VERSION ""

NS_ :

BS_:

BU_: EBS EMS

BO_ 2566836222 DM06: 22 Vector__XXX
 SG_ SPN_High4 : 133|3@1+ (1,0) [0|7] "" Vector__XXX
 SG_ SPN_High3 : 101|3@1+ (1,0) [0|7] "" Vector__XXX
 SG_ SPN_High5 : 165|3@1+ (1,0) [0|7] "" Vector__XXX
 SG_ SPN_High2 : 69|3@1+ (1,0) [0|7] "" Vector__XXX
 SG_ SPN_High1 : 37|3@1+ (1,0) [0|7] "" Vector__XXX
 SG_ SpnConversionMethod1 : 47|1@1+ (1,0) [0|1] "" Vector__XXX
 SG_ SpnConversionMethod5 : 175|1@1+ (1,0) [0|1] "" Vector__XXX
 SG_ SpnConversionMethod4 : 143|1@1+ (1,0) [0|1] "" Vector__XXX
 SG_ SpnConversionMethod3 : 111|1@1+ (1,0) [0|1] "" Vector__XXX
 SG_ SpnConversionMethod2 : 79|1@1+ (1,0) [0|1] "" Vector__XXX
 SG_ OccurenceCount5 : 168|7@1+ (1,0) [0|127] "" Vector__XXX
 SG_ OccurenceCount4 : 136|7@1+ (1,0) [0|127] "" Vector__XXX
 SG_ OccurenceCount3 : 104|7@1+ (1,0) [0|127] "" Vector__XXX
 SG_ OccurenceCount2 : 72|7@1+ (1,0) [0|127] "" Vector__XXX
 SG_ OccurenceCount1 : 40|7@1+ (1,0) [0|127] "" Vector__XXX
 SG_ FMI5 : 160|5@1+ (1,0) [0|31] "" Vector__XXX
 SG_ FMI4 : 128|5@1+ (1,0) [0|31] "" Vector__XXX
 SG_ FMI3 : 96|5@1+ (1,0) [0|31] "" Vector__XXX
 SG_ FMI2 : 64|5@1+ (1,0) [0|31] "" Vector__XXX
 SG_ FMI1 : 32|5@1+ (1,0) [0|31] "" Vector__XXX
 SG_ FlashRedStopLamp : 12|2@1+ (1,0) [0|3] "" Vector__XXX
 SG_ FlashProtectLamp : 8|2@1+ (1,0) [0|3] "" Vector__XXX
 SG_ FlashMalfuncIndicatorLamp : 14|2@1+ (1,0) [0|3] "" Vector__XXX
 SG_ FlashAmberWarningLamp : 10|2@1+ (1,0) [0|3] "" Vector__XXX
 SG_ MalfunctionIndLampStatus : 6|2@1+ (1,0) [0|3] "" Vector__XXX
 SG_ AmberWarningLampStatus : 2|2@1+ (1,0) [0|3] "" Vector__XXX
 SG_ RedStopLampState : 4|2@1+ (1,0) [0|3] "" Vector__XXX
 SG_ ProtectLampStatus : 0|2@1+ (1,0) [0|3] "" Vector__XXX
 SG_ SPN5 : 144|16@1+ (1,0) [0|524287] "" Vector__XXX
 SG_ SPN4 : 112|16@1+ (1,0) [0|524287] "" Vector__XXX
 SG_ SPN3 : 80|16@1+ (1,0) [0|524287] "" Vector__XXX
 SG_ SPN2 : 48|16@1+ (1,0) [0|524287] "" Vector__XXX
 SG_ SPN1 : 16|16@1+ (1,0) [0|524287] "" Vector__XXX

BO_ 2566835966 DM05: 8 Vector__XXX
 SG_ NOxConvertingCatAdsorberStatus : 59|1@1+ (1,0) [0|1] "" Vector__XXX
 SG_ NOxConvertingCatAdsorberSupport : 43|1@1+ (1,0) [0|1] "" Vector__XXX
 SG_ BoostPressureControlSystemStatus : 57|1@1+ (1,0) [0|1] "" Vector__XXX
 SG_ DieselParticulateFilterStatus : 58|1@1+ (1,0) [0|1] "" Vector__XXX
 SG_ NMHCConvertingCatalystStatus : 60|1@1+ (1,0) [0|1] "" Vector__XXX
 SG_ BoostPressureControlSystemSuppor : 41|1@1+ (1,0) [0|1] "" Vector__XXX
 SG_ DieselParticulateFilterSupport : 42|1@1+ (1,0) [0|1] "" Vector__XXX
 SG_ NMHCConvertingCatalystSupport : 44|1@1+ (1,0) [0|1] "" Vector__XXX
 SG_ MisfireMonitoringSupport : 24|1@1+ (1,0) [0|0] "" Vector__XXX
 SG_ OBDCompliance : 16|8@1+ (1,0) [0|250] "" Vector__XXX
 SG_ PreviouslyActiveTroubleCodes : 8|8@1+ (1,0) [0|250] "" Vector__XXX
 SG_ ActiveTroubleCodes : 0|8@1+ (1,0) [0|250] "" Vector__XXX
 SG_ SecondAirSystemMonStatus : 51|1@1+ (1,0) [0|1] "" Vector__XXX
 SG_ EvaporativeSystemMonStatus : 50|1@1+ (1,0) [0|1] "" Vector__XXX
 SG_ ACSystemRefrigerantMonStatus : 52|1@1+ (1,0) [0|1] "" Vector__XXX
 SG_ OxygenSensorHeaterMonStatus : 54|1@1+ (1,0) [0|1] "" Vector__XXX
 SG_ OxygenSensorMonStatus : 53|1@1+ (1,0) [0|1] "" Vector__XXX
 SG_ EGRSystemMonitoringStatus : 55|1@1+ (1,0) [0|1] "" Vector__XXX
 SG_ CatalystMonStatus : 48|1@1+ (1,0) [0|1] "" Vector__XXX
 SG_ ColdStartAidSystemMonStatus : 56|1@1+ (1,0) [0|1] "" Vector__XXX
 SG_ HeatedCatalystMonStatus : 49|1@1+ (1,0) [0|0] "" Vector__XXX
 SG_ CatalystMonSupp : 32|1@1+ (1,0) [0|1] "" Vector__XXX
 SG_ ColdStartAidSystemMonSupp : 40|1@1+ (1,0) [0|1] "" Vector__XXX
 SG_ HeatedCatalystMonSupp : 33|1@1+ (1,0) [0|0] "" Vector__XXX
 SG_ EvaporativeSystemMonSupp : 34|1@1+ (1,0) [0|1] "" Vector__XXX
 SG_ SecondAirSystemMonSupp : 35|1@1+ (1,0) [0|1] "" Vector__XXX
 SG_ ACSystemRefrigerantMonSupp : 36|1@1+ (1,0) [0|1] "" Vector__XXX
 SG_ OxygenSensorMonSupp : 37|1@1+ (1,0) [0|1] "" Vector__XXX
 SG_ OxygenSensorHeaterMonSupp : 38|1@1+ (1,0) [0|1] "" Vector__XXX
 SG_ EGRSystemMonitoringSupp : 39|1@1+ (1,0) [0|1] "" Vector__XXX
 SG_ MisfireMonitoringStatus : 28|1@1+ (1,0) [0|0] "" Vector__XXX
 SG_ ComprehensiveCompMonStatus : 30|1@1+ (1,0) [0|1] "" Vector__XXX
 SG_ FuelSystemMonitoringStatus : 29|1@1+ (1,0) [0|1] "" Vector__XXX
 SG_ ComprehensiveComponentMonSupp : 26|1@1+ (1,0) [0|0] "" Vector__XXX
 SG_ FuelSystemMonitoringSupport : 25|1@1+ (1,0) [0|1] "" Vector__XXX

BO_ 2566835710 DM04: 13 Vector__XXX
 SG_ SpnConversionMethod : 39|1@1+ (1,0) [0|1] "" Vector__XXX
 SG_ OccurenceCount : 32|7@1+ (1,0) [0|127] "" Vector__XXX
 SG_ SPN_High : 29|3@1+ (1,0) [0|7] "" Vector__XXX
 SG_ FMI : 24|5@1+ (1,0) [0|31] "" Vector__XXX
 SG_ EngineIntakeManifold1Pressure : 48|8@1+ (2,0) [0|500] "kPa" Vector__XXX
 SG_ FreezeFrameLength : 0|8@1+ (1,0) [0|255] "" Vector__XXX
 SG_ Speed : 56|16@1+ (0.125,0) [0|8031.875] "rpm" Vector__XXX
 SG_ TorqueMode : 40|4@1+ (1,0) [0|15] "" Vector__XXX
 SG_ WheelBasedVS : 88|16@1+ (0.00390625,0) [0|250.99609375] "km/h" Vector__XXX
 SG_ PercentLoadAtCurrentSpeed : 72|8@1+ (1,0) [0|125] "%" Vector__XXX
 SG_ CoolantTemperature : 80|8@1+ (1,-40) [-40|210] "°C" Vector__XXX
 SG_ SPN : 8|16@1+ (1,0) [0|524287] "" Vector__XXX

BO_ 2566835454 DM03: 0 Vector__XXX

BO_ 2566835198 DM02: 22 Vector__XXX
 SG_ SPN_High4 : 133|3@1+ (1,0) [0|7] "" Vector__XXX
 SG_ SPN_High3 : 101|3@1+ (1,0) [0|7] "" Vector__XXX
 SG_ SPN_High5 : 165|3@1+ (1,0) [0|7] "" Vector__XXX
 SG_ SPN_High2 : 69|3@1+ (1,0) [0|7] "" Vector__XXX
 SG_ SPN_High1 : 37|3@1+ (1,0) [0|7] "" Vector__XXX
 SG_ SpnConversionMethod1 : 47|1@1+ (1,0) [0|1] "" Vector__XXX
 SG_ SpnConversionMethod5 : 175|1@1+ (1,0) [0|1] "" Vector__XXX
 SG_ SpnConversionMethod4 : 143|1@1+ (1,0) [0|1] "" Vector__XXX
 SG_ SpnConversionMethod3 : 111|1@1+ (1,0) [0|1] "" Vector__XXX
 SG_ SpnConversionMethod2 : 79|1@1+ (1,0) [0|1] "" Vector__XXX
 SG_ OccurenceCount5 : 168|7@1+ (1,0) [0|127] "" Vector__XXX
 SG_ OccurenceCount4 : 136|7@1+ (1,0) [0|127] "" Vector__XXX
 SG_ OccurenceCount3 : 104|7@1+ (1,0) [0|127] "" Vector__XXX
 SG_ OccurenceCount2 : 72|7@1+ (1,0) [0|127] "" Vector__XXX
 SG_ OccurenceCount1 : 40|7@1+ (1,0) [0|127] "" Vector__XXX
 SG_ FMI5 : 160|5@1+ (1,0) [0|31] "" Vector__XXX
 SG_ FMI4 : 128|5@1+ (1,0) [0|31] "" Vector__XXX
 SG_ FMI3 : 96|5@1+ (1,0) [0|31] "" Vector__XXX
 SG_ FMI2 : 64|5@1+ (1,0) [0|31] "" Vector__XXX
 SG_ FMI1 : 32|5@1+ (1,0) [0|31] "" Vector__XXX
 SG_ FlashRedStopLamp : 12|2@1+ (1,0) [0|3] "" Vector__XXX
 SG_ FlashProtectLamp : 8|2@1+ (1,0) [0|3] "" Vector__XXX
 SG_ FlashMalfuncIndicatorLamp : 14|2@1+ (1,0) [0|3] "" Vector__XXX
 SG_ FlashAmberWarningLamp : 10|2@1+ (1,0) [0|3] "" Vector__XXX
 SG_ MalfunctionIndLampStatus : 6|2@1+ (1,0) [0|3] "" Vector__XXX
 SG_ AmberWarningLampStatus : 2|2@1+ (1,0) [0|3] "" Vector__XXX
 SG_ RedStopLampState : 4|2@1+ (1,0) [0|3] "" Vector__XXX
 SG_ ProtectLampStatus : 0|2@1+ (1,0) [0|3] "" Vector__XXX
 SG_ SPN5 : 144|16@1+ (1,0) [0|524287] "" Vector__XXX
 SG_ SPN4 : 112|16@1+ (1,0) [0|524287] "" Vector__XXX
 SG_ SPN3 : 80|16@1+ (1,0) [0|524287] "" Vector__XXX
 SG_ SPN2 : 48|16@1+ (1,0) [0|524287] "" Vector__XXX
 SG_ SPN1 : 16|16@1+ (1,0) [0|524287] "" Vector__XXX

BO_ 2566834942 DM01: 22 Vector__XXX
 SG_ SPN_High4 : 133|3@1+ (1,0) [0|7] "" Vector__XXX
 SG_ SPN_High3 : 101|3@1+ (1,0) [0|7] "" Vector__XXX
 SG_ SPN_High5 : 165|3@1+ (1,0) [0|7] "" Vector__XXX
 SG_ SPN_High2 : 69|3@1+ (1,0) [0|7] "" Vector__XXX
 SG_ SPN_High1 : 37|3@1+ (1,0) [0|7] "" Vector__XXX
 SG_ SpnConversionMethod1 : 47|1@1+ (1,0) [0|1] "" Vector__XXX
 SG_ SpnConversionMethod5 : 175|1@1+ (1,0) [0|1] "" Vector__XXX
 SG_ SpnConversionMethod4 : 143|1@1+ (1,0) [0|1] "" Vector__XXX
 SG_ SpnConversionMethod3 : 111|1@1+ (1,0) [0|1] "" Vector__XXX
 SG_ SpnConversionMethod2 : 79|1@1+ (1,0) [0|1] "" Vector__XXX
 SG_ OccurenceCount5 : 168|7@1+ (1,0) [0|127] "" Vector__XXX
 SG_ OccurenceCount4 : 136|7@1+ (1,0) [0|127] "" Vector__XXX
 SG_ OccurenceCount3 : 104|7@1+ (1,0) [0|127] "" Vector__XXX
 SG_ OccurenceCount2 : 72|7@1+ (1,0) [0|127] "" Vector__XXX
 SG_ OccurenceCount1 : 40|7@1+ (1,0) [0|127] "" Vector__XXX
 SG_ FMI5 : 160|5@1+ (1,0) [0|31] "" Vector__XXX
 SG_ FMI4 : 128|5@1+ (1,0) [0|31] "" Vector__XXX
 SG_ FMI3 : 96|5@1+ (1,0) [0|31] "" Vector__XXX
 SG_ FMI2 : 64|5@1+ (1,0) [0|31] "" Vector__XXX
 SG_ FMI1 : 32|5@1+ (1,0) [0|31] "" Vector__XXX
 SG_ FlashRedStopLamp : 12|2@1+ (1,0) [0|3] "" Vector__XXX
 SG_ FlashProtectLamp : 8|2@1+ (1,0) [0|3] "" Vector__XXX
 SG_ FlashMalfuncIndicatorLamp : 14|2@1+ (1,0) [0|3] "" Vector__XXX
 SG_ FlashAmberWarningLamp : 10|2@1+ (1,0) [0|3] "" Vector__XXX
 SG_ MalfunctionIndLampStatus : 6|2@1+ (1,0) [0|3] "" Vector__XXX
 SG_ AmberWarningLampStatus : 2|2@1+ (1,0) [0|3] "" Vector__XXX
 SG_ RedStopLampState : 4|2@1+ (1,0) [0|3] "" Vector__XXX
 SG_ ProtectLampStatus : 0|2@1+ (1,0) [0|3] "" Vector__XXX
 SG_ SPN5 : 144|16@1+ (1,0) [0|524287] "" Vector__XXX
 SG_ SPN4 : 112|16@1+ (1,0) [0|524287] "" Vector__XXX
 SG_ SPN3 : 80|16@1+ (1,0) [0|524287] "" Vector__XXX
 SG_ SPN2 : 48|16@1+ (1,0) [0|524287] "" Vector__XXX
 SG_ SPN1 : 16|16@1+ (1,0) [0|524287] "" Vector__XXX

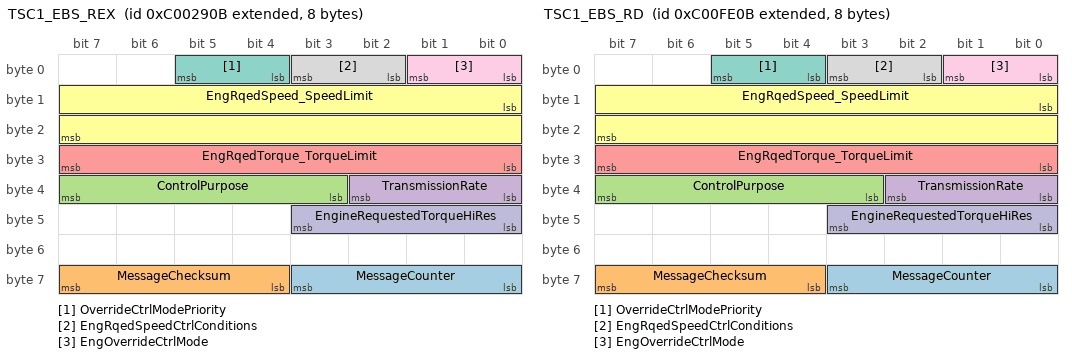
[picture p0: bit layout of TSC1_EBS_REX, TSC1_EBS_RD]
BO_ 2348820747 TSC1_EBS_REX: 8 EBS
 SG_ MessageCounter : 56|4@1+ (1,0) [0|15] "" Vector__XXX
 SG_ MessageChecksum : 60|4@1+ (1,0) [0|15] "" Vector__XXX
 SG_ ControlPurpose : 35|5@1+ (1,0) [0|31] "" Vector__XXX
 SG_ TransmissionRate : 32|3@1+ (1,0) [0|7] "" Vector__XXX
 SG_ EngRqedTorque_TorqueLimit : 24|8@1+ (1,-125) [-125|125] "%" Vector__XXX
 SG_ EngRqedSpeed_SpeedLimit : 8|16@1+ (0.125,0) [0|8031.875] "RPM" Vector__XXX
 SG_ OverrideCtrlModePriority : 4|2@1+ (1,0) [0|3] "" Vector__XXX
 SG_ EngRqedSpeedCtrlConditions : 2|2@1+ (1,0) [0|3] "" Vector__XXX
 SG_ EngOverrideCtrlMode : 0|2@1+ (1,0) [0|3] "" Vector__XXX
 SG_ EngineRequestedTorqueHiRes : 40|4@1+ (0.125,0) [0|0.875] "%" Vector__XXX

BO_ 2348875275 TSC1_EBS_RD: 8 EBS
 SG_ MessageCounter : 56|4@1+ (1,0) [0|15] "" Vector__XXX
 SG_ MessageChecksum : 60|4@1+ (1,0) [0|15] "" Vector__XXX
 SG_ ControlPurpose : 35|5@1+ (1,0) [0|31] "" Vector__XXX
 SG_ TransmissionRate : 32|3@1+ (1,0) [0|7] "" Vector__XXX
 SG_ EngRqedTorque_TorqueLimit : 24|8@1+ (1,-125) [-125|125] "%" Vector__XXX
 SG_ EngRqedSpeed_SpeedLimit : 8|16@1+ (0.125,0) [0|8031.875] "RPM" Vector__XXX
 SG_ OverrideCtrlModePriority : 4|2@1+ (1,0) [0|3] "" Vector__XXX
 SG_ EngRqedSpeedCtrlConditions : 2|2@1+ (1,0) [0|3] "" Vector__XXX
 SG_ EngOverrideCtrlMode : 0|2@1+ (1,0) [0|3] "" Vector__XXX
 SG_ EngineRequestedTorqueHiRes : 40|4@1+ (0.125,0) [0|0.875] "%" Vector__XXX

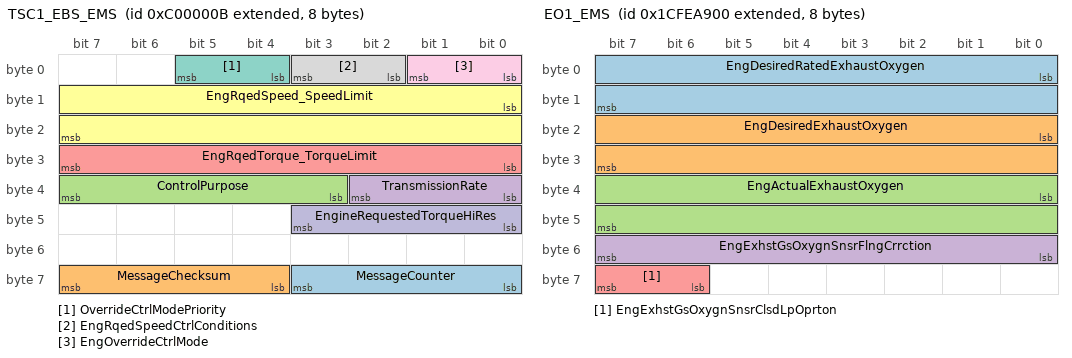
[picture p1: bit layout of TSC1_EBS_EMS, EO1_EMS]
BO_ 2348810251 TSC1_EBS_EMS: 8 EBS
 SG_ MessageCounter : 56|4@1+ (1,0) [0|15] "" Vector__XXX
 SG_ MessageChecksum : 60|4@1+ (1,0) [0|15] "" Vector__XXX
 SG_ ControlPurpose : 35|5@1+ (1,0) [0|31] ""  EMS
 SG_ TransmissionRate : 32|3@1+ (1,0) [0|7] "" Vector__XXX
 SG_ EngRqedTorque_TorqueLimit : 24|8@1+ (1,-125) [-125|125] "%"  EMS
 SG_ EngRqedSpeed_SpeedLimit : 8|16@1+ (0.125,0) [0|8031.875] "RPM"  EMS
 SG_ OverrideCtrlModePriority : 4|2@1+ (1,0) [0|3] ""  EMS
 SG_ EngRqedSpeedCtrlConditions : 2|2@1+ (1,0) [0|3] "" Vector__XXX
 SG_ EngOverrideCtrlMode : 0|2@1+ (1,0) [0|3] ""  EMS
 SG_ EngineRequestedTorqueHiRes : 40|4@1+ (0.125,0) [0|0.875] "%" Vector__XXX

BO_ 2632943012 CAPL_MSG: 1785 Vector__XXX

BO_ 2633935104 EO1_EMS: 8 EMS
 SG_ EngDesiredRatedExhaustOxygen : 0|16@1+ (0.0025,0) [0|160.6375] "%" Vector__XXX
 SG_ EngDesiredExhaustOxygen : 16|16@1+ (0.0025,0) [0|160.6375] "%" Vector__XXX
 SG_ EngActualExhaustOxygen : 32|16@1+ (0.0025,0) [0|160.6375] "%" Vector__XXX
 SG_ EngExhstGsOxygnSnsrFlngCrrction : 48|8@1+ (1,-125) [-125|125] "%" Vector__XXX
 SG_ EngExhstGsOxygnSnsrClsdLpOprton : 62|2@1+ (1,0) [0|3] "" Vector__XXX

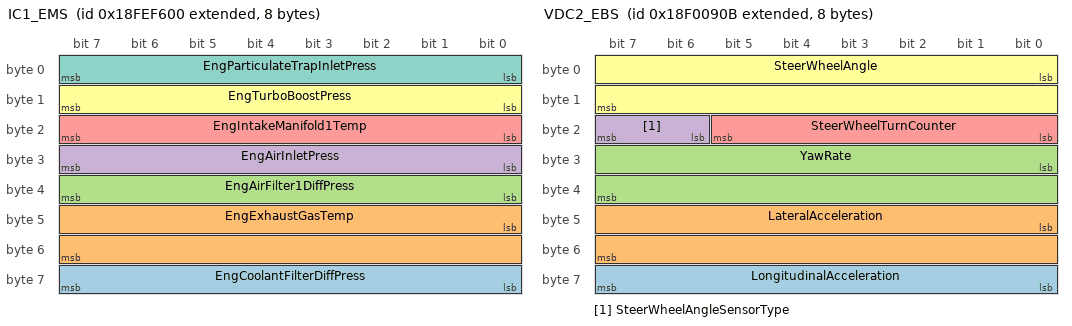
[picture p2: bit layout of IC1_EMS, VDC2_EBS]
BO_ 2566845952 IC1_EMS: 8 EMS
 SG_ EngCoolantFilterDiffPress : 56|8@1+ (0.5,0) [0|125] "kPa" Vector__XXX
 SG_ EngExhaustGasTemp : 40|16@1+ (0.03125,-273) [-273|1735] "°C" Vector__XXX
 SG_ EngAirFilter1DiffPress : 32|8@1+ (0.05,0) [0|12.5] "kPa" Vector__XXX
 SG_ EngAirInletPress : 24|8@1+ (2,0) [0|500] "kPa" Vector__XXX
 SG_ EngIntakeManifold1Temp : 16|8@1+ (1,-40) [-40|210] "°C" Vector__XXX
 SG_ EngTurboBoostPress : 8|8@1+ (2,0) [0|500] "kPa" Vector__XXX
 SG_ EngParticulateTrapInletPress : 0|8@1+ (0.5,0) [0|125] "kPa" Vector__XXX

BO_ 2566841600 HOURS_EMS: 8 EMS
 SG_ EngTotalRevolutions : 32|32@1+ (1000,0) [0|4211081215000] "rev" Vector__XXX
 SG_ EngTotalHoursOfOperation : 0|32@1+ (0.05,0) [0|210554060.75] "hr" Vector__XXX

BO_ 2566843392 VI_EMS: 8 EMS
 SG_ VehicleIdentificationNumber : 0|8@1+ (1,0) [0|255] "" Vector__XXX

BO_ 2566832384 VDHR_EMS: 8 EMS
 SG_ HighResolutionTripDistance : 32|32@1+ (0.005,0) [0|21055406] "km" Vector__XXX
 SG_ HghRslutionTotalVehicleDistance : 0|32@1+ (0.005,0) [0|21055406] "km" Vector__XXX

BO_ 2565867787 VDC2_EBS: 8 EBS
 SG_ LongitudinalAcceleration : 56|8@1+ (0.1,-12.5) [-12.5|12.5] "m/s²" Vector__XXX
 SG_ LateralAcceleration : 40|16@1+ (0.000488281,-15.687) [-15.687|15.687] "m/s²" Vector__XXX
 SG_ YawRate : 24|16@1+ (0.00012207,-3.92) [-3.92|3.92] "rad/s" Vector__XXX
 SG_ SteerWheelAngleSensorType : 22|2@1+ (1,0) [0|3] "" Vector__XXX
 SG_ SteerWheelTurnCounter : 16|6@1+ (1,-32) [-32|29] "turns" Vector__XXX
 SG_ SteerWheelAngle : 0|16@1+ (0.000976563,-31.374) [-31.374|31.374] "rad" Vector__XXX

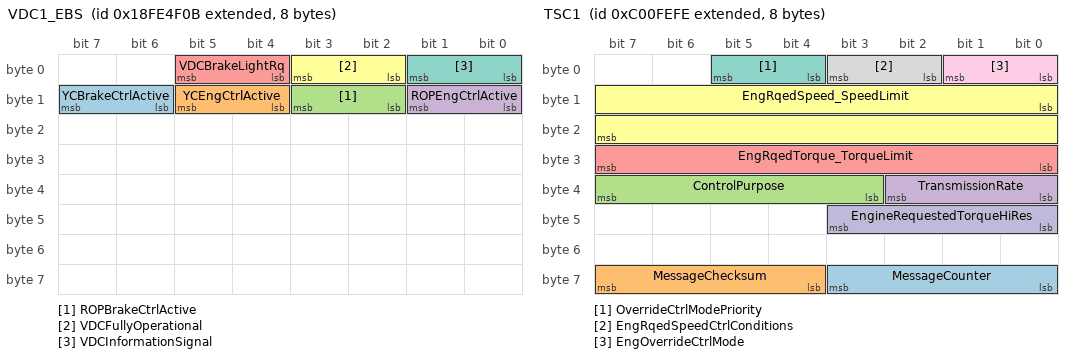
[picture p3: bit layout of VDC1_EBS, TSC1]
BO_ 2566803211 VDC1_EBS: 8 EBS
 SG_ YCBrakeCtrlActive : 14|2@1+ (1,0) [0|3] "" Vector__XXX
 SG_ YCEngCtrlActive : 12|2@1+ (1,0) [0|3] "" Vector__XXX
 SG_ ROPBrakeCtrlActive : 10|2@1+ (1,0) [0|3] "" Vector__XXX
 SG_ ROPEngCtrlActive : 8|2@1+ (1,0) [0|3] "" Vector__XXX
 SG_ VDCBrakeLightRq : 4|2@1+ (1,0) [0|3] "" Vector__XXX
 SG_ VDCFullyOperational : 2|2@1+ (1,0) [0|3] "" Vector__XXX
 SG_ VDCInformationSignal : 0|2@1+ (1,0) [0|3] "" Vector__XXX

BO_ 2566840320 VD_EMS: 8 EMS
 SG_ TotalVehicleDistance : 32|32@1+ (0.125,0) [0|526385151.9] "km" Vector__XXX
 SG_ TripDistance : 0|32@1+ (0.125,0) [0|526385151.9] "km" Vector__XXX

BO_ 2348875518 TSC1: 8 Vector__XXX
 SG_ MessageCounter : 56|4@1+ (1,0) [0|15] "" Vector__XXX
 SG_ MessageChecksum : 60|4@1+ (1,0) [0|15] "" Vector__XXX
 SG_ ControlPurpose : 35|5@1+ (1,0) [0|31] "" Vector__XXX
 SG_ TransmissionRate : 32|3@1+ (1,0) [0|7] "" Vector__XXX
 SG_ EngRqedTorque_TorqueLimit : 24|8@1+ (1,-125) [-125|125] "%" Vector__XXX
 SG_ EngRqedSpeed_SpeedLimit : 8|16@1+ (0.125,0) [0|8031.875] "RPM" Vector__XXX
 SG_ OverrideCtrlModePriority : 4|2@1+ (1,0) [0|3] "" Vector__XXX
 SG_ EngRqedSpeedCtrlConditions : 2|2@1+ (1,0) [0|3] "" Vector__XXX
 SG_ EngOverrideCtrlMode : 0|2@1+ (1,0) [0|3] "" Vector__XXX
 SG_ EngineRequestedTorqueHiRes : 40|4@1+ (0.125,0) [0|0.875] "%" Vector__XXX

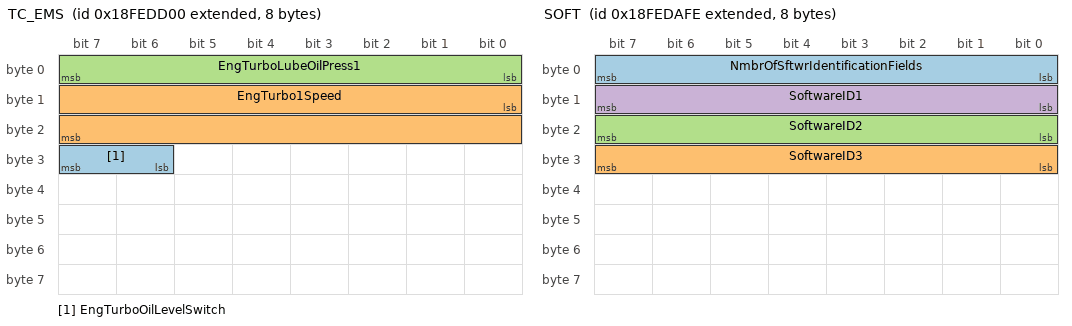
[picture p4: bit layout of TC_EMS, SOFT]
BO_ 2566839552 TC_EMS: 8 EMS
 SG_ EngTurboOilLevelSwitch : 30|2@1+ (1,0) [0|3] "" Vector__XXX
 SG_ EngTurbo1Speed : 8|16@1+ (4,0) [0|257020] "RPM" Vector__XXX
 SG_ EngTurboLubeOilPress1 : 0|8@1+ (4,0) [0|1000] "kPa" Vector__XXX

BO_ 2566839038 SOFT: 8 EBS
 SG_ NmbrOfSftwrIdentificationFields : 0|8@1+ (1,0) [0|250] "steps" Vector__XXX
 SG_ SoftwareID3 : 24|8@1+ (1,0) [0|255] "" Vector__XXX
 SG_ SoftwareID2 : 16|8@1+ (1,0) [0|255] "" Vector__XXX
 SG_ SoftwareID1 : 8|8@1+ (1,0) [0|255] "" Vector__XXX

BO_ 2566841344 SHUTDN_EMS: 8 EMS
 SG_ EngOverspeedTest : 54|2@1+ (1,0) [0|3] "" Vector__XXX
 SG_ EngAirShutoffCmdStatus : 52|2@1+ (1,0) [0|3] "" Vector__XXX
 SG_ EngAlarmOutputCmdStatus : 50|2@1+ (1,0) [0|3] "" Vector__XXX
 SG_ EngAlarmAcknowledge : 48|2@1+ (1,0) [0|3] "" Vector__XXX
 SG_ EngProtectionSystemConfig : 46|2@1+ (1,0) [0|3] "" Vector__XXX
 SG_ EngProtectionSystemTimerState : 38|2@1+ (1,0) [0|3] "" Vector__XXX
 SG_ EngPrtectionSystemTimerOverride : 36|2@1+ (1,0) [0|3] "" Vector__XXX
 SG_ EngPrtctnSystmApprchingShutdown : 34|2@1+ (1,0) [0|3] "" Vector__XXX
 SG_ EngPrtctionSystemHasShutdownEng : 32|2@1+ (1,0) [0|3] "" Vector__XXX
 SG_ EngWaitToStartLamp : 24|2@1+ (1,0) [0|3] "" Vector__XXX
 SG_ RefrigerantHighPressSwitch : 20|2@1+ (1,0) [0|3] "" Vector__XXX
 SG_ RefrigerantLowPressSwitch : 18|2@1+ (1,0) [0|3] "" Vector__XXX
 SG_ A_CHighPressFanSwitch : 16|2@1+ (1,0) [0|3] "" Vector__XXX
 SG_ EngIdleShutdownTimerFunction : 14|2@1+ (1,0) [0|3] "" Vector__XXX
 SG_ EngIdleShutdownTimerState : 6|2@1+ (1,0) [0|3] "" Vector__XXX
 SG_ EngIdleShutdownTimerOverride : 4|2@1+ (1,0) [0|3] "" Vector__XXX
 SG_ EngIdleShutdownDriverAlertMode : 2|2@1+ (1,0) [0|3] "" Vector__XXX
 SG_ EngIdleShutdownHasShutdownEng : 0|2@1+ (1,0) [0|3] "" Vector__XXX

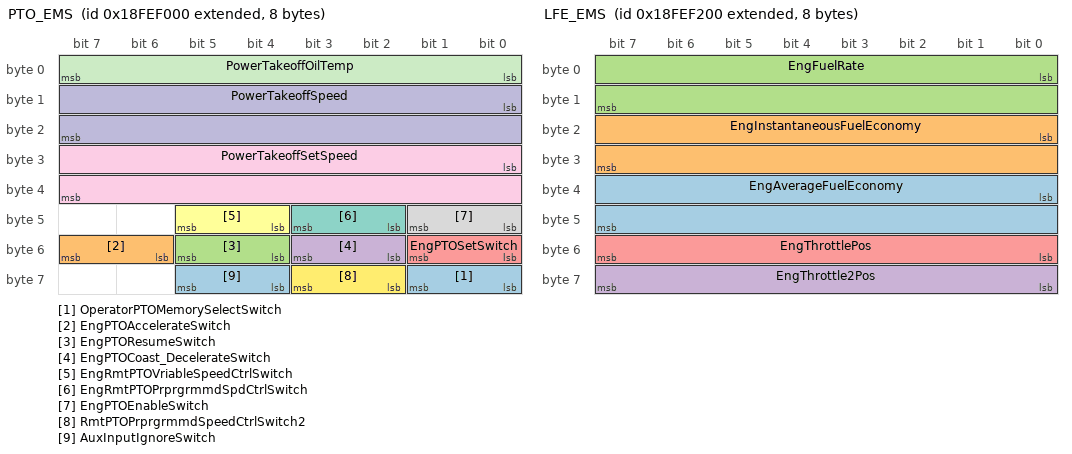
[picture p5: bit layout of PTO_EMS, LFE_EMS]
BO_ 2566844416 PTO_EMS: 8 EMS
 SG_ OperatorPTOMemorySelectSwitch : 56|2@1+ (1,0) [0|3] "" Vector__XXX
 SG_ EngPTOAccelerateSwitch : 54|2@1+ (1,0) [0|3] "" Vector__XXX
 SG_ EngPTOResumeSwitch : 52|2@1+ (1,0) [0|3] "" Vector__XXX
 SG_ EngPTOCoast_DecelerateSwitch : 50|2@1+ (1,0) [0|3] "" Vector__XXX
 SG_ EngPTOSetSwitch : 48|2@1+ (1,0) [0|3] "" Vector__XXX
 SG_ EngRmtPTOVriableSpeedCtrlSwitch : 44|2@1+ (1,0) [0|3] "" Vector__XXX
 SG_ EngRmtPTOPrprgrmmdSpdCtrlSwitch : 42|2@1+ (1,0) [0|3] "" Vector__XXX
 SG_ EngPTOEnableSwitch : 40|2@1+ (1,0) [0|3] "" Vector__XXX
 SG_ PowerTakeoffSetSpeed : 24|16@1+ (0.125,0) [0|8031.875] "RPM" Vector__XXX
 SG_ PowerTakeoffSpeed : 8|16@1+ (0.125,0) [0|8031.875] "RPM" Vector__XXX
 SG_ PowerTakeoffOilTemp : 0|8@1+ (1,-40) [-40|210] "°C" Vector__XXX
 SG_ RmtPTOPrprgrmmdSpeedCtrlSwitch2 : 58|2@1+ (1,0) [0|3] "" Vector__XXX
 SG_ AuxInputIgnoreSwitch : 60|2@1+ (1,0) [0|3] "" Vector__XXX

BO_ 2566844928 LFE_EMS: 8 EMS
 SG_ EngAverageFuelEconomy : 32|16@1+ (0.001953125,0) [0|125.5] "km/L" Vector__XXX
 SG_ EngInstantaneousFuelEconomy : 16|16@1+ (0.001953125,0) [0|125.5] "km/L" Vector__XXX
 SG_ EngFuelRate : 0|16@1+ (0.05,0) [0|3212.75] "L/hr" Vector__XXX
 SG_ EngThrottle2Pos : 56|8@1+ (0.4,0) [0|100] "%" Vector__XXX
 SG_ EngThrottlePos : 48|8@1+ (0.4,0) [0|100] "%" Vector__XXX

BO_ 2566842624 LFC_EMS: 8 EMS
 SG_ EngTotalFuelUsed : 32|32@1+ (0.5,0) [0|2105540607.5] "L" Vector__XXX
 SG_ EngTripFuel : 0|32@1+ (0.5,0) [0|2105540607.5] "L" Vector__XXX

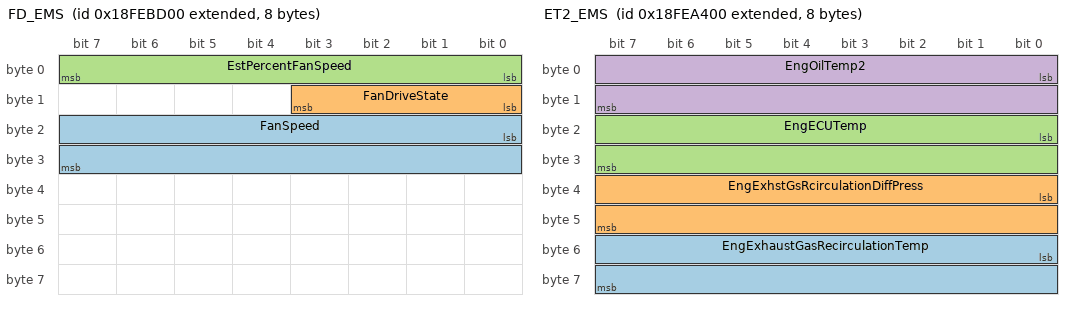
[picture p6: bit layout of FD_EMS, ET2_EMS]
BO_ 2566831360 FD_EMS: 8 EMS
 SG_ FanSpeed : 16|16@1+ (0.125,0) [0|8031.875] "RPM" Vector__XXX
 SG_ FanDriveState : 8|4@1+ (1,0) [0|15] "" Vector__XXX
 SG_ EstPercentFanSpeed : 0|8@1+ (0.4,0) [0|100] "%" Vector__XXX

BO_ 2566824960 ET2_EMS: 8 EMS
 SG_ EngExhaustGasRecirculationTemp : 48|16@1+ (0.03125,-273) [-273|1735] "°C" Vector__XXX
 SG_ EngExhstGsRcirculationDiffPress : 32|16@1+ (0.0078125,-250) [-250|251.99] "kPa" Vector__XXX
 SG_ EngECUTemp : 16|16@1+ (0.03125,-273) [-273|1735] "°C" Vector__XXX
 SG_ EngOilTemp2 : 0|16@1+ (0.03125,-273) [-273|1735] "°C" Vector__XXX

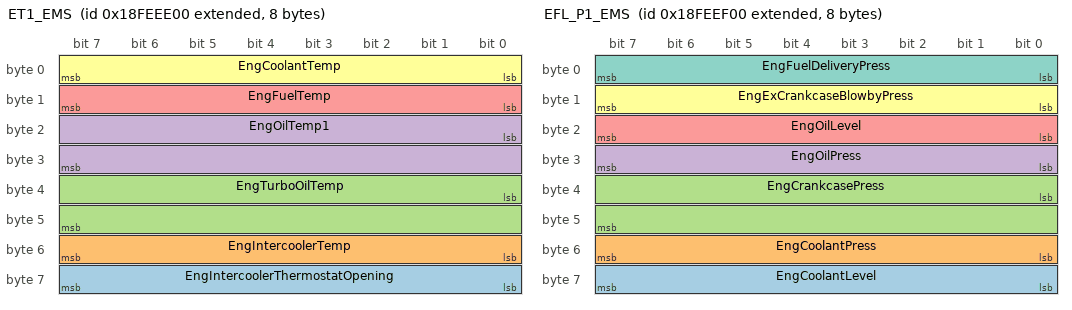
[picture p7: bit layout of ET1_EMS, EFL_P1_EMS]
BO_ 2566843904 ET1_EMS: 8 EMS
 SG_ EngIntercoolerThermostatOpening : 56|8@1+ (0.4,0) [0|100] "%" Vector__XXX
 SG_ EngIntercoolerTemp : 48|8@1+ (1,-40) [-40|210] "°C" Vector__XXX
 SG_ EngTurboOilTemp : 32|16@1+ (0.03125,-273) [-273|1735] "°C" Vector__XXX
 SG_ EngOilTemp1 : 16|16@1+ (0.03125,-273) [-273|1735] "°C" Vector__XXX
 SG_ EngFuelTemp : 8|8@1+ (1,-40) [-40|210] "°C" Vector__XXX
 SG_ EngCoolantTemp : 0|8@1+ (1,-40) [-40|210] "°C" Vector__XXX

BO_ 2566844160 EFL_P1_EMS: 8 EMS
 SG_ EngCoolantLevel : 56|8@1+ (0.4,0) [0|100] "%" Vector__XXX
 SG_ EngCoolantPress : 48|8@1+ (2,0) [0|500] "kPa" Vector__XXX
 SG_ EngCrankcasePress : 32|16@1+ (0.0078125,-250) [-250|251.99] "kPa" Vector__XXX
 SG_ EngOilPress : 24|8@1+ (4,0) [0|1000] "kPa" Vector__XXX
 SG_ EngOilLevel : 16|8@1+ (0.4,0) [0|100] "%" Vector__XXX
 SG_ EngExCrankcaseBlowbyPress : 8|8@1+ (0.05,0) [0|12.5] "kPa" Vector__XXX
 SG_ EngFuelDeliveryPress : 0|8@1+ (4,0) [0|1000] "kPa" Vector__XXX

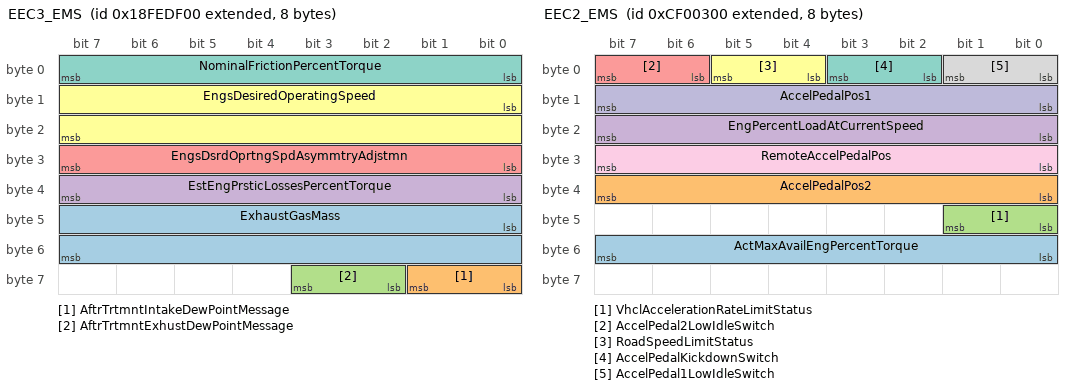
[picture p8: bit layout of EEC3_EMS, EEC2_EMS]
BO_ 2566840064 EEC3_EMS: 8 EMS
 SG_ ExhaustGasMass : 40|16@1+ (2,0) [0|128510] "kg" Vector__XXX
 SG_ AftrTrtmntIntakeDewPointMessage : 56|2@1+ (1,0) [0|3] "" Vector__XXX
 SG_ AftrTrtmntExhustDewPointMessage : 58|2@1+ (1,0) [0|3] "" Vector__XXX
 SG_ EstEngPrsticLossesPercentTorque : 32|8@1+ (1,-125) [-125|125] "%" Vector__XXX
 SG_ EngsDsrdOprtngSpdAsymmtryAdjstmn : 24|8@1+ (1,0) [0|250] "" Vector__XXX
 SG_ EngsDesiredOperatingSpeed : 8|16@1+ (0.125,0) [0|8031.875] "RPM" Vector__XXX
 SG_ NominalFrictionPercentTorque : 0|8@1+ (1,-125) [-125|125] "%"  EBS

BO_ 2364539648 EEC2_EMS: 8 EMS
 SG_ ActMaxAvailEngPercentTorque : 48|8@1+ (0.4,0) [0|100] "%" Vector__XXX
 SG_ AccelPedalPos2 : 32|8@1+ (0.4,0) [0|100] "%" Vector__XXX
 SG_ VhclAccelerationRateLimitStatus : 40|2@1+ (1,0) [0|3] "" Vector__XXX
 SG_ EngPercentLoadAtCurrentSpeed : 16|8@1+ (1,0) [0|250] "%" Vector__XXX
 SG_ AccelPedal2LowIdleSwitch : 6|2@1+ (1,0) [0|3] "" Vector__XXX
 SG_ RoadSpeedLimitStatus : 4|2@1+ (1,0) [0|3] "" Vector__XXX
 SG_ AccelPedalKickdownSwitch : 2|2@1+ (1,0) [0|3] "" Vector__XXX
 SG_ AccelPedal1LowIdleSwitch : 0|2@1+ (1,0) [0|3] "" Vector__XXX
 SG_ RemoteAccelPedalPos : 24|8@1+ (0.4,0) [0|100] "%" Vector__XXX
 SG_ AccelPedalPos1 : 8|8@1+ (0.4,0) [0|100] "%"  EBS

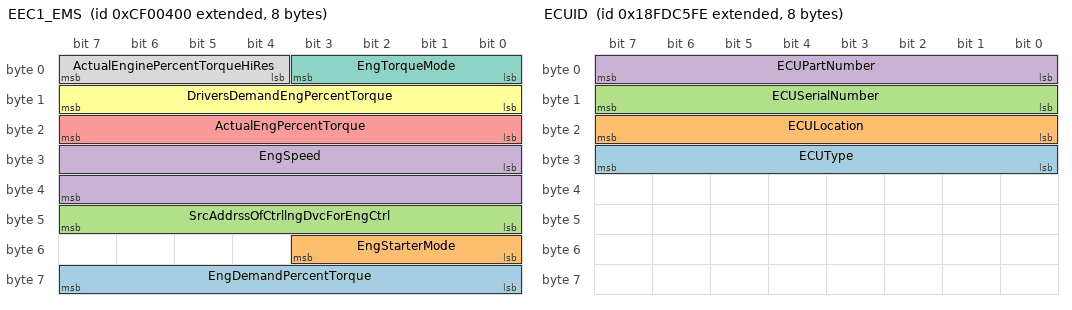
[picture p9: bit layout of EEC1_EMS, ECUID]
BO_ 2364539904 EEC1_EMS: 8 EMS
 SG_ EngDemandPercentTorque : 56|8@1+ (1,-125) [-125|125] "%" Vector__XXX
 SG_ EngStarterMode : 48|4@1+ (1,0) [0|15] "" Vector__XXX
 SG_ SrcAddrssOfCtrllngDvcForEngCtrl : 40|8@1+ (1,0) [0|255] "" Vector__XXX
 SG_ EngSpeed : 24|16@1+ (0.125,0) [0|8031.875] "RPM"  EBS
 SG_ ActualEngPercentTorque : 16|8@1+ (1,-125) [-125|125] "%"  EBS
 SG_ DriversDemandEngPercentTorque : 8|8@1+ (1,-125) [-125|125] "%"  EBS
 SG_ EngTorqueMode : 0|4@1+ (1,0) [0|15] ""  EBS
 SG_ ActualEnginePercentTorqueHiRes : 4|4@1+ (0.125,0) [0|0.875] "%" Vector__XXX

BO_ 2566768126 ECUID: 8 EBS
 SG_ ECUType : 24|8@1+ (1,0) [0|255] "" Vector__XXX
 SG_ ECULocation : 16|8@1+ (1,0) [0|255] "" Vector__XXX
 SG_ ECUSerialNumber : 8|8@1+ (1,0) [0|255] "" Vector__XXX
 SG_ ECUPartNumber : 0|8@1+ (1,0) [0|255] "" Vector__XXX

BO_ 2566841088 EC_EMS: 39 EMS
 SG_ SupportTSC1CtrlPurposeGroup4Of4 : 304|8@1+ (1,0) [0|255] "" Vector__XXX
 SG_ SupportVariableRateTSC1Message : 272|8@1+ (1,0) [0|255] "" Vector__XXX
 SG_ SupportTSC1CtrlPurposeGroup3Of4 : 296|8@1+ (1,0) [0|255] "" Vector__XXX
 SG_ SupportTSC1CtrlPurposeGroup2Of4 : 288|8@1+ (1,0) [0|255] "" Vector__XXX
 SG_ SupportTSC1CtrlPurposeGroup1Of4 : 280|8@1+ (1,0) [0|255] "" Vector__XXX
 SG_ EngDefaultTorqueLimit : 256|16@1+ (1,0) [0|64255] "Nm" Vector__XXX
 SG_ EngMomentOfInertia : 240|16@1+ (0.004,0) [0|257.02] "kg-m²" Vector__XXX
 SG_ EngExRngRqdSpdCtrlRngUpperLimit : 224|16@1+ (0.125,0) [0|8031.875] "RPM" Vector__XXX
 SG_ EngRqdTorqueCtrlRangeUpperLimit : 216|8@1+ (1,-125) [-125|125] "%" Vector__XXX
 SG_ EngRqdTorqueCtrlRangeLowerLimit : 208|8@1+ (1,-125) [-125|125] "%" Vector__XXX
 SG_ EngRqedSpeedCtrlRangeUpperLimit : 200|8@1+ (10,0) [0|2500] "RPM" Vector__XXX
 SG_ EngRqedSpeedCtrlRangeLowerLimit : 192|8@1+ (10,0) [0|2500] "RPM" Vector__XXX
 SG_ EngMxMomentaryOverrideTimeLimit : 184|8@1+ (0.1,0) [0|25] "sec" Vector__XXX
 SG_ EngMxMmntaryOverrideSpeedPoint7 : 168|16@1+ (0.125,0) [0|8031.875] "RPM" Vector__XXX
 SG_ EngReferenceTorque : 152|16@1+ (1,0) [0|64255] "Nm"  EBS
 SG_ EngSpeedAtHighIdlePoint6 : 120|16@1+ (0.125,0) [0|8031.875] "RPM" Vector__XXX
 SG_ EngGainOfEndspeedGovernor : 136|16@1+ (0.00078125,0) [0|50.2] "%/rpm" Vector__XXX
 SG_ EngPercentTorqueAtPoint5 : 112|8@1+ (1,-125) [-125|125] "%" Vector__XXX
 SG_ EngSpeedAtPoint5 : 96|16@1+ (0.125,0) [0|8031.875] "RPM" Vector__XXX
 SG_ EngPercentTorqueAtPoint4 : 88|8@1+ (1,-125) [-125|125] "%" Vector__XXX
 SG_ EngSpeedAtPoint4 : 72|16@1+ (0.125,0) [0|8031.875] "RPM" Vector__XXX
 SG_ EngPercentTorqueAtPoint3 : 64|8@1+ (1,-125) [-125|125] "%" Vector__XXX
 SG_ EngSpeedAtPoint3 : 48|16@1+ (0.125,0) [0|8031.875] "RPM" Vector__XXX
 SG_ EngPercentTorqueAtPoint2 : 40|8@1+ (1,-125) [-125|125] "%" Vector__XXX
 SG_ EngSpeedAtPoint2 : 24|16@1+ (0.125,0) [0|8031.875] "RPM" Vector__XXX
 SG_ EngPercentTorqueAtIdlePoint1 : 16|8@1+ (1,-125) [-125|125] "%" Vector__XXX
 SG_ EngSpeedAtIdlePoint1 : 0|16@1+ (0.125,0) [0|8031.875] "RPM" Vector__XXX

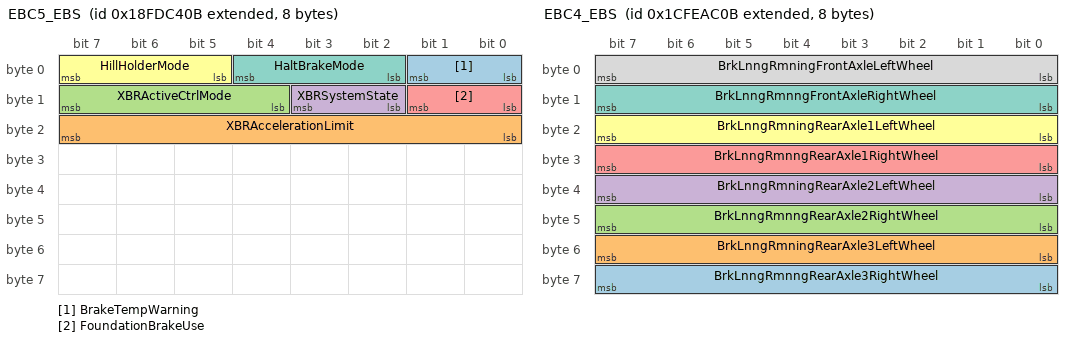
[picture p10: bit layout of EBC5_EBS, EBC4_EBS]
BO_ 2566767627 EBC5_EBS: 8 EBS
 SG_ BrakeTempWarning : 0|2@1+ (1,0) [0|3] "" Vector__XXX
 SG_ XBRAccelerationLimit : 16|8@1+ (0.1,-12.5) [-12.5|12.5] "m/s²" Vector__XXX
 SG_ XBRActiveCtrlMode : 12|4@1+ (1,0) [0|15] "" Vector__XXX
 SG_ XBRSystemState : 10|2@1+ (1,0) [0|3] "" Vector__XXX
 SG_ FoundationBrakeUse : 8|2@1+ (1,0) [0|3] "" Vector__XXX
 SG_ HillHolderMode : 5|3@1+ (1,0) [0|7] "" Vector__XXX
 SG_ HaltBrakeMode : 2|3@1+ (1,0) [0|7] "" Vector__XXX

BO_ 2633935883 EBC4_EBS: 8 EBS
 SG_ BrkLnngRmnngRearAxle3RightWheel : 56|8@1+ (0.4,0) [0|100] "%" Vector__XXX
 SG_ BrkLnngRmningRearAxle3LeftWheel : 48|8@1+ (0.4,0) [0|100] "%" Vector__XXX
 SG_ BrkLnngRmnngRearAxle2RightWheel : 40|8@1+ (0.4,0) [0|100] "%" Vector__XXX
 SG_ BrkLnngRmningRearAxle2LeftWheel : 32|8@1+ (0.4,0) [0|100] "%" Vector__XXX
 SG_ BrkLnngRmnngRearAxle1RightWheel : 24|8@1+ (0.4,0) [0|100] "%" Vector__XXX
 SG_ BrkLnngRmningRearAxle1LeftWheel : 16|8@1+ (0.4,0) [0|100] "%" Vector__XXX
 SG_ BrkLnngRmnngFrontAxleRightWheel : 8|8@1+ (0.4,0) [0|100] "%" Vector__XXX
 SG_ BrkLnngRmningFrontAxleLeftWheel : 0|8@1+ (0.4,0) [0|100] "%" Vector__XXX

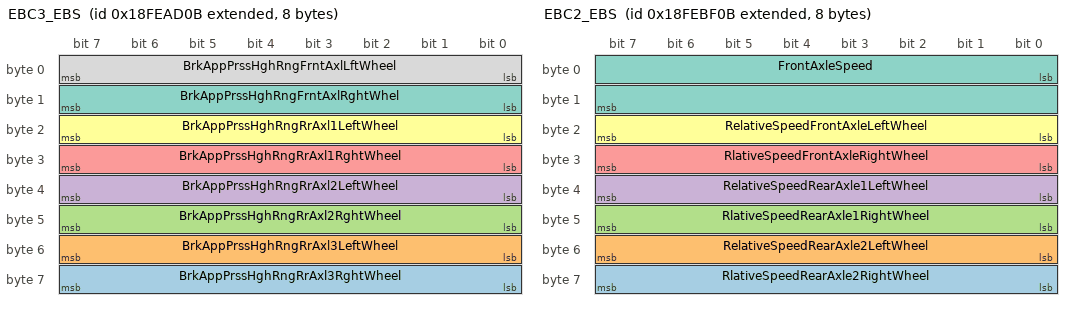
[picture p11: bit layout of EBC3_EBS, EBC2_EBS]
BO_ 2566827275 EBC3_EBS: 8 EBS
 SG_ BrkAppPrssHghRngRrAxl3RghtWheel : 56|8@1+ (5,0) [0|1250] "kPa" Vector__XXX
 SG_ BrkAppPrssHghRngRrAxl3LeftWheel : 48|8@1+ (5,0) [0|1250] "kPa" Vector__XXX
 SG_ BrkAppPrssHghRngRrAxl2RghtWheel : 40|8@1+ (5,0) [0|1250] "kPa" Vector__XXX
 SG_ BrkAppPrssHghRngRrAxl2LeftWheel : 32|8@1+ (5,0) [0|1250] "kPa" Vector__XXX
 SG_ BrkAppPrssHghRngRrAxl1RghtWheel : 24|8@1+ (5,0) [0|1250] "kPa" Vector__XXX
 SG_ BrkAppPrssHghRngRrAxl1LeftWheel : 16|8@1+ (5,0) [0|1250] "kPa" Vector__XXX
 SG_ BrkAppPrssHghRngFrntAxlRghtWhel : 8|8@1+ (5,0) [0|1250] "kPa" Vector__XXX
 SG_ BrkAppPrssHghRngFrntAxlLftWheel : 0|8@1+ (5,0) [0|1250] "kPa" Vector__XXX

BO_ 2566831883 EBC2_EBS: 8 EBS
 SG_ RlativeSpeedRearAxle2RightWheel : 56|8@1+ (0.0625,-7.8125) [-7.8125|7.8125] "km/h" Vector__XXX
 SG_ RelativeSpeedRearAxle2LeftWheel : 48|8@1+ (0.0625,-7.8125) [-7.8125|7.8125] "km/h" Vector__XXX
 SG_ RlativeSpeedRearAxle1RightWheel : 40|8@1+ (0.0625,-7.8125) [-7.8125|7.8125] "km/h" Vector__XXX
 SG_ RelativeSpeedRearAxle1LeftWheel : 32|8@1+ (0.0625,-7.8125) [-7.8125|7.8125] "km/h" Vector__XXX
 SG_ RlativeSpeedFrontAxleRightWheel : 24|8@1+ (0.0625,-7.8125) [-7.8125|7.8125] "km/h" Vector__XXX
 SG_ RelativeSpeedFrontAxleLeftWheel : 16|8@1+ (0.0625,-7.8125) [-7.8125|7.8125] "km/h" Vector__XXX
 SG_ FrontAxleSpeed : 0|16@1+ (0.00390625,0) [0|250.996] "km/h"  EMS

BO_ 2565865739 EBC1_EBS: 8 EBS
 SG_ SrcAddrssOfCtrllngDvcFrBrkCntrl : 48|8@1+ (1,0) [0|255] "" Vector__XXX
 SG_ BrakePedalPos : 8|8@1+ (0.4,0) [0|100] "%" Vector__XXX
 SG_ TrctrMntdTrilerABSWarningSignal : 62|2@1+ (1,0) [0|3] "" Vector__XXX
 SG_ TrailerABSStatus : 60|2@1+ (1,0) [0|3] "" Vector__XXX
 SG_ HaltBrakeSwitch : 58|2@1+ (1,0) [0|3] "" Vector__XXX
 SG_ ATC_ASRInformationSignal : 46|2@1+ (1,0) [0|3] "" Vector__XXX
 SG_ ABS_EBSAmberWarningSignal : 44|2@1+ (1,0) [0|3] "" Vector__XXX
 SG_ EBSRedWarningSignal : 42|2@1+ (1,0) [0|3] "" Vector__XXX
 SG_ ABSFullyOperational : 40|2@1+ (1,0) [0|3] "" Vector__XXX
 SG_ EngRetarderSelection : 32|8@1+ (0.4,0) [0|100] "%" Vector__XXX
 SG_ RemoteAccelEnableSwitch : 30|2@1+ (1,0) [0|3] "" Vector__XXX
 SG_ EngAuxEngShutdownSwitch : 28|2@1+ (1,0) [0|3] "" Vector__XXX
 SG_ EngDerateSwitch : 26|2@1+ (1,0) [0|3] "" Vector__XXX
 SG_ AccelInterlockSwitch : 24|2@1+ (1,0) [0|3] "" Vector__XXX
 SG_ TractionCtrlOverrideSwitch : 22|2@1+ (1,0) [0|3] "" Vector__XXX
 SG_ ASRHillHolderSwitch : 20|2@1+ (1,0) [0|3] "" Vector__XXX
 SG_ ASROffroadSwitch : 18|2@1+ (1,0) [0|3] "" Vector__XXX
 SG_ ABSOffroadSwitch : 16|2@1+ (1,0) [0|3] "" Vector__XXX
 SG_ EBSBrakeSwitch : 6|2@1+ (1,0) [0|3] "" Vector__XXX
 SG_ AntiLockBrakingActive : 4|2@1+ (1,0) [0|3] "" Vector__XXX
 SG_ ASRBrakeCtrlActive : 2|2@1+ (1,0) [0|3] "" Vector__XXX
 SG_ ASREngCtrlActive : 0|2@1+ (1,0) [0|3] "" Vector__XXX

BO_ 2566844672 CCVS_EMS: 8 EMS
 SG_ ParkBrakeReleaseInhibitRq : 6|2@1+ (1,0) [0|3] "" Vector__XXX
 SG_ EngShutdownOverrideSwitch : 62|2@1+ (1,0) [0|3] "" Vector__XXX
 SG_ EngTestModeSwitch : 60|2@1+ (1,0) [0|3] "" Vector__XXX
 SG_ EngIdleDecrementSwitch : 58|2@1+ (1,0) [0|3] "" Vector__XXX
 SG_ EngIdleIncrementSwitch : 56|2@1+ (1,0) [0|3] "" Vector__XXX
 SG_ CruiseCtrlStates : 53|3@1+ (1,0) [0|7] "" Vector__XXX
 SG_ PTOState : 48|5@1+ (1,0) [0|31] "" Vector__XXX
 SG_ CruiseCtrlSetSpeed : 40|8@1+ (1,0) [0|250] "km/h" Vector__XXX
 SG_ CruiseCtrlAccelerateSwitch : 38|2@1+ (1,0) [0|3] "" Vector__XXX
 SG_ CruiseCtrlResumeSwitch : 36|2@1+ (1,0) [0|3] "" Vector__XXX
 SG_ CruiseCtrlCoastSwitch : 34|2@1+ (1,0) [0|3] "" Vector__XXX
 SG_ CruiseCtrlSetSwitch : 32|2@1+ (1,0) [0|3] "" Vector__XXX
 SG_ ClutchSwitch : 30|2@1+ (1,0) [0|3] "" Vector__XXX
 SG_ BrakeSwitch : 28|2@1+ (1,0) [0|3] ""  EBS
 SG_ CruiseCtrlEnableSwitch : 26|2@1+ (1,0) [0|3] "" Vector__XXX
 SG_ CruiseCtrlActive : 24|2@1+ (1,0) [0|3] "" Vector__XXX
 SG_ WheelBasedVehicleSpeed : 8|16@1+ (0.00390625,0) [0|250.996] "km/h" Vector__XXX
 SG_ CruiseCtrlPauseSwitch : 4|2@1+ (1,0) [0|3] "" Vector__XXX
 SG_ ParkingBrakeSwitch : 2|2@1+ (1,0) [0|3] ""  EBS
 SG_ TwoSpeedAxleSwitch : 0|2@1+ (1,0) [0|3] "" Vector__XXX

BO_ 2565799678 ACL: 8 EBS
 SG_ ArbitraryAddressCapable : 63|1@1+ (1,0) [0|1] "" Vector__XXX
 SG_ IndustryGroup M : 60|3@1+ (1,0) [0|7] "" Vector__XXX
 SG_ VehicleSystemInstance : 56|4@1+ (1,0) [0|15] "" Vector__XXX
 SG_ Function : 40|8@1+ (1,0) [0|255] "" Vector__XXX
 SG_ FunctionInstance : 35|5@1+ (1,0) [0|31] "" Vector__XXX
 SG_ ECUInstance : 32|3@1+ (1,0) [0|7] "" Vector__XXX
 SG_ ManufacturerCode : 21|11@1+ (1,0) [0|2047] "" Vector__XXX
 SG_ IdentityNumber : 0|21@1+ (1,0) [0|2097152] "" Vector__XXX
 SG_ VehicleSystem m0 : 49|7@1+ (1,0) [0|127] "" Vector__XXX
 SG_ VehicleSystem5 m5 : 49|7@1+ (1,0) [0|127] "" Vector__XXX
 SG_ VehicleSystem4 m4 : 49|7@1+ (1,0) [0|127] "" Vector__XXX
 SG_ VehicleSystem3 m3 : 49|7@1+ (1,0) [0|127] "" Vector__XXX
 SG_ VehicleSystem2 m2 : 49|7@1+ (1,0) [0|127] "" Vector__XXX
 SG_ VehicleSystem1 m1 : 49|7@1+ (1,0) [0|127] "" Vector__XXX

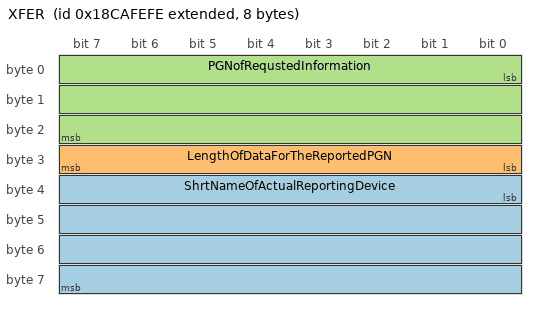
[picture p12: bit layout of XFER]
BO_ 2563440382 XFER: 8 EMS
 SG_ ShrtNameOfActualReportingDevice : 32|32@1+ (1,0) [0|0] "(2^32 - 1)" Vector__XXX
 SG_ LengthOfDataForTheReportedPGN : 24|8@1+ (1,0) [0|255] "" Vector__XXX
 SG_ PGNofRequstedInformation : 0|24@1+ (1,0) [0|16777215] "" Vector__XXX

BO_ 2565603070 TPDT: 8 Vector__XXX
 SG_ SequenceNumber : 0|8@1+ (1,0) [0|252] "" Vector__XXX

BO_ 2565668606 TPCM: 8 Vector__XXX
 SG_ TotalNumberOfPacketsEoMA m19 : 24|8@1+ (1,0) [0|255] "" Vector__XXX
 SG_ TotalMessageSizeEoMA m19 : 8|16@1+ (1,0) [0|64255] "counts" Vector__XXX
 SG_ TotalMessageSizeBAM m32 : 8|16@1+ (1,0) [0|64255] "counts" Vector__XXX
 SG_ TotalNumberOfPacketsBAM m32 : 24|8@1+ (1,0) [0|255] "" Vector__XXX
 SG_ ConnectionAbortReason m255 : 8|8@1+ (1,0) [0|255] "" Vector__XXX
 SG_ NextPacketNumberToBeSent m17 : 16|8@1+ (1,0) [0|255] "" Vector__XXX
 SG_ NumberOfPacketsThatCanBeSent m17 : 8|8@1+ (1,0) [0|255] "" Vector__XXX
 SG_ PGNumber : 40|24@1+ (1,0) [0|16777200] "" Vector__XXX
 SG_ MaximumNumberOfPackets m16 : 32|8@1+ (1,0) [0|255] "" Vector__XXX
 SG_ TotalNumberOfPackets m16 : 24|8@1+ (1,0) [0|255] "" Vector__XXX
 SG_ TotalMessageSize m16 : 8|16@1+ (1,0) [0|64255] "counts" Vector__XXX
 SG_ ControlByte M : 0|8@1+ (1,0) [0|255] "" Vector__XXX

BO_ 2563374846 RQST2: 8 Vector__XXX
 SG_ UseTransferMode : 24|2@1+ (1,0) [0|3] "" Vector__XXX
 SG_ ParameterGroupNumber : 0|24@1+ (1,0) [0|16777215] "" Vector__XXX

BO_ 2565537534 RQST: 3 Vector__XXX
 SG_ ParameterGroupNumber : 0|24@1+ (1,0) [0|16777215] ""  EMS,EBS

BO_ 2565406462 ACKM: 8 EBS
 SG_ AddressBusy m3 : 32|8@1+ (1,0) [0|255] "" Vector__XXX
 SG_ ControlByte M : 0|8@1+ (1,0) [0|255] "" Vector__XXX
 SG_ ParameterGroupNumber : 40|24@1+ (1,0) [0|16777215] "" Vector__XXX
 SG_ GroupFunctionValue : 8|8@1+ (1,0) [0|255] "" Vector__XXX
 SG_ AddressAccessDenied m2 : 32|8@1+ (1,0) [0|255] "" Vector__XXX
 SG_ AddressNegativeAcknowledgement m1 : 32|8@1+ (1,0) [0|255] "" Vector__XXX
 SG_ AddressAcknowledged m0 : 32|8@1+ (1,0) [0|255] "" Vector__XXX

BO_TX_BU_ 2566839038 : EMS,EBS;
BO_TX_BU_ 2566768126 : EMS,EBS;
BO_TX_BU_ 2565799678 : EMS,EBS;
BO_TX_BU_ 2565406462 : EMS,EBS;
CM_ BO_ 2566836222 "Pending DTCs
The purpose of this DM is to enable the external test equipment to obtain “pending” diagnostic trouble codes 
detected during current or last completed driving cycle for emission-related components/systems.";
CM_ SG_ 2566836222 SPN_High4 "3 most significant bits of SPN (most significant at bit 8) ";
CM_ SG_ 2566836222 SPN_High3 "3 most significant bits of SPN (most significant at bit 8) ";
CM_ SG_ 2566836222 SPN_High5 "3 most significant bits of SPN (most significant at bit 8) ";
CM_ SG_ 2566836222 SPN_High2 "3 most significant bits of SPN (most significant at bit 8) ";
CM_ SG_ 2566836222 SPN_High1 "3 most significant bits of SPN (most significant at bit 8) ";
CM_ SG_ 2566836222 SpnConversionMethod1 "If set to '0', the document is converted according to version 4 of the J1939-73 document (February 1996); otherwise, it is converted according to one of the three earlier versions.";
CM_ SG_ 2566836222 SpnConversionMethod5 "If set to '0', the document is converted according to version 4 of the J1939-73 document (February 1996); otherwise, it is converted according to one of the three earlier versions.";
CM_ SG_ 2566836222 SpnConversionMethod4 "If set to '0', the document is converted according to version 4 of the J1939-73 document (February 1996); otherwise, it is converted according to one of the three earlier versions.";
CM_ SG_ 2566836222 SpnConversionMethod3 "If set to '0', the document is converted according to version 4 of the J1939-73 document (February 1996); otherwise, it is converted according to one of the three earlier versions.";
CM_ SG_ 2566836222 SpnConversionMethod2 "If set to '0', the document is converted according to version 4 of the J1939-73 document (February 1996); otherwise, it is converted according to one of the three earlier versions.";
CM_ SG_ 2566836222 OccurenceCount5 "Contains the number of times a fault has been independently detected.";
CM_ SG_ 2566836222 OccurenceCount4 "Contains the number of times a fault has been independently detected.";
CM_ SG_ 2566836222 OccurenceCount3 "Contains the number of times a fault has been independently detected.";
CM_ SG_ 2566836222 OccurenceCount2 "Contains the number of times a fault has been independently detected.";
CM_ SG_ 2566836222 OccurenceCount1 "Contains the number of times a fault has been independently detected.";
CM_ SG_ 2566836222 FMI5 "The FMI defines the type of failure detected in the subsystem identified by an SPN.";
CM_ SG_ 2566836222 FMI4 "The FMI defines the type of failure detected in the subsystem identified by an SPN.";
CM_ SG_ 2566836222 FMI3 "The FMI defines the type of failure detected in the subsystem identified by an SPN.";
CM_ SG_ 2566836222 FMI2 "The FMI defines the type of failure detected in the subsystem identified by an SPN.";
CM_ SG_ 2566836222 FMI1 "The FMI defines the type of failure detected in the subsystem identified by an SPN.";
CM_ SG_ 2566836222 FlashRedStopLamp "This parameter provides the capability to flash the RSL


00 - Slow Flash (1 Hz, 50 % duty cycle)
01 - Fast Flash (2 Hz or faster, 50% duty cycle)
10 - Reserved
11 - Unavailable / Do Not Flash";
CM_ SG_ 2566836222 FlashProtectLamp "This parameter provides the capability to flash the engine protect lamp


00 - Slow Flash (1 Hz, 50 % duty cycle)
01 - Fast Flash (2 Hz or faster, 50% duty cycle)
10 - Reserved
11 - Unavailable / Do Not Flash";
CM_ SG_ 2566836222 FlashMalfuncIndicatorLamp "This parameter provides the capability to flash the MIL
00 - Slow Flash (1 Hz, 50 % duty cycle)
01 - Fast Flash (2 Hz or faster, 50% duty cycle)
10 - Class C DTC
11 - Unavailable / Do Not Flash
Note:  State 10 is for WWH OBD discriminatory ...";
CM_ SG_ 2566836222 FlashAmberWarningLamp "This parameter provides the capability to flash the AWL

00 - Slow Flash (1 Hz, 50 % duty cycle)
01 - Fast Flash (2 Hz or faster, 50% duty cycle)
10 - Reserved
11 - Unavailable / Do Not Flash";
CM_ SG_ 2566836222 MalfunctionIndLampStatus "A lamp used to relay only emissions-related trouble code information. This lamp is only illuminated when there is an emission-related trouble code active.
00     Lamp Off
01     Lamp On
10     Short MIL for WWH OBD
11     Not available
Note ...";
CM_ SG_ 2566836222 AmberWarningLampStatus "This lamp is used to relay trouble code information that is reporting a problem with the vehicle system but the vehicle need not be immediately stopped. 

00     Lamp Off
01     Lamp On
10     Reserved
11     Not available";
CM_ SG_ 2566836222 RedStopLampState "This lamp is used to relay trouble code information that is of a severe enough condition that it warrants stopping the vehicle.

00     Lamp Off
01     Lamp On
10     Reserved
11     Not available";
CM_ SG_ 2566836222 ProtectLampStatus "This lamp is used to relay trouble code information that is reporting a problem with a vehicle system that is most probably not electronic subsystem related. For instance, engine coolant temperature is exceeding its prescribed temperature range.
00 ...";
CM_ SG_ 2566836222 SPN5 "16 least significant bits of SPN";
CM_ SG_ 2566836222 SPN4 "16 least significant bits of SPN";
CM_ SG_ 2566836222 SPN3 "16 least significant bits of SPN";
CM_ SG_ 2566836222 SPN2 "16 least significant bits of SPN";
CM_ SG_ 2566836222 SPN1 "16 least significant bits of SPN";
CM_ BO_ 2566835966 "Diagnostic Readiness 1
Reports the diagnostics information that relates to diagnostic readiness.";
CM_ SG_ 2566835966 OBDCompliance "Identifies the OBD compliance capability of the responding controller. Identifies the requirements level to which the controller was built.";
CM_ SG_ 2566835966 PreviouslyActiveTroubleCodes "Identifies the number of previously active trouble codes that are present in a specific controller. If no DTCs have been previously active, this field should be set to zero.";
CM_ SG_ 2566835966 ActiveTroubleCodes "Identifies the number of active trouble codes that are present in a specific controller. If no DTCs are active, this field should be set to zero.";
CM_ BO_ 2566835710 "Freeze Frame Parameters
A freeze frame is defined as the list of recorded parameters at the time a diagnostic trouble code was captured";
CM_ SG_ 2566835710 SpnConversionMethod "If set to '0', the document is converted according to version 4 of the J1939-73 document (February 1996); otherwise, it is converted according to one of the three earlier versions.";
CM_ SG_ 2566835710 OccurenceCount "Contains the number of times a fault has been independently detected.";
CM_ SG_ 2566835710 SPN_High "3 most significant bits of SPN (most significant at bit 8) ";
CM_ SG_ 2566835710 FMI "Failure Mode Identifier (FMI) 
The FMI defines the type of failure detected in the sub-system identified by an SPN.";
CM_ SG_ 2566835710 EngineIntakeManifold1Pressure "Engine Intake Manifold #1 Pressure.
The gage pressure measurement of the air intake manifold. If there are multiple air pressure sensors in the intake stream, this is the last one in flow direction before entering the combustion chamber.  This ...";
CM_ SG_ 2566835710 FreezeFrameLength "The Freeze Frame Length shall be equal to the number of bytes in the required parameters plus the number of bytes in the manufacturer specific parameters.";
CM_ SG_ 2566835710 Speed "Engine Speed.
Actual engine speed which is calculated over a minimum crankshaft angle of 720 degrees divided by the number of cylinders.";
CM_ SG_ 2566835710 TorqueMode "Engine Torque Mode.
State signal which indicates which engine torque mode is currently generating, limiting, or controlling the torque.  Note that the modes are not in prioritized order. Not all modes may be relevant for a given device.  Some ...";
CM_ SG_ 2566835710 WheelBasedVS "Wheel-Based Vehicle Speed.
Speed of the vehicle as calculated from wheel or tailshaft speed.";
CM_ SG_ 2566835710 PercentLoadAtCurrentSpeed "Engine Percent Load At Current Speed.
The ratio of actual engine percent torque (indicated) to maximum indicated torque available at the current engine speed, clipped to zero torque during engine braking.";
CM_ SG_ 2566835710 CoolantTemperature "Engine Coolant Temperature.
Temperature of liquid found in engine cooling system.";
CM_ SG_ 2566835710 SPN "16 least significant bits of SPN";
CM_ BO_ 2566835454 "Diagnostics Data Clear/Reset for Previously Active DTCs";
CM_ BO_ 2566835198 "Previously Active Diagnostic Trouble Codes
The information communicated is DM service to communicate the previously active trouble codes.";
CM_ SG_ 2566835198 SPN_High4 "3 most significant bits of SPN (most significant at bit 8) ";
CM_ SG_ 2566835198 SPN_High3 "3 most significant bits of SPN (most significant at bit 8) ";
CM_ SG_ 2566835198 SPN_High5 "3 most significant bits of SPN (most significant at bit 8) ";
CM_ SG_ 2566835198 SPN_High2 "3 most significant bits of SPN (most significant at bit 8) ";
CM_ SG_ 2566835198 SPN_High1 "3 most significant bits of SPN (most significant at bit 8) ";
CM_ SG_ 2566835198 SpnConversionMethod1 "If set to '0', the document is converted according to version 4 of the J1939-73 document (February 1996); otherwise, it is converted according to one of the three earlier versions.";
CM_ SG_ 2566835198 SpnConversionMethod5 "If set to '0', the document is converted according to version 4 of the J1939-73 document (February 1996); otherwise, it is converted according to one of the three earlier versions.";
CM_ SG_ 2566835198 SpnConversionMethod4 "If set to '0', the document is converted according to version 4 of the J1939-73 document (February 1996); otherwise, it is converted according to one of the three earlier versions.";
CM_ SG_ 2566835198 SpnConversionMethod3 "If set to '0', the document is converted according to version 4 of the J1939-73 document (February 1996); otherwise, it is converted according to one of the three earlier versions.";
CM_ SG_ 2566835198 SpnConversionMethod2 "If set to '0', the document is converted according to version 4 of the J1939-73 document (February 1996); otherwise, it is converted according to one of the three earlier versions.";
CM_ SG_ 2566835198 OccurenceCount5 "Contains the number of times a fault has been independently detected.";
CM_ SG_ 2566835198 OccurenceCount4 "Contains the number of times a fault has been independently detected.";
CM_ SG_ 2566835198 OccurenceCount3 "Contains the number of times a fault has been independently detected.";
CM_ SG_ 2566835198 OccurenceCount2 "Contains the number of times a fault has been independently detected.";
CM_ SG_ 2566835198 OccurenceCount1 "Contains the number of times a fault has been independently detected.";
CM_ SG_ 2566835198 FMI5 "The FMI defines the type of failure detected in the subsystem identified by an SPN.";
CM_ SG_ 2566835198 FMI4 "The FMI defines the type of failure detected in the subsystem identified by an SPN.";
CM_ SG_ 2566835198 FMI3 "The FMI defines the type of failure detected in the subsystem identified by an SPN.";
CM_ SG_ 2566835198 FMI2 "The FMI defines the type of failure detected in the subsystem identified by an SPN.";
CM_ SG_ 2566835198 FMI1 "The FMI defines the type of failure detected in the subsystem identified by an SPN.";
CM_ SG_ 2566835198 FlashRedStopLamp "This parameter provides the capability to flash the RSL


00 - Slow Flash (1 Hz, 50 % duty cycle)
01 - Fast Flash (2 Hz or faster, 50% duty cycle)
10 - Reserved
11 - Unavailable / Do Not Flash";
CM_ SG_ 2566835198 FlashProtectLamp "This parameter provides the capability to flash the engine protect lamp


00 - Slow Flash (1 Hz, 50 % duty cycle)
01 - Fast Flash (2 Hz or faster, 50% duty cycle)
10 - Reserved
11 - Unavailable / Do Not Flash";
CM_ SG_ 2566835198 FlashMalfuncIndicatorLamp "This parameter provides the capability to flash the MIL
00 - Slow Flash (1 Hz, 50 % duty cycle)
01 - Fast Flash (2 Hz or faster, 50% duty cycle)
10 - Class C DTC
11 - Unavailable / Do Not Flash
Note:  State 10 is for WWH OBD discriminatory ...";
CM_ SG_ 2566835198 FlashAmberWarningLamp "This parameter provides the capability to flash the AWL

00 - Slow Flash (1 Hz, 50 % duty cycle)
01 - Fast Flash (2 Hz or faster, 50% duty cycle)
10 - Reserved
11 - Unavailable / Do Not Flash";
CM_ SG_ 2566835198 MalfunctionIndLampStatus "A lamp used to relay only emissions-related trouble code information. This lamp is only illuminated when there is an emission-related trouble code active.
00     Lamp Off
01     Lamp On
10     Short MIL for WWH OBD
11     Not available
Note ...";
CM_ SG_ 2566835198 AmberWarningLampStatus "This lamp is used to relay trouble code information that is reporting a problem with the vehicle system but the vehicle need not be immediately stopped. 

00     Lamp Off
01     Lamp On
10     Reserved
11     Not available";
CM_ SG_ 2566835198 RedStopLampState "This lamp is used to relay trouble code information that is of a severe enough condition that it warrants stopping the vehicle.

00     Lamp Off
01     Lamp On
10     Reserved
11     Not available";
CM_ SG_ 2566835198 ProtectLampStatus "This lamp is used to relay trouble code information that is reporting a problem with a vehicle system that is most probably not electronic subsystem related. For instance, engine coolant temperature is exceeding its prescribed temperature range.
00 ...";
CM_ SG_ 2566835198 SPN5 "16 least significant bits of SPN";
CM_ SG_ 2566835198 SPN4 "16 least significant bits of SPN";
CM_ SG_ 2566835198 SPN3 "16 least significant bits of SPN";
CM_ SG_ 2566835198 SPN2 "16 least significant bits of SPN";
CM_ SG_ 2566835198 SPN1 "16 least significant bits of SPN";
CM_ BO_ 2566834942 "Active Diagnostic Trouble Codes
";
CM_ SG_ 2566834942 SPN_High4 "3 most significant bits of SPN (most significant at bit 8) ";
CM_ SG_ 2566834942 SPN_High3 "3 most significant bits of SPN (most significant at bit 8) ";
CM_ SG_ 2566834942 SPN_High5 "3 most significant bits of SPN (most significant at bit 8) ";
CM_ SG_ 2566834942 SPN_High2 "3 most significant bits of SPN (most significant at bit 8) ";
CM_ SG_ 2566834942 SPN_High1 "3 most significant bits of SPN (most significant at bit 8) ";
CM_ SG_ 2566834942 SpnConversionMethod1 "If set to '0', the document is converted according to version 4 of the J1939-73 document (February 1996); otherwise, it is converted according to one of the three earlier versions.";
CM_ SG_ 2566834942 SpnConversionMethod5 "If set to '0', the document is converted according to version 4 of the J1939-73 document (February 1996); otherwise, it is converted according to one of the three earlier versions.";
CM_ SG_ 2566834942 SpnConversionMethod4 "If set to '0', the document is converted according to version 4 of the J1939-73 document (February 1996); otherwise, it is converted according to one of the three earlier versions.";
CM_ SG_ 2566834942 SpnConversionMethod3 "If set to '0', the document is converted according to version 4 of the J1939-73 document (February 1996); otherwise, it is converted according to one of the three earlier versions.";
CM_ SG_ 2566834942 SpnConversionMethod2 "If set to '0', the document is converted according to version 4 of the J1939-73 document (February 1996); otherwise, it is converted according to one of the three earlier versions.";
CM_ SG_ 2566834942 OccurenceCount5 "Contains the number of times a fault has been independently detected.";
CM_ SG_ 2566834942 OccurenceCount4 "Contains the number of times a fault has been independently detected.";
CM_ SG_ 2566834942 OccurenceCount3 "Contains the number of times a fault has been independently detected.";
CM_ SG_ 2566834942 OccurenceCount2 "Contains the number of times a fault has been independently detected.";
CM_ SG_ 2566834942 OccurenceCount1 "Contains the number of times a fault has been independently detected.";
CM_ SG_ 2566834942 FMI5 "The FMI defines the type of failure detected in the subsystem identified by an SPN.";
CM_ SG_ 2566834942 FMI4 "The FMI defines the type of failure detected in the subsystem identified by an SPN.";
CM_ SG_ 2566834942 FMI3 "The FMI defines the type of failure detected in the subsystem identified by an SPN.";
CM_ SG_ 2566834942 FMI2 "The FMI defines the type of failure detected in the subsystem identified by an SPN.";
CM_ SG_ 2566834942 FMI1 "The FMI defines the type of failure detected in the subsystem identified by an SPN.";
CM_ SG_ 2566834942 FlashRedStopLamp "This parameter provides the capability to flash the RSL


00 - Slow Flash (1 Hz, 50 % duty cycle)
01 - Fast Flash (2 Hz or faster, 50% duty cycle)
10 - Reserved
11 - Unavailable / Do Not Flash";
CM_ SG_ 2566834942 FlashProtectLamp "This parameter provides the capability to flash the engine protect lamp


00 - Slow Flash (1 Hz, 50 % duty cycle)
01 - Fast Flash (2 Hz or faster, 50% duty cycle)
10 - Reserved
11 - Unavailable / Do Not Flash";
CM_ SG_ 2566834942 FlashMalfuncIndicatorLamp "This parameter provides the capability to flash the MIL
00 - Slow Flash (1 Hz, 50 % duty cycle)
01 - Fast Flash (2 Hz or faster, 50% duty cycle)
10 - Class C DTC
11 - Unavailable / Do Not Flash
Note:  State 10 is for WWH OBD discriminatory ...";
CM_ SG_ 2566834942 FlashAmberWarningLamp "This parameter provides the capability to flash the AWL

00 - Slow Flash (1 Hz, 50 % duty cycle)
01 - Fast Flash (2 Hz or faster, 50% duty cycle)
10 - Reserved
11 - Unavailable / Do Not Flash";
CM_ SG_ 2566834942 MalfunctionIndLampStatus "A lamp used to relay only emissions-related trouble code information. This lamp is only illuminated when there is an emission-related trouble code active.
00     Lamp Off
01     Lamp On
10     Short MIL for WWH OBD
11     Not available
Note ...";
CM_ SG_ 2566834942 AmberWarningLampStatus "This lamp is used to relay trouble code information that is reporting a problem with the vehicle system but the vehicle need not be immediately stopped. 

00     Lamp Off
01     Lamp On
10     Reserved
11     Not available";
CM_ SG_ 2566834942 RedStopLampState "This lamp is used to relay trouble code information that is of a severe enough condition that it warrants stopping the vehicle.

00     Lamp Off
01     Lamp On
10     Reserved
11     Not available";
CM_ SG_ 2566834942 ProtectLampStatus "This lamp is used to relay trouble code information that is reporting a problem with a vehicle system that is most probably not electronic subsystem related. For instance, engine coolant temperature is exceeding its prescribed temperature range.
00 ...";
CM_ SG_ 2566834942 SPN5 "16 least significant bits of SPN";
CM_ SG_ 2566834942 SPN4 "16 least significant bits of SPN";
CM_ SG_ 2566834942 SPN3 "16 least significant bits of SPN";
CM_ SG_ 2566834942 SPN2 "16 least significant bits of SPN";
CM_ SG_ 2566834942 SPN1 "16 least significant bits of SPN";
CM_ BO_ 2348820747 "Torque/Speed Control 1";
CM_ SG_ 2348820747 MessageCounter "The message counter is used to detect situations where the transmitting ECU malfunction repeats the same frame all the time.";
CM_ SG_ 2348820747 MessageChecksum "The checksum is used to verify the signal path from the transmitting device to the receiving device.";
CM_ SG_ 2348820747 ControlPurpose "State signal which indicates which control mode the sending device is using to generate the TSC1 command.";
CM_ SG_ 2348820747 TransmissionRate "This parameter indicates the transmission rate at which the sending device will transmit the TSC1 message.";
CM_ SG_ 2348820747 EngRqedTorque_TorqueLimit "Parameter provided to the engine or retarder in the torque/speed control message for controlling or limiting the output torque.";
CM_ SG_ 2348820747 EngRqedSpeed_SpeedLimit "Parameter provided to the engine from external sources in the torque/speed control message.";
CM_ SG_ 2348820747 EngRqedSpeedCtrlConditions "This mode tells the engine control system the governor characteristics that are desired during speed control.";
CM_ SG_ 2348820747 EngineRequestedTorqueHiRes "This parameter displays an additional torque in percent of the reference engine torque.";
CM_ BO_ 2348875275 "Torque/Speed Control 1";
CM_ SG_ 2348875275 MessageCounter "The message counter is used to detect situations where the transmitting ECU malfunction repeats the same frame all the time.";
CM_ SG_ 2348875275 MessageChecksum "The checksum is used to verify the signal path from the transmitting device to the receiving device.";
CM_ SG_ 2348875275 ControlPurpose "State signal which indicates which control mode the sending device is using to generate the TSC1 command.";
CM_ SG_ 2348875275 TransmissionRate "This parameter indicates the transmission rate at which the sending device will transmit the TSC1 message.";
CM_ SG_ 2348875275 EngRqedTorque_TorqueLimit "Parameter provided to the engine or retarder in the torque/speed control message for controlling or limiting the output torque.";
CM_ SG_ 2348875275 EngRqedSpeed_SpeedLimit "Parameter provided to the engine from external sources in the torque/speed control message.";
CM_ SG_ 2348875275 EngRqedSpeedCtrlConditions "This mode tells the engine control system the governor characteristics that are desired during speed control.";
CM_ SG_ 2348875275 EngineRequestedTorqueHiRes "This parameter displays an additional torque in percent of the reference engine torque.";
CM_ BO_ 2348810251 "Torque/Speed Control 1";
CM_ SG_ 2348810251 MessageCounter "The message counter is used to detect situations where the transmitting ECU malfunction repeats the same frame all the time.";
CM_ SG_ 2348810251 MessageChecksum "The checksum is used to verify the signal path from the transmitting device to the receiving device.";
CM_ SG_ 2348810251 ControlPurpose "State signal which indicates which control mode the sending device is using to generate the TSC1 command.";
CM_ SG_ 2348810251 TransmissionRate "This parameter indicates the transmission rate at which the sending device will transmit the TSC1 message.";
CM_ SG_ 2348810251 EngRqedTorque_TorqueLimit "Parameter provided to the engine or retarder in the torque/speed control message for controlling or limiting the output torque.";
CM_ SG_ 2348810251 EngRqedSpeed_SpeedLimit "Parameter provided to the engine from external sources in the torque/speed control message.";
CM_ SG_ 2348810251 EngRqedSpeedCtrlConditions "This mode tells the engine control system the governor characteristics that are desired during speed control.";
CM_ SG_ 2348810251 EngineRequestedTorqueHiRes "This parameter displays an additional torque in percent of the reference engine torque.";
CM_ BO_ 2633935104 "Exhaust Oxygen 1";
CM_ SG_ 2633935104 EngExhstGsOxygnSnsrClsdLpOprton "Indicates whether the engine is using the Exhaust Gas Oxygen sensor to control the air/fuel ratio.";
CM_ BO_ 2566845952 "Inlet/Exhaust Conditions 1";
CM_ SG_ 2566845952 EngExhaustGasTemp "Temperature of combustion byproducts leaving the engine.";
CM_ SG_ 2566845952 EngAirInletPress "Absolute air pressure at inlet to intake manifold or air box.";
CM_ SG_ 2566845952 EngIntakeManifold1Temp "Temperature of pre-combustion air found in intake manifold of engine air supply system.";
CM_ SG_ 2566845952 EngTurboBoostPress "Gage pressure of air measured downstream on the compressor discharge side of the turbocharger.";
CM_ SG_ 2566845952 EngParticulateTrapInletPress "Exhaust back pressure as a result of particle accumulation on filter media placed in the exhaust stream.";
CM_ BO_ 2566841600 "Engine Hours, Revolutions";
CM_ SG_ 2566841600 EngTotalRevolutions "Accumulated number of revolutions of engine crankshaft during its operation.";
CM_ SG_ 2566841600 EngTotalHoursOfOperation "Accumulated time of operation of engine.";
CM_ BO_ 2566843392 "Vehicle Identification";
CM_ SG_ 2566843392 VehicleIdentificationNumber "Vehicle Identification Number";
CM_ BO_ 2566832384 "High Resolution Vehicle Distance";
CM_ SG_ 2566832384 HighResolutionTripDistance "Distance traveled during all or part of a journey.";
CM_ SG_ 2566832384 HghRslutionTotalVehicleDistance "Accumulated distance traveled by the vehicle during its operation.";
CM_ BO_ 2565867787 "Vehicle Dynamic Stability Control 2";
CM_ SG_ 2565867787 LongitudinalAcceleration "Indicates the longitudinal acceleration of the vehicle.";
CM_ SG_ 2565867787 LateralAcceleration "Indicates a lateral acceleration of the vehicle.";
CM_ SG_ 2565867787 YawRate "Indicates the rotation about the vertical axis.";
CM_ SG_ 2565867787 SteerWheelTurnCounter "Indicates number of steering wheel turns, absolute position or relative position at ignition on.";
CM_ SG_ 2565867787 SteerWheelAngle "The main operator`s steering wheel angle (on the steering column, not the actual wheel angle).";
CM_ BO_ 2566803211 "Vehicle Dynamic Stability Control 1";
CM_ SG_ 2566803211 YCBrakeCtrlActive "State signal which indicates that Yaw Control (YC) has activated brake control.";
CM_ SG_ 2566803211 YCEngCtrlActive "State Signal which indicates that the Yaw Control (YC) has commanded engine control to be active.";
CM_ SG_ 2566803211 ROPBrakeCtrlActive "State signal which indicates that Roll over Prevention (ROP) has activated brake control.";
CM_ SG_ 2566803211 ROPEngCtrlActive "State Signal which indicates that the Roll Over Prevention (ROP) has commanded engine control to be active.";
CM_ SG_ 2566803211 VDCFullyOperational "Signal that indicates whether VDC is fully operational or whether its functionality is reduced by a permanent or temporary (e.";
CM_ SG_ 2566803211 VDCInformationSignal "This parameter commands the VDC information signal, for example a dash lamp.";
CM_ BO_ 2566840320 "Vehicle Distance";
CM_ SG_ 2566840320 TotalVehicleDistance "Accumulated distance traveled by vehicle during its operation.";
CM_ SG_ 2566840320 TripDistance "Distance traveled during all or part of a journey.";
CM_ BO_ 2348875518 "Torque/Speed Control 1";
CM_ SG_ 2348875518 MessageCounter "The message counter is used to detect situations where the transmitting ECU malfunction repeats the same frame all the time.";
CM_ SG_ 2348875518 MessageChecksum "The checksum is used to verify the signal path from the transmitting device to the receiving device.";
CM_ SG_ 2348875518 ControlPurpose "State signal which indicates which control mode the sending device is using to generate the TSC1 command.";
CM_ SG_ 2348875518 TransmissionRate "This parameter indicates the transmission rate at which the sending device will transmit the TSC1 message.";
CM_ SG_ 2348875518 EngRqedTorque_TorqueLimit "Parameter provided to the engine or retarder in the torque/speed control message for controlling or limiting the output torque.";
CM_ SG_ 2348875518 EngRqedSpeed_SpeedLimit "Parameter provided to the engine from external sources in the torque/speed control message.";
CM_ SG_ 2348875518 EngRqedSpeedCtrlConditions "This mode tells the engine control system the governor characteristics that are desired during speed control.";
CM_ SG_ 2348875518 EngineRequestedTorqueHiRes "This parameter displays an additional torque in percent of the reference engine torque.";
CM_ BO_ 2566839552 "Turbocharger";
CM_ SG_ 2566839552 EngTurbo1Speed "Rotational velocity of rotor in the turbocharger.";
CM_ SG_ 2566839552 EngTurboLubeOilPress1 "Gage pressure of oil in turbocharger lubrication system.";
CM_ BO_ 2566839038 "Software Identification";
CM_ SG_ 2566839038 NmbrOfSftwrIdentificationFields "Number of software identification designators represented in the software identification parameter group.";
CM_ SG_ 2566839038 SoftwareID3 "Software ID";
CM_ SG_ 2566839038 SoftwareID2 "Software ID";
CM_ SG_ 2566839038 SoftwareID1 "Software ID";
CM_ BO_ 2566841344 "Shutdown";
CM_ SG_ 2566841344 EngOverspeedTest "The engine overspeed test signal as measured by the reporting ECM.";
CM_ SG_ 2566841344 EngAirShutoffCmdStatus "State signal which indicates when the Air Shutoff driver output is being driven.";
CM_ SG_ 2566841344 EngAlarmOutputCmdStatus "State signal which indicates when the Alarm driver output is being driven.";
CM_ SG_ 2566841344 EngAlarmAcknowledge "The Engine Alarm Acknowledge Input signal as measured by the reporting ECM.";
CM_ SG_ 2566841344 EngProtectionSystemConfig "Parameter which indicates the configuration of the engine shutdown system.";
CM_ SG_ 2566841344 EngProtectionSystemTimerState "Status signal which indicates the current mode of the engine protection system timer system.";
CM_ SG_ 2566841344 EngPrtectionSystemTimerOverride "Status signal which indicates the status of the override feature of the engine protection system timer.";
CM_ SG_ 2566841344 EngPrtctnSystmApprchingShutdown "Status signal which indicates that engine shutdown is imminent.";
CM_ SG_ 2566841344 EngPrtctionSystemHasShutdownEng "Status signal which indicates whether or not the engine protection system has shutdown the engine.";
CM_ SG_ 2566841344 RefrigerantHighPressSwitch "Switch signal which indicates the position of the high pressure switch in the coolant circuit of an air conditioning system.";
CM_ SG_ 2566841344 RefrigerantLowPressSwitch "Switch signal which indicates the position of the low pressure switch in the coolant circuit of an air conditioning system.";
CM_ SG_ 2566841344 EngIdleShutdownTimerFunction "Parameter which indicates the configuration of the idle shutdown timer system.";
CM_ SG_ 2566841344 EngIdleShutdownTimerState "Status signal which indicates the current mode of operation of the idle shutdown timer system.";
CM_ SG_ 2566841344 EngIdleShutdownTimerOverride "Status signal which indicates the status of the override feature of the idle shutdown timer system.";
CM_ SG_ 2566841344 EngIdleShutdownDriverAlertMode "Status signal which indicates the status of the driver alert mode of the idle shutdown timer system.";
CM_ SG_ 2566841344 EngIdleShutdownHasShutdownEng "Status signal which identifies whether or not the engine has been shutdown by the idle shutdown timer system.";
CM_ BO_ 2566844416 "Power Takeoff Information";
CM_ SG_ 2566844416 OperatorPTOMemorySelectSwitch "Measured state of the operator PTO memory select switch.";
CM_ SG_ 2566844416 EngPTOAccelerateSwitch "Switch signal of the PTO control activator which indicates that the activator is in the position accelerate.";
CM_ SG_ 2566844416 EngPTOResumeSwitch "Switch signal of the PTO control activator which indicates that the activator is in the position \"resume\".";
CM_ SG_ 2566844416 EngPTOCoast_DecelerateSwitch "Switch signal of the PTO control activator which indicates that the activator is in the position coast/decelerate.";
CM_ SG_ 2566844416 EngPTOSetSwitch "Switch signal of the PTO control activator which indicates that the activator is in the position set.";
CM_ SG_ 2566844416 EngRmtPTOVriableSpeedCtrlSwitch "Switch signal which indicates that the remote PTO toggle switch is in the enabled (ON) position.";
CM_ SG_ 2566844416 EngRmtPTOPrprgrmmdSpdCtrlSwitch "Switch signal which indicates that the remote PTO toggle switch is in the enabled (ON) position.";
CM_ SG_ 2566844416 EngPTOEnableSwitch "Switch signal which indicates that the PTO governor toggle switch is in the enabled position.";
CM_ SG_ 2566844416 PowerTakeoffSetSpeed "Rotational velocity selected by operator for device used to transmit engine power to auxiliary equipment.";
CM_ SG_ 2566844416 PowerTakeoffSpeed "Rotational velocity of device used to transmit engine power to auxiliary equipment.";
CM_ SG_ 2566844416 PowerTakeoffOilTemp "Temperature of lubricant in device used to transmit engine power to auxiliary equipment.";
CM_ SG_ 2566844416 RmtPTOPrprgrmmdSpeedCtrlSwitch2 "Switch signal which indicates that the remote PTO toggle switch #2 is in the enabled (ON) position.";
CM_ SG_ 2566844416 AuxInputIgnoreSwitch "Switch signal which overrides other switch input's ability to kick out of an engine's operating condition.";
CM_ BO_ 2566844928 "Fuel Economy (Liquid)";
CM_ SG_ 2566844928 EngAverageFuelEconomy "Average of instantaneous fuel economy for that segment of vehicle operation of interest.";
CM_ SG_ 2566844928 EngInstantaneousFuelEconomy "Current fuel economy at current vehicle velocity.";
CM_ SG_ 2566844928 EngFuelRate "Amount of fuel consumed by engine per unit of time.";
CM_ SG_ 2566844928 EngThrottlePos "The position of the valve used to regulate the supply of a fluid, usually air or fuel/air mixture, to an engine.";
CM_ BO_ 2566842624 "Fuel Consumption (Liquid)";
CM_ SG_ 2566842624 EngTotalFuelUsed "Accumulated amount of fuel used during vehicle operation.";
CM_ SG_ 2566842624 EngTripFuel "Fuel consumed during all or part of a journey.";
CM_ BO_ 2566831360 "Fan Drive";
CM_ SG_ 2566831360 FanSpeed "The speed of the fan associated with engine coolant system.";
CM_ SG_ 2566831360 FanDriveState "This parameter is used to indicate the current state or mode of operation by the fan drive.";
CM_ SG_ 2566831360 EstPercentFanSpeed "Estimated fan speed as a ratio of the fan drive (current speed) to the fully engaged fan drive (maximum fan speed).";
CM_ BO_ 2566824960 "Engine Temperature 2";
CM_ SG_ 2566824960 EngECUTemp "Temperature of the engine electronic control unit.";
CM_ SG_ 2566824960 EngOilTemp2 "Temperature of the engine lubricant.";
CM_ BO_ 2566843904 "Engine Temperature 1";
CM_ SG_ 2566843904 EngIntercoolerThermostatOpening "The current position of the thermostat used to regulate the temperature of the engine intercooler.";
CM_ SG_ 2566843904 EngIntercoolerTemp "Temperature of liquid found in the intercooler located after the turbocharger.";
CM_ SG_ 2566843904 EngTurboOilTemp "Temperature of the turbocharger lubricant.";
CM_ SG_ 2566843904 EngOilTemp1 "Temperature of the engine lubricant.";
CM_ SG_ 2566843904 EngFuelTemp "Temperature of fuel entering injectors.";
CM_ SG_ 2566843904 EngCoolantTemp "Temperature of liquid found in engine cooling system.";
CM_ BO_ 2566844160 "Engine Fluid Level/Pressure 1";
CM_ SG_ 2566844160 EngCoolantLevel "Ratio of volume of liquid found in engine cooling system to total cooling system volume.";
CM_ SG_ 2566844160 EngCoolantPress "Gage pressure of liquid found in engine cooling system.";
CM_ SG_ 2566844160 EngCrankcasePress "Gage pressure inside engine crankcase.";
CM_ SG_ 2566844160 EngOilPress "Gage pressure of oil in engine lubrication system as provided by oil pump.";
CM_ SG_ 2566844160 EngOilLevel "Ratio of current volume of engine sump oil to maximum required volume.";
CM_ SG_ 2566844160 EngExCrankcaseBlowbyPress "Differential crankcase blow-by pressure as measured through a tube with a venturi.";
CM_ SG_ 2566844160 EngFuelDeliveryPress "Gage pressure of fuel in system as delivered from supply pump to the injection pump.";
CM_ BO_ 2566840064 "Electronic Engine Controller 3";
CM_ SG_ 2566840064 ExhaustGasMass "Measured/calculated exhaust gas mass upstream of the after-treatment system.";
CM_ SG_ 2566840064 EngsDesiredOperatingSpeed "An indication by the engine of the optimal operating speed of the engine for the current existing conditions.";
CM_ BO_ 2364539648 "Electronic Engine Controller 2";
CM_ SG_ 2364539648 ActMaxAvailEngPercentTorque "This is the maximum amount of torque that the engine can immediately deliver as a percentage of the reference engine torque.";
CM_ SG_ 2364539648 VhclAccelerationRateLimitStatus "Status (active or not active) of the system used to limit maximum forward vehicle acceleration.";
CM_ SG_ 2364539648 AccelPedal2LowIdleSwitch "Switch signal which indicates the state of the accelerator pedal 2 low idle switch.";
CM_ SG_ 2364539648 RoadSpeedLimitStatus "Status (active or not active) of the system used to limit maximum vehicle velocity.";
CM_ SG_ 2364539648 AccelPedalKickdownSwitch "Switch signal which indicates whether the accelerator pedal kickdown switch is opened or closed.";
CM_ SG_ 2364539648 AccelPedal1LowIdleSwitch "Switch signal which indicates the state of the accelerator pedal 1 low idle switch.";
CM_ BO_ 2364539904 "Electronic Engine Controller 1";
CM_ SG_ 2364539904 EngStarterMode "There are several phases in a starting action and different reasons why a start cannot take place.";
CM_ SG_ 2364539904 SrcAddrssOfCtrllngDvcForEngCtrl "The source address of the SAE J1939 device currently controlling the engine.";
CM_ SG_ 2364539904 EngSpeed "Actual engine speed which is calculated over a minimum crankshaft angle of 720 degrees divided by the number of cylinders.";
CM_ SG_ 2364539904 ActualEngPercentTorque "The calculated output torque of the engine.";
CM_ SG_ 2364539904 DriversDemandEngPercentTorque "The requested torque output of the engine by the driver.";
CM_ SG_ 2364539904 EngTorqueMode "State signal which indicates which engine torque mode is currently generating, limiting, or controlling the torque.";
CM_ SG_ 2364539904 ActualEnginePercentTorqueHiRes "This parameter displays an additional torque in percent of the reference engine torque.";
CM_ BO_ 2566768126 "ECU Identification Information";
CM_ BO_ 2566841088 "Engine Configuration";
CM_ SG_ 2566841088 SupportTSC1CtrlPurposeGroup4Of4 "This parameter indicates which TSC1 control purposes are supported in group 4 of 4.";
CM_ SG_ 2566841088 SupportTSC1CtrlPurposeGroup3Of4 "This parameter indicates which TSC1 control purposes are supported in group 3 of 4.";
CM_ SG_ 2566841088 SupportTSC1CtrlPurposeGroup2Of4 "This parameter indicates which TSC1 control purposes are supported in group 2 of 4.";
CM_ SG_ 2566841088 SupportTSC1CtrlPurposeGroup1Of4 "This parameter indicates which TSC1 control purposes are supported in group 1 of 4.";
CM_ SG_ 2566841088 EngDefaultTorqueLimit "Companion parameter to Transmission Torque Limit (SPN 1845).";
CM_ SG_ 2566841088 EngMomentOfInertia "Moment of inertia for the engine, including items driven full-time by the engine such as fuel, oil and cooling pumps.";
CM_ SG_ 2566841088 EngRqdTorqueCtrlRangeUpperLimit "The maximum engine torque that the engine will allow when operating in a torque control/limit mode.";
CM_ SG_ 2566841088 EngRqdTorqueCtrlRangeLowerLimit "The minimum engine torque that the engine will allow when operating in a torque control/limit mode.";
CM_ SG_ 2566841088 EngRqedSpeedCtrlRangeLowerLimit "The minimum engine speed that the engine will allow when operating in a speed control/limit mode.";
CM_ SG_ 2566841088 EngMxMomentaryOverrideTimeLimit "The maximum time limit allowed to override the engine's high idle speed.";
CM_ SG_ 2566841088 EngMxMmntaryOverrideSpeedPoint7 "The maximum engine speed above high idle allowed by the engine control during a momentary high idle override.";
CM_ SG_ 2566841088 EngReferenceTorque "This parameter is the 100% reference value for all defined indicated engine torque parameters.";
CM_ SG_ 2566841088 EngSpeedAtHighIdlePoint6 "Engine speed of high idle (point 6) of the engine torque map (see PGN 65251 and supporting document).";
CM_ SG_ 2566841088 EngSpeedAtPoint5 "Engine speed of point 3, 4, and 5 of the engine torque map (see PGN 65251 and supporting document).";
CM_ SG_ 2566841088 EngSpeedAtPoint4 "Engine speed of point 3, 4, and 5 of the engine torque map (see PGN 65251 and supporting document).";
CM_ SG_ 2566841088 EngSpeedAtPoint3 "Engine speed of point 3, 4, and 5 of the engine torque map (see PGN 65251 and supporting document).";
CM_ SG_ 2566841088 EngSpeedAtPoint2 "Engine speed of point 2 of the engine torque map (see PGN 65251 and supporting document).";
CM_ SG_ 2566841088 EngPercentTorqueAtIdlePoint1 "The torque limit that indicates the available engine torque which can be provided by the engine at idle speed.";
CM_ BO_ 2566767627 "Electronic Brake Controller 5";
CM_ SG_ 2566767627 BrakeTempWarning "This parameter indicates if the temperature in the service brakes exceeds a certain value.";
CM_ SG_ 2566767627 XBRAccelerationLimit "The brake system may temporarily or generally limit the maximum brake performance available for external systems.";
CM_ SG_ 2566767627 XBRActiveCtrlMode "This parameter indicates which XBR Control Mode is executed by the brake system.";
CM_ SG_ 2566767627 XBRSystemState "This parameter indicates which external brake control is allowed.";
CM_ SG_ 2566767627 FoundationBrakeUse "This parameter indicates if the brake system presently uses the foundation brakes.";
CM_ SG_ 2566767627 HillHolderMode "Signal which indicates the current mode of the hill holder function.";
CM_ SG_ 2566767627 HaltBrakeMode "Signal which indicates the current mode of the halt brake function.";
CM_ BO_ 2633935883 "Wheel Brake Lining Remaining Information";
CM_ SG_ 2633935883 BrkLnngRmnngRearAxle3RightWheel "The percentage of brake lining which can still be measured for the right wheel on the rear axle #3.";
CM_ SG_ 2633935883 BrkLnngRmningRearAxle3LeftWheel "The percentage of brake lining which can still be measured for the left wheel on the rear axle #3.";
CM_ SG_ 2633935883 BrkLnngRmnngRearAxle2RightWheel "The percentage of brake lining which can still be measured for the right wheel on the rear axle #2.";
CM_ SG_ 2633935883 BrkLnngRmningRearAxle2LeftWheel "The percentage of brake lining which can still be measured for the left wheel on the rear axle #2.";
CM_ SG_ 2633935883 BrkLnngRmnngRearAxle1RightWheel "The percentage of brake lining which can still be measured for the right wheel on the rear axle #1.";
CM_ SG_ 2633935883 BrkLnngRmningRearAxle1LeftWheel "The percentage of brake lining which can still be measured for the left wheel on the rear axle #1.";
CM_ SG_ 2633935883 BrkLnngRmnngFrontAxleRightWheel "The percentage of brake lining which can still be measured for the right wheel on the front axle.";
CM_ SG_ 2633935883 BrkLnngRmningFrontAxleLeftWheel "The percentage of brake lining which can still be measured for the left wheel on the front axle.";
CM_ BO_ 2566827275 "Wheel Application Pressure High Range Information";
CM_ SG_ 2566827275 BrkAppPrssHghRngRrAxl3RghtWheel "The brake application pressure for the right wheel on the rear axle #3.";
CM_ SG_ 2566827275 BrkAppPrssHghRngRrAxl3LeftWheel "The brake application pressure for the left wheel on the rear axle #3.";
CM_ SG_ 2566827275 BrkAppPrssHghRngRrAxl2RghtWheel "The brake application pressure for the right wheel on the rear axle #2.";
CM_ SG_ 2566827275 BrkAppPrssHghRngRrAxl2LeftWheel "The brake application pressure for the left wheel on the rear axle #2.";
CM_ SG_ 2566827275 BrkAppPrssHghRngRrAxl1RghtWheel "The brake application pressure for the right wheel on the rear axle #1.";
CM_ SG_ 2566827275 BrkAppPrssHghRngRrAxl1LeftWheel "The brake application pressure for the left wheel on the rear axle #1.";
CM_ SG_ 2566827275 BrkAppPrssHghRngFrntAxlRghtWhel "The brake application pressure for the right wheel on the front axle.";
CM_ SG_ 2566827275 BrkAppPrssHghRngFrntAxlLftWheel "The brake application pressure for the left wheel on the front axle.";
CM_ BO_ 2566831883 "Wheel Speed Information";
CM_ SG_ 2566831883 RlativeSpeedRearAxle2RightWheel "The speed of the rear axle #2, right wheel relative to the front axle speed, SPN 904.";
CM_ SG_ 2566831883 RelativeSpeedRearAxle2LeftWheel "The speed of the rear axle #2, left wheel relative to the front axle speed, SPN 904.";
CM_ SG_ 2566831883 RlativeSpeedRearAxle1RightWheel "The speed of the rear axle #1, right wheel relative to the front axle speed, SPN 904.";
CM_ SG_ 2566831883 RelativeSpeedRearAxle1LeftWheel "The speed of the rear axle #1, left wheel relative to the front axle speed, SPN 904.";
CM_ SG_ 2566831883 RlativeSpeedFrontAxleRightWheel "The speed of the front axle, right wheel relative to the front axle speed, SPN 904.";
CM_ SG_ 2566831883 RelativeSpeedFrontAxleLeftWheel "The speed of the front axle, left wheel relative to the front axle speed, SPN 904.";
CM_ SG_ 2566831883 FrontAxleSpeed "The average speed of the two front wheels.";
CM_ BO_ 2565865739 "Electronic Brake Controller 1";
CM_ SG_ 2565865739 SrcAddrssOfCtrllngDvcFrBrkCntrl "The source address of the SAE J1939 device currently controlling the brake system.";
CM_ SG_ 2565865739 BrakePedalPos "Ratio of brake pedal position to maximum pedal position.";
CM_ SG_ 2565865739 TrctrMntdTrilerABSWarningSignal "This parameter commands the tractor-mounted trailer ABS optical warning signal.";
CM_ SG_ 2565865739 TrailerABSStatus "State signal which indicates that ABS in the trailer is actively controlling the brakes.";
CM_ SG_ 2565865739 HaltBrakeSwitch "Switch signal which indicates the position of the halt brake switch.";
CM_ SG_ 2565865739 ATC_ASRInformationSignal "This parameter commands the ATC/ASR driver information signal, for example a dash lamp.";
CM_ SG_ 2565865739 RemoteAccelEnableSwitch "Switch signal which indicates that the remote accelerator has been enabled and controls the engine.";
CM_ SG_ 2565865739 EngAuxEngShutdownSwitch "Switch signal which requests that all engine fueling stop.";
CM_ SG_ 2565865739 EngDerateSwitch "Switch signal used to activate the torque limiting feature of the engine.";
CM_ SG_ 2565865739 AccelInterlockSwitch "Switch signal used to disable the accelerator and remote accelerator inputs, causing the engine to return to idle.";
CM_ SG_ 2565865739 TractionCtrlOverrideSwitch "Switch signal which indicates the position of the traction control override switch.";
CM_ SG_ 2565865739 ASRHillHolderSwitch "Switch signal which indicates the position of the ASR “hill holder” switch.";
CM_ SG_ 2565865739 ASROffroadSwitch "Switch signal which indicates the position of the ASR off-road switch.";
CM_ SG_ 2565865739 ABSOffroadSwitch "Switch signal which indicates the position of the ABS off-road switch.";
CM_ SG_ 2565865739 EBSBrakeSwitch "Switch signal which indicates that the brake pedal is being pressed.";
CM_ SG_ 2565865739 AntiLockBrakingActive "State signal which indicates that the ABS is active.";
CM_ SG_ 2565865739 ASRBrakeCtrlActive "State signal which indicates that ASR brake control is active.";
CM_ SG_ 2565865739 ASREngCtrlActive "State signal which indicates that ASR engine control has been commanded to be active.";
CM_ BO_ 2566844672 "Cruise Control/Vehicle Speed";
CM_ SG_ 2566844672 EngShutdownOverrideSwitch "Switch signal which indicates the position of the engine shutdown override switch.";
CM_ SG_ 2566844672 EngTestModeSwitch "Switch signal which indicates the position of the engine test mode switch.";
CM_ SG_ 2566844672 EngIdleDecrementSwitch "Switch signal which indicates the position of the idle decrement switch.";
CM_ SG_ 2566844672 EngIdleIncrementSwitch "Switch signal which indicates the position of the idle increment switch.";
CM_ SG_ 2566844672 CruiseCtrlStates "This parameter is used to indicate the current state, or mode, of operation by the cruise control device.";
CM_ SG_ 2566844672 PTOState "This parameter is used to indicate the current state or mode of operation by the power takeoff (PTO) device.";
CM_ SG_ 2566844672 CruiseCtrlSetSpeed "Value of set (chosen) velocity of velocity control system.";
CM_ SG_ 2566844672 CruiseCtrlAccelerateSwitch "Switch signal of the cruise control activator which indicates that the activator is in the position “accelerate.";
CM_ SG_ 2566844672 CruiseCtrlResumeSwitch "Switch signal of the cruise control activator which indicates that the activator is in the position “resume.";
CM_ SG_ 2566844672 CruiseCtrlCoastSwitch "Switch signal of the cruise control activator which indicates that the activator is in the position “coast (decelerate).";
CM_ SG_ 2566844672 CruiseCtrlSetSwitch "Switch signal of the cruise control activator which indicates that the activator is in the position “set.";
CM_ SG_ 2566844672 ClutchSwitch "Switch signal which indicates that the clutch pedal is being pressed.";
CM_ SG_ 2566844672 BrakeSwitch "Switch signal which indicates that the driver operated brake foot pedal is being pressed.";
CM_ SG_ 2566844672 CruiseCtrlEnableSwitch "Switch signal which indicates that it is possible to manage the cruise control function.";
CM_ SG_ 2566844672 CruiseCtrlActive "Cruise control is switched on.";
CM_ SG_ 2566844672 WheelBasedVehicleSpeed "Speed of the vehicle as calculated from wheel or tailshaft speed.";
CM_ SG_ 2566844672 CruiseCtrlPauseSwitch "Switch signal which indicates the position of the Cruise Control Pause Switch used on Remote Cruise Control applications.";
CM_ SG_ 2566844672 ParkingBrakeSwitch "Switch signal which indicates when the parking brake is set.";
CM_ SG_ 2566844672 TwoSpeedAxleSwitch "Switch signal which indicates the current axle range.";
CM_ BO_ 2565799678 "Address Claimed";
CM_ SG_ 2565799678 IndustryGroup "0 = Global; 
   1  = On-Highway; 
   2  = Agricultural and Forestry; 
   3  = Construction; 
   4  = Marine;
   5  = Industrial - Process
          Control - Stationary (Gen-Sets)
   6  = Reserve for SAE
   7  = Reserve for SAE";
CM_ SG_ 2565799678 ManufacturerCode "Assigned by NMEA 2000 Committee";
CM_ BO_ 2563440382 "Transfer";
CM_ SG_ 2563440382 ShrtNameOfActualReportingDevice "Short name of reporting device of the requested PGN via the Transfer PGN.";
CM_ SG_ 2563440382 LengthOfDataForTheReportedPGN "Length of data reported with the associated PGN via the Transfer PGN.";
CM_ SG_ 2563440382 PGNofRequstedInformation "PGN associated with this transfer message";
CM_ BO_ 2565603070 "Transport Protocol - Data Transfer";
CM_ BO_ 2565668606 "Transport Protocol - Connection Management";
CM_ SG_ 2565668606 TotalNumberOfPacketsEoMA "Total number of packets for BAM message.Total number of packets received for RTS/CTS message.Total number of packets for RTS/CTS message.";
CM_ SG_ 2565668606 TotalMessageSizeEoMA "Total message size (in bytes) for BAM message.Total message size (in bytes) for RTS/CTS message.Total message size (in bytes) for RTS/CTS message.";
CM_ SG_ 2565668606 TotalMessageSizeBAM "Total message size (in bytes) for BAM message.Total message size (in bytes) for RTS/CTS message.Total message size (in bytes) for RTS/CTS message.";
CM_ SG_ 2565668606 TotalNumberOfPacketsBAM "Total number of packets for BAM message.Total number of packets received for RTS/CTS message.Total number of packets for RTS/CTS message.";
CM_ SG_ 2565668606 ConnectionAbortReason "Reason for connection abort message.";
CM_ SG_ 2565668606 NextPacketNumberToBeSent "Next Packet Number to be sent (TP.CM_CTS)";
CM_ SG_ 2565668606 NumberOfPacketsThatCanBeSent "Number of Packets that can be sent (TP.CM_CTS)";
CM_ SG_ 2565668606 MaximumNumberOfPackets "Maximum number of packets for RTS/CTS message.";
CM_ SG_ 2565668606 TotalNumberOfPackets "Total number of packets for BAM message.Total number of packets received for RTS/CTS message.Total number of packets for RTS/CTS message.";
CM_ SG_ 2565668606 TotalMessageSize "Total message size (in bytes) for BAM message.Total message size (in bytes) for RTS/CTS message.Total message size (in bytes) for RTS/CTS message.";
CM_ BO_ 2563374846 "Request 2";
CM_ SG_ 2563374846 UseTransferMode "Requester is to respond via the Transfer PGN";
CM_ SG_ 2563374846 ParameterGroupNumber "PGN which is requested by Request2 message";
CM_ BO_ 2565537534 "Request";
CM_ SG_ 2565537534 ParameterGroupNumber "PGN which is requested by Request2 message";
CM_ BO_ 2565406462 "Acknowledgment Message";
CM_ SG_ 2565406462 ParameterGroupNumber "PGN which is requested by Request2 message";
CM_ SG_ 2565406462 GroupFunctionValue "Group Function of PGN being acknowledged. This field identifies for a device the specific group function of a PGN being acknowledged or declined.  This field is not used if the PGN being acknowledged or declined is not a group function PGN.";
BA_DEF_ SG_  "SigType" ENUM  "Default","Range","RangeSigned","ASCII","Discrete","Control","ReferencePGN","DTC","StringDelimiter","StringLength","StringLengthControl","MessageCounter","MessageChecksum","LowerPartOfSPN";
BA_DEF_ SG_  "GenSigStartValue" INT 0 10000;
BA_DEF_ SG_  "GenSigSendType" ENUM  "Cyclic","OnWrite","OnWriteWithRepetition","OnChange","OnChangeWithRepetition","IfActive","IfActiveWithRepetition","NoSigSendType";
BA_DEF_ SG_  "GenSigILSupport" ENUM  "No","Yes";
BA_DEF_ SG_  "GenSigEVName" STRING ;
BA_DEF_ SG_  "SPN" INT 0 524287;
BA_DEF_ BO_  "GenMsgStartDelayTime" INT 0 100000;
BA_DEF_ BO_  "GenMsgILSupport" ENUM  "No","Yes";
BA_DEF_ BO_  "GenMsgDelayTime" INT 0 1000;
BA_DEF_ BO_  "GenMsgRequestable" INT 0 1;
BA_DEF_ BO_  "GenMsgSendType" ENUM  "cyclic","NotUsed","NotUsed","NotUsed","NotUsed","NotUsed","NotUsed","IfActive","noMsgSendType";
BA_DEF_ BO_  "VFrameFormat" ENUM  "StandardCAN","ExtendedCAN","reserved","J1939PG";
BA_DEF_ BO_  "GenMsgCycleTime" INT 0 3600000;
BA_DEF_ SG_  "SystemSignalLongSymbol" STRING ;
BA_DEF_DEF_  "SigType" "Default";
BA_DEF_DEF_  "GenSigStartValue" 0;
BA_DEF_DEF_  "GenSigSendType" "NoSigSendType";
BA_DEF_DEF_  "GenSigILSupport" "Yes";
BA_DEF_DEF_  "GenSigEVName" "Env@Nodename_@Signame";
BA_DEF_DEF_  "SPN" 0;
BA_DEF_DEF_  "GenMsgStartDelayTime" 0;
BA_DEF_DEF_  "GenMsgILSupport" "Yes";
BA_DEF_DEF_  "GenMsgDelayTime" 0;
BA_DEF_DEF_  "GenMsgRequestable" 1;
BA_DEF_DEF_  "GenMsgSendType" "noMsgSendType";
BA_DEF_DEF_  "VFrameFormat" "J1939PG";
BA_DEF_DEF_  "GenMsgCycleTime" 0;
BA_DEF_DEF_  "SystemSignalLongSymbol" "";
BA_ "GenMsgSendType" BO_ 2566845952 0;
BA_ "GenMsgCycleTime" BO_ 2566845952 500;
BA_ "GenMsgSendType" BO_ 2566832384 0;
BA_ "GenMsgCycleTime" BO_ 2566832384 1000;
BA_ "GenMsgSendType" BO_ 2565867787 0;
BA_ "GenMsgCycleTime" BO_ 2565867787 10;
BA_ "GenMsgSendType" BO_ 2566803211 0;
BA_ "GenMsgCycleTime" BO_ 2566803211 100;
BA_ "GenMsgSendType" BO_ 2566840320 0;
BA_ "GenMsgCycleTime" BO_ 2566840320 100;
BA_ "GenMsgSendType" BO_ 2566839552 0;
BA_ "GenMsgCycleTime" BO_ 2566839552 1000;
BA_ "GenMsgSendType" BO_ 2566841344 0;
BA_ "GenMsgCycleTime" BO_ 2566841344 1000;
BA_ "GenMsgSendType" BO_ 2566844416 0;
BA_ "GenMsgCycleTime" BO_ 2566844416 100;
BA_ "GenMsgSendType" BO_ 2566844928 0;
BA_ "GenMsgCycleTime" BO_ 2566844928 100;
BA_ "GenMsgSendType" BO_ 2566831360 0;
BA_ "GenMsgCycleTime" BO_ 2566831360 1000;
BA_ "GenMsgSendType" BO_ 2566824960 0;
BA_ "GenMsgCycleTime" BO_ 2566824960 1000;
BA_ "GenMsgSendType" BO_ 2566843904 0;
BA_ "GenMsgCycleTime" BO_ 2566843904 1000;
BA_ "GenMsgSendType" BO_ 2566844160 0;
BA_ "GenMsgCycleTime" BO_ 2566844160 500;
BA_ "GenMsgSendType" BO_ 2566840064 0;
BA_ "GenMsgCycleTime" BO_ 2566840064 250;
BA_ "GenMsgSendType" BO_ 2364539648 0;
BA_ "GenMsgCycleTime" BO_ 2364539648 50;
BA_ "GenMsgSendType" BO_ 2364539904 0;
BA_ "GenMsgCycleTime" BO_ 2364539904 100;
BA_ "GenMsgSendType" BO_ 2566767627 0;
BA_ "GenMsgCycleTime" BO_ 2566767627 100;
BA_ "GenMsgSendType" BO_ 2566827275 0;
BA_ "GenMsgCycleTime" BO_ 2566827275 100;
BA_ "GenMsgSendType" BO_ 2566831883 0;
BA_ "GenMsgCycleTime" BO_ 2566831883 100;
BA_ "GenMsgSendType" BO_ 2565865739 0;
BA_ "GenMsgCycleTime" BO_ 2565865739 100;
BA_ "GenMsgSendType" BO_ 2566844672 0;
BA_ "GenMsgCycleTime" BO_ 2566844672 100;
BA_ "SPN" SG_ 2566836222 SpnConversionMethod1 1706;
BA_ "SPN" SG_ 2566836222 SpnConversionMethod5 1706;
BA_ "SPN" SG_ 2566836222 SpnConversionMethod4 1706;
BA_ "SPN" SG_ 2566836222 SpnConversionMethod3 1706;
BA_ "SPN" SG_ 2566836222 SpnConversionMethod2 1706;
BA_ "SPN" SG_ 2566836222 OccurenceCount5 1216;
BA_ "SPN" SG_ 2566836222 OccurenceCount4 1216;
BA_ "SPN" SG_ 2566836222 OccurenceCount3 1216;
BA_ "SPN" SG_ 2566836222 OccurenceCount2 1216;
BA_ "SPN" SG_ 2566836222 OccurenceCount1 1216;
BA_ "SPN" SG_ 2566836222 FMI5 4149;
BA_ "SPN" SG_ 2566836222 FMI4 4149;
BA_ "SPN" SG_ 2566836222 FMI3 4149;
BA_ "SPN" SG_ 2566836222 FMI2 4149;
BA_ "SPN" SG_ 2566836222 FMI1 4149;
BA_ "SigType" SG_ 2566836222 FlashRedStopLamp 5;
BA_ "SPN" SG_ 2566836222 FlashRedStopLamp 3039;
BA_ "SigType" SG_ 2566836222 FlashProtectLamp 5;
BA_ "SPN" SG_ 2566836222 FlashProtectLamp 3041;
BA_ "SigType" SG_ 2566836222 FlashMalfuncIndicatorLamp 5;
BA_ "SPN" SG_ 2566836222 FlashMalfuncIndicatorLamp 3038;
BA_ "SigType" SG_ 2566836222 FlashAmberWarningLamp 5;
BA_ "SPN" SG_ 2566836222 FlashAmberWarningLamp 3040;
BA_ "SigType" SG_ 2566836222 MalfunctionIndLampStatus 5;
BA_ "SPN" SG_ 2566836222 MalfunctionIndLampStatus 1213;
BA_ "SigType" SG_ 2566836222 AmberWarningLampStatus 5;
BA_ "SPN" SG_ 2566836222 AmberWarningLampStatus 624;
BA_ "SigType" SG_ 2566836222 RedStopLampState 4;
BA_ "SPN" SG_ 2566836222 RedStopLampState 623;
BA_ "SigType" SG_ 2566836222 ProtectLampStatus 5;
BA_ "SPN" SG_ 2566836222 ProtectLampStatus 987;
BA_ "SigType" SG_ 2566836222 SPN5 13;
BA_ "SigType" SG_ 2566836222 SPN4 13;
BA_ "SigType" SG_ 2566836222 SPN3 13;
BA_ "SigType" SG_ 2566836222 SPN2 13;
BA_ "SigType" SG_ 2566836222 SPN1 13;
BA_ "SystemSignalLongSymbol" SG_ 2566835966 BoostPressureControlSystemSuppor "BoostPressureControlSystemSupport";
BA_ "SigType" SG_ 2566835966 OBDCompliance 1;
BA_ "SPN" SG_ 2566835966 OBDCompliance 1220;
BA_ "SigType" SG_ 2566835966 PreviouslyActiveTroubleCodes 1;
BA_ "SPN" SG_ 2566835966 PreviouslyActiveTroubleCodes 1219;
BA_ "SigType" SG_ 2566835966 ActiveTroubleCodes 1;
BA_ "SPN" SG_ 2566835966 ActiveTroubleCodes 1218;
BA_ "SPN" SG_ 2566835710 SpnConversionMethod 1706;
BA_ "SPN" SG_ 2566835710 OccurenceCount 1216;
BA_ "SPN" SG_ 2566835710 FMI 1215;
BA_ "SigType" SG_ 2566835710 EngineIntakeManifold1Pressure 1;
BA_ "SPN" SG_ 2566835710 EngineIntakeManifold1Pressure 102;
BA_ "SPN" SG_ 2566835710 FreezeFrameLength 1217;
BA_ "SigType" SG_ 2566835710 Speed 1;
BA_ "SPN" SG_ 2566835710 Speed 190;
BA_ "SPN" SG_ 2566835710 TorqueMode 899;
BA_ "SigType" SG_ 2566835710 WheelBasedVS 1;
BA_ "SPN" SG_ 2566835710 WheelBasedVS 84;
BA_ "SigType" SG_ 2566835710 PercentLoadAtCurrentSpeed 1;
BA_ "SPN" SG_ 2566835710 PercentLoadAtCurrentSpeed 92;
BA_ "SigType" SG_ 2566835710 CoolantTemperature 1;
BA_ "SPN" SG_ 2566835710 CoolantTemperature 110;
BA_ "SigType" SG_ 2566835710 SPN 13;
BA_ "SPN" SG_ 2566835710 SPN 1214;
BA_ "SPN" SG_ 2566835198 SpnConversionMethod1 1706;
BA_ "SPN" SG_ 2566835198 SpnConversionMethod5 1706;
BA_ "SPN" SG_ 2566835198 SpnConversionMethod4 1706;
BA_ "SPN" SG_ 2566835198 SpnConversionMethod3 1706;
BA_ "SPN" SG_ 2566835198 SpnConversionMethod2 1706;
BA_ "SPN" SG_ 2566835198 OccurenceCount5 1216;
BA_ "SPN" SG_ 2566835198 OccurenceCount4 1216;
BA_ "SPN" SG_ 2566835198 OccurenceCount3 1216;
BA_ "SPN" SG_ 2566835198 OccurenceCount2 1216;
BA_ "SPN" SG_ 2566835198 OccurenceCount1 1216;
BA_ "SPN" SG_ 2566835198 FMI5 4149;
BA_ "SPN" SG_ 2566835198 FMI4 4149;
BA_ "SPN" SG_ 2566835198 FMI3 4149;
BA_ "SPN" SG_ 2566835198 FMI2 4149;
BA_ "SPN" SG_ 2566835198 FMI1 4149;
BA_ "SigType" SG_ 2566835198 FlashRedStopLamp 5;
BA_ "SPN" SG_ 2566835198 FlashRedStopLamp 3039;
BA_ "SigType" SG_ 2566835198 FlashProtectLamp 5;
BA_ "SPN" SG_ 2566835198 FlashProtectLamp 3041;
BA_ "SigType" SG_ 2566835198 FlashMalfuncIndicatorLamp 5;
BA_ "SPN" SG_ 2566835198 FlashMalfuncIndicatorLamp 3038;
BA_ "SigType" SG_ 2566835198 FlashAmberWarningLamp 5;
BA_ "SPN" SG_ 2566835198 FlashAmberWarningLamp 3040;
BA_ "SigType" SG_ 2566835198 MalfunctionIndLampStatus 5;
BA_ "SPN" SG_ 2566835198 MalfunctionIndLampStatus 1213;
BA_ "SigType" SG_ 2566835198 AmberWarningLampStatus 5;
BA_ "SPN" SG_ 2566835198 AmberWarningLampStatus 624;
BA_ "SigType" SG_ 2566835198 RedStopLampState 4;
BA_ "SPN" SG_ 2566835198 RedStopLampState 623;
BA_ "SigType" SG_ 2566835198 ProtectLampStatus 5;
BA_ "SPN" SG_ 2566835198 ProtectLampStatus 987;
BA_ "SigType" SG_ 2566835198 SPN5 13;
BA_ "SigType" SG_ 2566835198 SPN4 13;
BA_ "SigType" SG_ 2566835198 SPN3 13;
BA_ "SigType" SG_ 2566835198 SPN2 13;
BA_ "SigType" SG_ 2566835198 SPN1 13;
BA_ "SPN" SG_ 2566834942 SpnConversionMethod1 1706;
BA_ "SPN" SG_ 2566834942 SpnConversionMethod5 1706;
BA_ "SPN" SG_ 2566834942 SpnConversionMethod4 1706;
BA_ "SPN" SG_ 2566834942 SpnConversionMethod3 1706;
BA_ "SPN" SG_ 2566834942 SpnConversionMethod2 1706;
BA_ "SPN" SG_ 2566834942 OccurenceCount5 1216;
BA_ "SPN" SG_ 2566834942 OccurenceCount4 1216;
BA_ "SPN" SG_ 2566834942 OccurenceCount3 1216;
BA_ "SPN" SG_ 2566834942 OccurenceCount2 1216;
BA_ "SPN" SG_ 2566834942 OccurenceCount1 1216;
BA_ "SPN" SG_ 2566834942 FMI5 4149;
BA_ "SPN" SG_ 2566834942 FMI4 4149;
BA_ "SPN" SG_ 2566834942 FMI3 4149;
BA_ "SPN" SG_ 2566834942 FMI2 4149;
BA_ "SPN" SG_ 2566834942 FMI1 4149;
BA_ "SigType" SG_ 2566834942 FlashRedStopLamp 5;
BA_ "SPN" SG_ 2566834942 FlashRedStopLamp 3039;
BA_ "SigType" SG_ 2566834942 FlashProtectLamp 5;
BA_ "SPN" SG_ 2566834942 FlashProtectLamp 3041;
BA_ "SigType" SG_ 2566834942 FlashMalfuncIndicatorLamp 5;
BA_ "SPN" SG_ 2566834942 FlashMalfuncIndicatorLamp 3038;
BA_ "SigType" SG_ 2566834942 FlashAmberWarningLamp 5;
BA_ "SPN" SG_ 2566834942 FlashAmberWarningLamp 3040;
BA_ "SigType" SG_ 2566834942 MalfunctionIndLampStatus 5;
BA_ "SPN" SG_ 2566834942 MalfunctionIndLampStatus 1213;
BA_ "SigType" SG_ 2566834942 AmberWarningLampStatus 5;
BA_ "SPN" SG_ 2566834942 AmberWarningLampStatus 624;
BA_ "SigType" SG_ 2566834942 RedStopLampState 4;
BA_ "SPN" SG_ 2566834942 RedStopLampState 623;
BA_ "SigType" SG_ 2566834942 ProtectLampStatus 5;
BA_ "SPN" SG_ 2566834942 ProtectLampStatus 987;
BA_ "SigType" SG_ 2566834942 SPN5 13;
BA_ "SigType" SG_ 2566834942 SPN4 13;
BA_ "SigType" SG_ 2566834942 SPN3 13;
BA_ "SigType" SG_ 2566834942 SPN2 13;
BA_ "SigType" SG_ 2566834942 SPN1 13;
BA_ "SPN" SG_ 2348820747 MessageCounter 4206;
BA_ "SPN" SG_ 2348820747 MessageChecksum 4207;
BA_ "SPN" SG_ 2348820747 ControlPurpose 3350;
BA_ "SPN" SG_ 2348820747 TransmissionRate 3349;
BA_ "SigType" SG_ 2348820747 EngRqedTorque_TorqueLimit 1;
BA_ "SPN" SG_ 2348820747 EngRqedTorque_TorqueLimit 518;
BA_ "SigType" SG_ 2348820747 EngRqedSpeed_SpeedLimit 1;
BA_ "SPN" SG_ 2348820747 EngRqedSpeed_SpeedLimit 898;
BA_ "SigType" SG_ 2348820747 OverrideCtrlModePriority 4;
BA_ "SPN" SG_ 2348820747 OverrideCtrlModePriority 897;
BA_ "SigType" SG_ 2348820747 EngRqedSpeedCtrlConditions 4;
BA_ "SPN" SG_ 2348820747 EngRqedSpeedCtrlConditions 696;
BA_ "SigType" SG_ 2348820747 EngOverrideCtrlMode 4;
BA_ "SPN" SG_ 2348820747 EngOverrideCtrlMode 695;
BA_ "SPN" SG_ 2348820747 EngineRequestedTorqueHiRes 4191;
BA_ "SPN" SG_ 2348875275 MessageCounter 4206;
BA_ "SPN" SG_ 2348875275 MessageChecksum 4207;
BA_ "SPN" SG_ 2348875275 ControlPurpose 3350;
BA_ "SPN" SG_ 2348875275 TransmissionRate 3349;
BA_ "SigType" SG_ 2348875275 EngRqedTorque_TorqueLimit 1;
BA_ "SPN" SG_ 2348875275 EngRqedTorque_TorqueLimit 518;
BA_ "SigType" SG_ 2348875275 EngRqedSpeed_SpeedLimit 1;
BA_ "SPN" SG_ 2348875275 EngRqedSpeed_SpeedLimit 898;
BA_ "SigType" SG_ 2348875275 OverrideCtrlModePriority 4;
BA_ "SPN" SG_ 2348875275 OverrideCtrlModePriority 897;
BA_ "SigType" SG_ 2348875275 EngRqedSpeedCtrlConditions 4;
BA_ "SPN" SG_ 2348875275 EngRqedSpeedCtrlConditions 696;
BA_ "SigType" SG_ 2348875275 EngOverrideCtrlMode 4;
BA_ "SPN" SG_ 2348875275 EngOverrideCtrlMode 695;
BA_ "SPN" SG_ 2348875275 EngineRequestedTorqueHiRes 4191;
BA_ "SPN" SG_ 2348810251 MessageCounter 4206;
BA_ "SPN" SG_ 2348810251 MessageChecksum 4207;
BA_ "SPN" SG_ 2348810251 ControlPurpose 3350;
BA_ "SPN" SG_ 2348810251 TransmissionRate 3349;
BA_ "SigType" SG_ 2348810251 EngRqedTorque_TorqueLimit 1;
BA_ "SPN" SG_ 2348810251 EngRqedTorque_TorqueLimit 518;
BA_ "SigType" SG_ 2348810251 EngRqedSpeed_SpeedLimit 1;
BA_ "SPN" SG_ 2348810251 EngRqedSpeed_SpeedLimit 898;
BA_ "SigType" SG_ 2348810251 OverrideCtrlModePriority 4;
BA_ "SPN" SG_ 2348810251 OverrideCtrlModePriority 897;
BA_ "SigType" SG_ 2348810251 EngRqedSpeedCtrlConditions 4;
BA_ "SPN" SG_ 2348810251 EngRqedSpeedCtrlConditions 696;
BA_ "SigType" SG_ 2348810251 EngOverrideCtrlMode 4;
BA_ "SPN" SG_ 2348810251 EngOverrideCtrlMode 695;
BA_ "SPN" SG_ 2348810251 EngineRequestedTorqueHiRes 4191;
BA_ "SigType" SG_ 2633935104 EngDesiredRatedExhaustOxygen 1;
BA_ "SPN" SG_ 2633935104 EngDesiredRatedExhaustOxygen 1117;
BA_ "SigType" SG_ 2633935104 EngDesiredExhaustOxygen 1;
BA_ "SPN" SG_ 2633935104 EngDesiredExhaustOxygen 1118;
BA_ "SigType" SG_ 2633935104 EngActualExhaustOxygen 1;
BA_ "SPN" SG_ 2633935104 EngActualExhaustOxygen 1119;
BA_ "SigType" SG_ 2633935104 EngExhstGsOxygnSnsrFlngCrrction 1;
BA_ "SPN" SG_ 2633935104 EngExhstGsOxygnSnsrFlngCrrction 1695;
BA_ "SigType" SG_ 2633935104 EngExhstGsOxygnSnsrClsdLpOprton 4;
BA_ "SPN" SG_ 2633935104 EngExhstGsOxygnSnsrClsdLpOprton 1696;
BA_ "SigType" SG_ 2566845952 EngCoolantFilterDiffPress 1;
BA_ "SPN" SG_ 2566845952 EngCoolantFilterDiffPress 112;
BA_ "SigType" SG_ 2566845952 EngExhaustGasTemp 1;
BA_ "SPN" SG_ 2566845952 EngExhaustGasTemp 173;
BA_ "SigType" SG_ 2566845952 EngAirFilter1DiffPress 1;
BA_ "SPN" SG_ 2566845952 EngAirFilter1DiffPress 107;
BA_ "SigType" SG_ 2566845952 EngAirInletPress 1;
BA_ "SPN" SG_ 2566845952 EngAirInletPress 106;
BA_ "SigType" SG_ 2566845952 EngIntakeManifold1Temp 1;
BA_ "SPN" SG_ 2566845952 EngIntakeManifold1Temp 105;
BA_ "SigType" SG_ 2566845952 EngTurboBoostPress 1;
BA_ "SPN" SG_ 2566845952 EngTurboBoostPress 102;
BA_ "SigType" SG_ 2566845952 EngParticulateTrapInletPress 1;
BA_ "SPN" SG_ 2566845952 EngParticulateTrapInletPress 81;
BA_ "SigType" SG_ 2566841600 EngTotalRevolutions 1;
BA_ "SPN" SG_ 2566841600 EngTotalRevolutions 249;
BA_ "SigType" SG_ 2566841600 EngTotalHoursOfOperation 1;
BA_ "SPN" SG_ 2566841600 EngTotalHoursOfOperation 247;
BA_ "SigType" SG_ 2566843392 VehicleIdentificationNumber 8;
BA_ "SPN" SG_ 2566843392 VehicleIdentificationNumber 237;
BA_ "SigType" SG_ 2566832384 HighResolutionTripDistance 1;
BA_ "SPN" SG_ 2566832384 HighResolutionTripDistance 918;
BA_ "SigType" SG_ 2566832384 HghRslutionTotalVehicleDistance 1;
BA_ "SPN" SG_ 2566832384 HghRslutionTotalVehicleDistance 917;
BA_ "SigType" SG_ 2565867787 LongitudinalAcceleration 1;
BA_ "SPN" SG_ 2565867787 LongitudinalAcceleration 1810;
BA_ "SigType" SG_ 2565867787 LateralAcceleration 1;
BA_ "SPN" SG_ 2565867787 LateralAcceleration 1809;
BA_ "SigType" SG_ 2565867787 YawRate 1;
BA_ "SPN" SG_ 2565867787 YawRate 1808;
BA_ "SigType" SG_ 2565867787 SteerWheelAngleSensorType 4;
BA_ "SPN" SG_ 2565867787 SteerWheelAngleSensorType 1812;
BA_ "SPN" SG_ 2565867787 SteerWheelTurnCounter 1811;
BA_ "SigType" SG_ 2565867787 SteerWheelAngle 1;
BA_ "SPN" SG_ 2565867787 SteerWheelAngle 1807;
BA_ "SigType" SG_ 2566803211 YCBrakeCtrlActive 4;
BA_ "SPN" SG_ 2566803211 YCBrakeCtrlActive 1819;
BA_ "SigType" SG_ 2566803211 YCEngCtrlActive 4;
BA_ "SPN" SG_ 2566803211 YCEngCtrlActive 1817;
BA_ "SigType" SG_ 2566803211 ROPBrakeCtrlActive 4;
BA_ "SPN" SG_ 2566803211 ROPBrakeCtrlActive 1818;
BA_ "SigType" SG_ 2566803211 ROPEngCtrlActive 4;
BA_ "SPN" SG_ 2566803211 ROPEngCtrlActive 1816;
BA_ "SigType" SG_ 2566803211 VDCBrakeLightRq 4;
BA_ "SPN" SG_ 2566803211 VDCBrakeLightRq 1815;
BA_ "SigType" SG_ 2566803211 VDCFullyOperational 4;
BA_ "SPN" SG_ 2566803211 VDCFullyOperational 1814;
BA_ "SigType" SG_ 2566803211 VDCInformationSignal 4;
BA_ "SPN" SG_ 2566803211 VDCInformationSignal 1813;
BA_ "SigType" SG_ 2566840320 TotalVehicleDistance 1;
BA_ "SPN" SG_ 2566840320 TotalVehicleDistance 245;
BA_ "SigType" SG_ 2566840320 TripDistance 1;
BA_ "SPN" SG_ 2566840320 TripDistance 244;
BA_ "SPN" SG_ 2348875518 MessageCounter 4206;
BA_ "SPN" SG_ 2348875518 MessageChecksum 4207;
BA_ "SPN" SG_ 2348875518 ControlPurpose 3350;
BA_ "SPN" SG_ 2348875518 TransmissionRate 3349;
BA_ "SigType" SG_ 2348875518 EngRqedTorque_TorqueLimit 1;
BA_ "SPN" SG_ 2348875518 EngRqedTorque_TorqueLimit 518;
BA_ "SigType" SG_ 2348875518 EngRqedSpeed_SpeedLimit 1;
BA_ "SPN" SG_ 2348875518 EngRqedSpeed_SpeedLimit 898;
BA_ "SigType" SG_ 2348875518 OverrideCtrlModePriority 4;
BA_ "SPN" SG_ 2348875518 OverrideCtrlModePriority 897;
BA_ "SigType" SG_ 2348875518 EngRqedSpeedCtrlConditions 4;
BA_ "SPN" SG_ 2348875518 EngRqedSpeedCtrlConditions 696;
BA_ "SigType" SG_ 2348875518 EngOverrideCtrlMode 4;
BA_ "SPN" SG_ 2348875518 EngOverrideCtrlMode 695;
BA_ "SPN" SG_ 2348875518 EngineRequestedTorqueHiRes 4191;
BA_ "SigType" SG_ 2566839552 EngTurboOilLevelSwitch 4;
BA_ "SPN" SG_ 2566839552 EngTurboOilLevelSwitch 1665;
BA_ "SigType" SG_ 2566839552 EngTurbo1Speed 1;
BA_ "SPN" SG_ 2566839552 EngTurbo1Speed 103;
BA_ "SigType" SG_ 2566839552 EngTurboLubeOilPress1 1;
BA_ "SPN" SG_ 2566839552 EngTurboLubeOilPress1 104;
BA_ "SigType" SG_ 2566839038 NmbrOfSftwrIdentificationFields 1;
BA_ "SPN" SG_ 2566839038 NmbrOfSftwrIdentificationFields 965;
BA_ "SigType" SG_ 2566839038 SoftwareID3 8;
BA_ "SPN" SG_ 2566839038 SoftwareID3 234;
BA_ "SigType" SG_ 2566839038 SoftwareID2 8;
BA_ "SPN" SG_ 2566839038 SoftwareID2 234;
BA_ "SigType" SG_ 2566839038 SoftwareID1 8;
BA_ "SPN" SG_ 2566839038 SoftwareID1 234;
BA_ "SigType" SG_ 2566841344 EngOverspeedTest 4;
BA_ "SPN" SG_ 2566841344 EngOverspeedTest 2812;
BA_ "SigType" SG_ 2566841344 EngAirShutoffCmdStatus 4;
BA_ "SPN" SG_ 2566841344 EngAirShutoffCmdStatus 2813;
BA_ "SigType" SG_ 2566841344 EngAlarmOutputCmdStatus 4;
BA_ "SPN" SG_ 2566841344 EngAlarmOutputCmdStatus 2814;
BA_ "SigType" SG_ 2566841344 EngAlarmAcknowledge 4;
BA_ "SPN" SG_ 2566841344 EngAlarmAcknowledge 2815;
BA_ "SigType" SG_ 2566841344 EngProtectionSystemConfig 4;
BA_ "SPN" SG_ 2566841344 EngProtectionSystemConfig 1111;
BA_ "SigType" SG_ 2566841344 EngProtectionSystemTimerState 4;
BA_ "SPN" SG_ 2566841344 EngProtectionSystemTimerState 1107;
BA_ "SigType" SG_ 2566841344 EngPrtectionSystemTimerOverride 4;
BA_ "SPN" SG_ 2566841344 EngPrtectionSystemTimerOverride 1108;
BA_ "SigType" SG_ 2566841344 EngPrtctnSystmApprchingShutdown 4;
BA_ "SPN" SG_ 2566841344 EngPrtctnSystmApprchingShutdown 1109;
BA_ "SigType" SG_ 2566841344 EngPrtctionSystemHasShutdownEng 4;
BA_ "SPN" SG_ 2566841344 EngPrtctionSystemHasShutdownEng 1110;
BA_ "SigType" SG_ 2566841344 EngWaitToStartLamp 4;
BA_ "SPN" SG_ 2566841344 EngWaitToStartLamp 1081;
BA_ "SigType" SG_ 2566841344 RefrigerantHighPressSwitch 4;
BA_ "SPN" SG_ 2566841344 RefrigerantHighPressSwitch 605;
BA_ "SigType" SG_ 2566841344 RefrigerantLowPressSwitch 4;
BA_ "SPN" SG_ 2566841344 RefrigerantLowPressSwitch 875;
BA_ "SigType" SG_ 2566841344 A_CHighPressFanSwitch 4;
BA_ "SPN" SG_ 2566841344 A_CHighPressFanSwitch 985;
BA_ "SigType" SG_ 2566841344 EngIdleShutdownTimerFunction 4;
BA_ "SPN" SG_ 2566841344 EngIdleShutdownTimerFunction 591;
BA_ "SigType" SG_ 2566841344 EngIdleShutdownTimerState 4;
BA_ "SPN" SG_ 2566841344 EngIdleShutdownTimerState 590;
BA_ "SigType" SG_ 2566841344 EngIdleShutdownTimerOverride 4;
BA_ "SPN" SG_ 2566841344 EngIdleShutdownTimerOverride 592;
BA_ "SigType" SG_ 2566841344 EngIdleShutdownDriverAlertMode 4;
BA_ "SPN" SG_ 2566841344 EngIdleShutdownDriverAlertMode 594;
BA_ "SigType" SG_ 2566841344 EngIdleShutdownHasShutdownEng 4;
BA_ "SPN" SG_ 2566841344 EngIdleShutdownHasShutdownEng 593;
BA_ "SigType" SG_ 2566844416 OperatorPTOMemorySelectSwitch 4;
BA_ "SPN" SG_ 2566844416 OperatorPTOMemorySelectSwitch 2897;
BA_ "SigType" SG_ 2566844416 EngPTOAccelerateSwitch 4;
BA_ "SPN" SG_ 2566844416 EngPTOAccelerateSwitch 981;
BA_ "SigType" SG_ 2566844416 EngPTOResumeSwitch 4;
BA_ "SPN" SG_ 2566844416 EngPTOResumeSwitch 982;
BA_ "SigType" SG_ 2566844416 EngPTOCoast_DecelerateSwitch 4;
BA_ "SPN" SG_ 2566844416 EngPTOCoast_DecelerateSwitch 983;
BA_ "SigType" SG_ 2566844416 EngPTOSetSwitch 4;
BA_ "SPN" SG_ 2566844416 EngPTOSetSwitch 984;
BA_ "SigType" SG_ 2566844416 EngRmtPTOVriableSpeedCtrlSwitch 4;
BA_ "SPN" SG_ 2566844416 EngRmtPTOVriableSpeedCtrlSwitch 978;
BA_ "SigType" SG_ 2566844416 EngRmtPTOPrprgrmmdSpdCtrlSwitch 4;
BA_ "SPN" SG_ 2566844416 EngRmtPTOPrprgrmmdSpdCtrlSwitch 979;
BA_ "SigType" SG_ 2566844416 EngPTOEnableSwitch 4;
BA_ "SPN" SG_ 2566844416 EngPTOEnableSwitch 980;
BA_ "SigType" SG_ 2566844416 PowerTakeoffSetSpeed 1;
BA_ "SPN" SG_ 2566844416 PowerTakeoffSetSpeed 187;
BA_ "SigType" SG_ 2566844416 PowerTakeoffSpeed 1;
BA_ "SPN" SG_ 2566844416 PowerTakeoffSpeed 186;
BA_ "SigType" SG_ 2566844416 PowerTakeoffOilTemp 1;
BA_ "SPN" SG_ 2566844416 PowerTakeoffOilTemp 90;
BA_ "SigType" SG_ 2566844416 RmtPTOPrprgrmmdSpeedCtrlSwitch2 4;
BA_ "SPN" SG_ 2566844416 RmtPTOPrprgrmmdSpeedCtrlSwitch2 3447;
BA_ "SigType" SG_ 2566844416 AuxInputIgnoreSwitch 4;
BA_ "SPN" SG_ 2566844416 AuxInputIgnoreSwitch 3448;
BA_ "SigType" SG_ 2566844928 EngAverageFuelEconomy 1;
BA_ "SPN" SG_ 2566844928 EngAverageFuelEconomy 185;
BA_ "SigType" SG_ 2566844928 EngInstantaneousFuelEconomy 1;
BA_ "SPN" SG_ 2566844928 EngInstantaneousFuelEconomy 184;
BA_ "SigType" SG_ 2566844928 EngFuelRate 1;
BA_ "SPN" SG_ 2566844928 EngFuelRate 183;
BA_ "SigType" SG_ 2566844928 EngThrottle2Pos 1;
BA_ "SPN" SG_ 2566844928 EngThrottle2Pos 3673;
BA_ "SigType" SG_ 2566844928 EngThrottlePos 1;
BA_ "SPN" SG_ 2566844928 EngThrottlePos 51;
BA_ "SigType" SG_ 2566842624 EngTotalFuelUsed 1;
BA_ "SPN" SG_ 2566842624 EngTotalFuelUsed 250;
BA_ "SigType" SG_ 2566842624 EngTripFuel 1;
BA_ "SPN" SG_ 2566842624 EngTripFuel 182;
BA_ "SigType" SG_ 2566831360 FanSpeed 1;
BA_ "SPN" SG_ 2566831360 FanSpeed 1639;
BA_ "SPN" SG_ 2566831360 FanDriveState 977;
BA_ "SigType" SG_ 2566831360 EstPercentFanSpeed 1;
BA_ "SPN" SG_ 2566831360 EstPercentFanSpeed 975;
BA_ "SigType" SG_ 2566824960 EngExhaustGasRecirculationTemp 1;
BA_ "SPN" SG_ 2566824960 EngExhaustGasRecirculationTemp 412;
BA_ "SigType" SG_ 2566824960 EngExhstGsRcirculationDiffPress 1;
BA_ "SPN" SG_ 2566824960 EngExhstGsRcirculationDiffPress 411;
BA_ "SigType" SG_ 2566824960 EngECUTemp 1;
BA_ "SPN" SG_ 2566824960 EngECUTemp 1136;
BA_ "SigType" SG_ 2566824960 EngOilTemp2 1;
BA_ "SPN" SG_ 2566824960 EngOilTemp2 1135;
BA_ "SigType" SG_ 2566843904 EngIntercoolerThermostatOpening 1;
BA_ "SPN" SG_ 2566843904 EngIntercoolerThermostatOpening 1134;
BA_ "SigType" SG_ 2566843904 EngIntercoolerTemp 1;
BA_ "SPN" SG_ 2566843904 EngIntercoolerTemp 52;
BA_ "SigType" SG_ 2566843904 EngTurboOilTemp 1;
BA_ "SPN" SG_ 2566843904 EngTurboOilTemp 176;
BA_ "SigType" SG_ 2566843904 EngOilTemp1 1;
BA_ "SPN" SG_ 2566843904 EngOilTemp1 175;
BA_ "SigType" SG_ 2566843904 EngFuelTemp 1;
BA_ "SPN" SG_ 2566843904 EngFuelTemp 174;
BA_ "SigType" SG_ 2566843904 EngCoolantTemp 1;
BA_ "SPN" SG_ 2566843904 EngCoolantTemp 110;
BA_ "SigType" SG_ 2566844160 EngCoolantLevel 1;
BA_ "SPN" SG_ 2566844160 EngCoolantLevel 111;
BA_ "SigType" SG_ 2566844160 EngCoolantPress 1;
BA_ "SPN" SG_ 2566844160 EngCoolantPress 109;
BA_ "SigType" SG_ 2566844160 EngCrankcasePress 1;
BA_ "SPN" SG_ 2566844160 EngCrankcasePress 101;
BA_ "SigType" SG_ 2566844160 EngOilPress 1;
BA_ "SPN" SG_ 2566844160 EngOilPress 100;
BA_ "SigType" SG_ 2566844160 EngOilLevel 1;
BA_ "SPN" SG_ 2566844160 EngOilLevel 98;
BA_ "SigType" SG_ 2566844160 EngExCrankcaseBlowbyPress 1;
BA_ "SPN" SG_ 2566844160 EngExCrankcaseBlowbyPress 22;
BA_ "SigType" SG_ 2566844160 EngFuelDeliveryPress 1;
BA_ "SPN" SG_ 2566844160 EngFuelDeliveryPress 94;
BA_ "SigType" SG_ 2566840064 ExhaustGasMass 1;
BA_ "SPN" SG_ 2566840064 ExhaustGasMass 3236;
BA_ "SigType" SG_ 2566840064 AftrTrtmntIntakeDewPointMessage 4;
BA_ "SPN" SG_ 2566840064 AftrTrtmntIntakeDewPointMessage 3237;
BA_ "SigType" SG_ 2566840064 AftrTrtmntExhustDewPointMessage 4;
BA_ "SPN" SG_ 2566840064 AftrTrtmntExhustDewPointMessage 3238;
BA_ "SigType" SG_ 2566840064 EstEngPrsticLossesPercentTorque 1;
BA_ "SPN" SG_ 2566840064 EstEngPrsticLossesPercentTorque 2978;
BA_ "SigType" SG_ 2566840064 EngsDsrdOprtngSpdAsymmtryAdjstmn 1;
BA_ "SPN" SG_ 2566840064 EngsDsrdOprtngSpdAsymmtryAdjstmn 519;
BA_ "SigType" SG_ 2566840064 EngsDesiredOperatingSpeed 1;
BA_ "SPN" SG_ 2566840064 EngsDesiredOperatingSpeed 515;
BA_ "SigType" SG_ 2566840064 NominalFrictionPercentTorque 1;
BA_ "SPN" SG_ 2566840064 NominalFrictionPercentTorque 514;
BA_ "SigType" SG_ 2364539648 ActMaxAvailEngPercentTorque 1;
BA_ "SPN" SG_ 2364539648 ActMaxAvailEngPercentTorque 3357;
BA_ "SigType" SG_ 2364539648 AccelPedalPos2 1;
BA_ "SPN" SG_ 2364539648 AccelPedalPos2 29;
BA_ "SigType" SG_ 2364539648 VhclAccelerationRateLimitStatus 4;
BA_ "SPN" SG_ 2364539648 VhclAccelerationRateLimitStatus 2979;
BA_ "SigType" SG_ 2364539648 EngPercentLoadAtCurrentSpeed 1;
BA_ "SPN" SG_ 2364539648 EngPercentLoadAtCurrentSpeed 92;
BA_ "SigType" SG_ 2364539648 AccelPedal2LowIdleSwitch 4;
BA_ "SPN" SG_ 2364539648 AccelPedal2LowIdleSwitch 2970;
BA_ "SigType" SG_ 2364539648 RoadSpeedLimitStatus 4;
BA_ "SPN" SG_ 2364539648 RoadSpeedLimitStatus 1437;
BA_ "SigType" SG_ 2364539648 AccelPedalKickdownSwitch 4;
BA_ "SPN" SG_ 2364539648 AccelPedalKickdownSwitch 559;
BA_ "SigType" SG_ 2364539648 AccelPedal1LowIdleSwitch 4;
BA_ "SPN" SG_ 2364539648 AccelPedal1LowIdleSwitch 558;
BA_ "SigType" SG_ 2364539648 RemoteAccelPedalPos 1;
BA_ "SPN" SG_ 2364539648 RemoteAccelPedalPos 974;
BA_ "SigType" SG_ 2364539648 AccelPedalPos1 1;
BA_ "SPN" SG_ 2364539648 AccelPedalPos1 91;
BA_ "SigType" SG_ 2364539904 EngDemandPercentTorque 1;
BA_ "SPN" SG_ 2364539904 EngDemandPercentTorque 2432;
BA_ "SPN" SG_ 2364539904 EngStarterMode 1675;
BA_ "SigType" SG_ 2364539904 SrcAddrssOfCtrllngDvcForEngCtrl 1;
BA_ "SPN" SG_ 2364539904 SrcAddrssOfCtrllngDvcForEngCtrl 1483;
BA_ "SigType" SG_ 2364539904 EngSpeed 1;
BA_ "SPN" SG_ 2364539904 EngSpeed 190;
BA_ "SigType" SG_ 2364539904 ActualEngPercentTorque 1;
BA_ "SPN" SG_ 2364539904 ActualEngPercentTorque 513;
BA_ "SigType" SG_ 2364539904 DriversDemandEngPercentTorque 1;
BA_ "SPN" SG_ 2364539904 DriversDemandEngPercentTorque 512;
BA_ "SPN" SG_ 2364539904 EngTorqueMode 899;
BA_ "SPN" SG_ 2364539904 ActualEnginePercentTorqueHiRes 4154;
BA_ "SigType" SG_ 2566768126 ECUType 8;
BA_ "SPN" SG_ 2566768126 ECUType 2904;
BA_ "SigType" SG_ 2566768126 ECULocation 8;
BA_ "SPN" SG_ 2566768126 ECULocation 2903;
BA_ "SigType" SG_ 2566768126 ECUSerialNumber 8;
BA_ "SPN" SG_ 2566768126 ECUSerialNumber 2902;
BA_ "SigType" SG_ 2566768126 ECUPartNumber 8;
BA_ "SPN" SG_ 2566768126 ECUPartNumber 2901;
BA_ "SigType" SG_ 2566841088 SupportTSC1CtrlPurposeGroup4Of4 1;
BA_ "SPN" SG_ 2566841088 SupportTSC1CtrlPurposeGroup4Of4 3348;
BA_ "SigType" SG_ 2566841088 SupportVariableRateTSC1Message 1;
BA_ "SPN" SG_ 2566841088 SupportVariableRateTSC1Message 3344;
BA_ "SigType" SG_ 2566841088 SupportTSC1CtrlPurposeGroup3Of4 1;
BA_ "SPN" SG_ 2566841088 SupportTSC1CtrlPurposeGroup3Of4 3347;
BA_ "SigType" SG_ 2566841088 SupportTSC1CtrlPurposeGroup2Of4 1;
BA_ "SPN" SG_ 2566841088 SupportTSC1CtrlPurposeGroup2Of4 3346;
BA_ "SigType" SG_ 2566841088 SupportTSC1CtrlPurposeGroup1Of4 1;
BA_ "SPN" SG_ 2566841088 SupportTSC1CtrlPurposeGroup1Of4 3345;
BA_ "SigType" SG_ 2566841088 EngDefaultTorqueLimit 1;
BA_ "SPN" SG_ 2566841088 EngDefaultTorqueLimit 1846;
BA_ "SigType" SG_ 2566841088 EngMomentOfInertia 1;
BA_ "SPN" SG_ 2566841088 EngMomentOfInertia 1794;
BA_ "SigType" SG_ 2566841088 EngExRngRqdSpdCtrlRngUpperLimit 1;
BA_ "SPN" SG_ 2566841088 EngExRngRqdSpdCtrlRngUpperLimit 1712;
BA_ "SigType" SG_ 2566841088 EngRqdTorqueCtrlRangeUpperLimit 1;
BA_ "SPN" SG_ 2566841088 EngRqdTorqueCtrlRangeUpperLimit 538;
BA_ "SigType" SG_ 2566841088 EngRqdTorqueCtrlRangeLowerLimit 1;
BA_ "SPN" SG_ 2566841088 EngRqdTorqueCtrlRangeLowerLimit 537;
BA_ "SigType" SG_ 2566841088 EngRqedSpeedCtrlRangeUpperLimit 1;
BA_ "SPN" SG_ 2566841088 EngRqedSpeedCtrlRangeUpperLimit 536;
BA_ "SigType" SG_ 2566841088 EngRqedSpeedCtrlRangeLowerLimit 1;
BA_ "SPN" SG_ 2566841088 EngRqedSpeedCtrlRangeLowerLimit 535;
BA_ "SigType" SG_ 2566841088 EngMxMomentaryOverrideTimeLimit 1;
BA_ "SPN" SG_ 2566841088 EngMxMomentaryOverrideTimeLimit 534;
BA_ "SigType" SG_ 2566841088 EngMxMmntaryOverrideSpeedPoint7 1;
BA_ "SPN" SG_ 2566841088 EngMxMmntaryOverrideSpeedPoint7 533;
BA_ "SigType" SG_ 2566841088 EngReferenceTorque 1;
BA_ "SPN" SG_ 2566841088 EngReferenceTorque 544;
BA_ "SigType" SG_ 2566841088 EngSpeedAtHighIdlePoint6 1;
BA_ "SPN" SG_ 2566841088 EngSpeedAtHighIdlePoint6 532;
BA_ "SigType" SG_ 2566841088 EngGainOfEndspeedGovernor 1;
BA_ "SPN" SG_ 2566841088 EngGainOfEndspeedGovernor 545;
BA_ "SigType" SG_ 2566841088 EngPercentTorqueAtPoint5 1;
BA_ "SPN" SG_ 2566841088 EngPercentTorqueAtPoint5 543;
BA_ "SigType" SG_ 2566841088 EngSpeedAtPoint5 1;
BA_ "SPN" SG_ 2566841088 EngSpeedAtPoint5 531;
BA_ "SigType" SG_ 2566841088 EngPercentTorqueAtPoint4 1;
BA_ "SPN" SG_ 2566841088 EngPercentTorqueAtPoint4 542;
BA_ "SigType" SG_ 2566841088 EngSpeedAtPoint4 1;
BA_ "SPN" SG_ 2566841088 EngSpeedAtPoint4 530;
BA_ "SigType" SG_ 2566841088 EngPercentTorqueAtPoint3 1;
BA_ "SPN" SG_ 2566841088 EngPercentTorqueAtPoint3 541;
BA_ "SigType" SG_ 2566841088 EngSpeedAtPoint3 1;
BA_ "SPN" SG_ 2566841088 EngSpeedAtPoint3 529;
BA_ "SigType" SG_ 2566841088 EngPercentTorqueAtPoint2 1;
BA_ "SPN" SG_ 2566841088 EngPercentTorqueAtPoint2 540;
BA_ "SigType" SG_ 2566841088 EngSpeedAtPoint2 1;
BA_ "SPN" SG_ 2566841088 EngSpeedAtPoint2 528;
BA_ "SigType" SG_ 2566841088 EngPercentTorqueAtIdlePoint1 1;
BA_ "SPN" SG_ 2566841088 EngPercentTorqueAtIdlePoint1 539;
BA_ "SigType" SG_ 2566841088 EngSpeedAtIdlePoint1 1;
BA_ "SPN" SG_ 2566841088 EngSpeedAtIdlePoint1 188;
BA_ "SigType" SG_ 2566767627 BrakeTempWarning 4;
BA_ "SPN" SG_ 2566767627 BrakeTempWarning 3839;
BA_ "SigType" SG_ 2566767627 XBRAccelerationLimit 1;
BA_ "SPN" SG_ 2566767627 XBRAccelerationLimit 2921;
BA_ "SPN" SG_ 2566767627 XBRActiveCtrlMode 2918;
BA_ "SigType" SG_ 2566767627 XBRSystemState 4;
BA_ "SPN" SG_ 2566767627 XBRSystemState 2917;
BA_ "SigType" SG_ 2566767627 FoundationBrakeUse 4;
BA_ "SPN" SG_ 2566767627 FoundationBrakeUse 2919;
BA_ "SPN" SG_ 2566767627 HillHolderMode 2912;
BA_ "SPN" SG_ 2566767627 HaltBrakeMode 2913;
BA_ "SigType" SG_ 2633935883 BrkLnngRmnngRearAxle3RightWheel 1;
BA_ "SPN" SG_ 2633935883 BrkLnngRmnngRearAxle3RightWheel 1106;
BA_ "SigType" SG_ 2633935883 BrkLnngRmningRearAxle3LeftWheel 1;
BA_ "SPN" SG_ 2633935883 BrkLnngRmningRearAxle3LeftWheel 1105;
BA_ "SigType" SG_ 2633935883 BrkLnngRmnngRearAxle2RightWheel 1;
BA_ "SPN" SG_ 2633935883 BrkLnngRmnngRearAxle2RightWheel 1104;
BA_ "SigType" SG_ 2633935883 BrkLnngRmningRearAxle2LeftWheel 1;
BA_ "SPN" SG_ 2633935883 BrkLnngRmningRearAxle2LeftWheel 1103;
BA_ "SigType" SG_ 2633935883 BrkLnngRmnngRearAxle1RightWheel 1;
BA_ "SPN" SG_ 2633935883 BrkLnngRmnngRearAxle1RightWheel 1102;
BA_ "SigType" SG_ 2633935883 BrkLnngRmningRearAxle1LeftWheel 1;
BA_ "SPN" SG_ 2633935883 BrkLnngRmningRearAxle1LeftWheel 1101;
BA_ "SigType" SG_ 2633935883 BrkLnngRmnngFrontAxleRightWheel 1;
BA_ "SPN" SG_ 2633935883 BrkLnngRmnngFrontAxleRightWheel 1100;
BA_ "SigType" SG_ 2633935883 BrkLnngRmningFrontAxleLeftWheel 1;
BA_ "SPN" SG_ 2633935883 BrkLnngRmningFrontAxleLeftWheel 1099;
BA_ "SigType" SG_ 2566827275 BrkAppPrssHghRngRrAxl3RghtWheel 1;
BA_ "SPN" SG_ 2566827275 BrkAppPrssHghRngRrAxl3RghtWheel 1098;
BA_ "SigType" SG_ 2566827275 BrkAppPrssHghRngRrAxl3LeftWheel 1;
BA_ "SPN" SG_ 2566827275 BrkAppPrssHghRngRrAxl3LeftWheel 1097;
BA_ "SigType" SG_ 2566827275 BrkAppPrssHghRngRrAxl2RghtWheel 1;
BA_ "SPN" SG_ 2566827275 BrkAppPrssHghRngRrAxl2RghtWheel 1096;
BA_ "SigType" SG_ 2566827275 BrkAppPrssHghRngRrAxl2LeftWheel 1;
BA_ "SPN" SG_ 2566827275 BrkAppPrssHghRngRrAxl2LeftWheel 1095;
BA_ "SigType" SG_ 2566827275 BrkAppPrssHghRngRrAxl1RghtWheel 1;
BA_ "SPN" SG_ 2566827275 BrkAppPrssHghRngRrAxl1RghtWheel 1094;
BA_ "SigType" SG_ 2566827275 BrkAppPrssHghRngRrAxl1LeftWheel 1;
BA_ "SPN" SG_ 2566827275 BrkAppPrssHghRngRrAxl1LeftWheel 1093;
BA_ "SigType" SG_ 2566827275 BrkAppPrssHghRngFrntAxlRghtWhel 1;
BA_ "SPN" SG_ 2566827275 BrkAppPrssHghRngFrntAxlRghtWhel 1092;
BA_ "SigType" SG_ 2566827275 BrkAppPrssHghRngFrntAxlLftWheel 1;
BA_ "SPN" SG_ 2566827275 BrkAppPrssHghRngFrntAxlLftWheel 1091;
BA_ "SigType" SG_ 2566831883 RlativeSpeedRearAxle2RightWheel 1;
BA_ "SPN" SG_ 2566831883 RlativeSpeedRearAxle2RightWheel 910;
BA_ "SigType" SG_ 2566831883 RelativeSpeedRearAxle2LeftWheel 1;
BA_ "SPN" SG_ 2566831883 RelativeSpeedRearAxle2LeftWheel 909;
BA_ "SigType" SG_ 2566831883 RlativeSpeedRearAxle1RightWheel 1;
BA_ "SPN" SG_ 2566831883 RlativeSpeedRearAxle1RightWheel 908;
BA_ "SigType" SG_ 2566831883 RelativeSpeedRearAxle1LeftWheel 1;
BA_ "SPN" SG_ 2566831883 RelativeSpeedRearAxle1LeftWheel 907;
BA_ "SigType" SG_ 2566831883 RlativeSpeedFrontAxleRightWheel 1;
BA_ "SPN" SG_ 2566831883 RlativeSpeedFrontAxleRightWheel 906;
BA_ "SigType" SG_ 2566831883 RelativeSpeedFrontAxleLeftWheel 1;
BA_ "SPN" SG_ 2566831883 RelativeSpeedFrontAxleLeftWheel 905;
BA_ "SigType" SG_ 2566831883 FrontAxleSpeed 1;
BA_ "SPN" SG_ 2566831883 FrontAxleSpeed 904;
BA_ "SigType" SG_ 2565865739 SrcAddrssOfCtrllngDvcFrBrkCntrl 1;
BA_ "SPN" SG_ 2565865739 SrcAddrssOfCtrllngDvcFrBrkCntrl 1481;
BA_ "SigType" SG_ 2565865739 BrakePedalPos 1;
BA_ "SPN" SG_ 2565865739 BrakePedalPos 521;
BA_ "SigType" SG_ 2565865739 TrctrMntdTrilerABSWarningSignal 4;
BA_ "SPN" SG_ 2565865739 TrctrMntdTrilerABSWarningSignal 1792;
BA_ "SigType" SG_ 2565865739 TrailerABSStatus 4;
BA_ "SPN" SG_ 2565865739 TrailerABSStatus 1836;
BA_ "SigType" SG_ 2565865739 HaltBrakeSwitch 4;
BA_ "SPN" SG_ 2565865739 HaltBrakeSwitch 2911;
BA_ "SigType" SG_ 2565865739 ATC_ASRInformationSignal 4;
BA_ "SPN" SG_ 2565865739 ATC_ASRInformationSignal 1793;
BA_ "SigType" SG_ 2565865739 ABS_EBSAmberWarningSignal 4;
BA_ "SPN" SG_ 2565865739 ABS_EBSAmberWarningSignal 1438;
BA_ "SigType" SG_ 2565865739 EBSRedWarningSignal 4;
BA_ "SPN" SG_ 2565865739 EBSRedWarningSignal 1439;
BA_ "SigType" SG_ 2565865739 ABSFullyOperational 4;
BA_ "SPN" SG_ 2565865739 ABSFullyOperational 1243;
BA_ "SigType" SG_ 2565865739 EngRetarderSelection 1;
BA_ "SPN" SG_ 2565865739 EngRetarderSelection 973;
BA_ "SigType" SG_ 2565865739 RemoteAccelEnableSwitch 4;
BA_ "SPN" SG_ 2565865739 RemoteAccelEnableSwitch 969;
BA_ "SigType" SG_ 2565865739 EngAuxEngShutdownSwitch 4;
BA_ "SPN" SG_ 2565865739 EngAuxEngShutdownSwitch 970;
BA_ "SigType" SG_ 2565865739 EngDerateSwitch 4;
BA_ "SPN" SG_ 2565865739 EngDerateSwitch 971;
BA_ "SigType" SG_ 2565865739 AccelInterlockSwitch 4;
BA_ "SPN" SG_ 2565865739 AccelInterlockSwitch 972;
BA_ "SigType" SG_ 2565865739 TractionCtrlOverrideSwitch 4;
BA_ "SPN" SG_ 2565865739 TractionCtrlOverrideSwitch 1238;
BA_ "SigType" SG_ 2565865739 ASRHillHolderSwitch 4;
BA_ "SPN" SG_ 2565865739 ASRHillHolderSwitch 577;
BA_ "SigType" SG_ 2565865739 ASROffroadSwitch 4;
BA_ "SPN" SG_ 2565865739 ASROffroadSwitch 576;
BA_ "SigType" SG_ 2565865739 ABSOffroadSwitch 4;
BA_ "SPN" SG_ 2565865739 ABSOffroadSwitch 575;
BA_ "SigType" SG_ 2565865739 EBSBrakeSwitch 4;
BA_ "SPN" SG_ 2565865739 EBSBrakeSwitch 1121;
BA_ "SigType" SG_ 2565865739 AntiLockBrakingActive 4;
BA_ "SPN" SG_ 2565865739 AntiLockBrakingActive 563;
BA_ "SigType" SG_ 2565865739 ASRBrakeCtrlActive 4;
BA_ "SPN" SG_ 2565865739 ASRBrakeCtrlActive 562;
BA_ "SigType" SG_ 2565865739 ASREngCtrlActive 4;
BA_ "SPN" SG_ 2565865739 ASREngCtrlActive 561;
BA_ "SigType" SG_ 2566844672 ParkBrakeReleaseInhibitRq 4;
BA_ "SPN" SG_ 2566844672 ParkBrakeReleaseInhibitRq 3807;
BA_ "SigType" SG_ 2566844672 EngShutdownOverrideSwitch 4;
BA_ "SPN" SG_ 2566844672 EngShutdownOverrideSwitch 1237;
BA_ "SigType" SG_ 2566844672 EngTestModeSwitch 4;
BA_ "SPN" SG_ 2566844672 EngTestModeSwitch 966;
BA_ "SigType" SG_ 2566844672 EngIdleDecrementSwitch 4;
BA_ "SPN" SG_ 2566844672 EngIdleDecrementSwitch 967;
BA_ "SigType" SG_ 2566844672 EngIdleIncrementSwitch 4;
BA_ "SPN" SG_ 2566844672 EngIdleIncrementSwitch 968;
BA_ "SPN" SG_ 2566844672 CruiseCtrlStates 527;
BA_ "SPN" SG_ 2566844672 PTOState 976;
BA_ "SigType" SG_ 2566844672 CruiseCtrlSetSpeed 1;
BA_ "SPN" SG_ 2566844672 CruiseCtrlSetSpeed 86;
BA_ "SigType" SG_ 2566844672 CruiseCtrlAccelerateSwitch 4;
BA_ "SPN" SG_ 2566844672 CruiseCtrlAccelerateSwitch 602;
BA_ "SigType" SG_ 2566844672 CruiseCtrlResumeSwitch 4;
BA_ "SPN" SG_ 2566844672 CruiseCtrlResumeSwitch 601;
BA_ "SigType" SG_ 2566844672 CruiseCtrlCoastSwitch 4;
BA_ "SPN" SG_ 2566844672 CruiseCtrlCoastSwitch 600;
BA_ "SigType" SG_ 2566844672 CruiseCtrlSetSwitch 4;
BA_ "SPN" SG_ 2566844672 CruiseCtrlSetSwitch 599;
BA_ "SigType" SG_ 2566844672 ClutchSwitch 4;
BA_ "SPN" SG_ 2566844672 ClutchSwitch 598;
BA_ "SigType" SG_ 2566844672 BrakeSwitch 4;
BA_ "SPN" SG_ 2566844672 BrakeSwitch 597;
BA_ "SigType" SG_ 2566844672 CruiseCtrlEnableSwitch 4;
BA_ "SPN" SG_ 2566844672 CruiseCtrlEnableSwitch 596;
BA_ "SigType" SG_ 2566844672 CruiseCtrlActive 4;
BA_ "SPN" SG_ 2566844672 CruiseCtrlActive 595;
BA_ "SigType" SG_ 2566844672 WheelBasedVehicleSpeed 1;
BA_ "SPN" SG_ 2566844672 WheelBasedVehicleSpeed 84;
BA_ "SigType" SG_ 2566844672 CruiseCtrlPauseSwitch 4;
BA_ "SPN" SG_ 2566844672 CruiseCtrlPauseSwitch 1633;
BA_ "SigType" SG_ 2566844672 ParkingBrakeSwitch 4;
BA_ "SPN" SG_ 2566844672 ParkingBrakeSwitch 70;
BA_ "SigType" SG_ 2566844672 TwoSpeedAxleSwitch 4;
BA_ "SPN" SG_ 2566844672 TwoSpeedAxleSwitch 69;
BA_ "SigType" SG_ 2565799678 ManufacturerCode 1;
BA_ "SigType" SG_ 2563440382 ShrtNameOfActualReportingDevice 4;
BA_ "SPN" SG_ 2563440382 ShrtNameOfActualReportingDevice 2554;
BA_ "SigType" SG_ 2563440382 LengthOfDataForTheReportedPGN 1;
BA_ "SPN" SG_ 2563440382 LengthOfDataForTheReportedPGN 2553;
BA_ "SigType" SG_ 2563440382 PGNofRequstedInformation 6;
BA_ "SPN" SG_ 2563440382 PGNofRequstedInformation 2552;
BA_ "SigType" SG_ 2565603070 SequenceNumber 1;
BA_ "SPN" SG_ 2565603070 SequenceNumber 2572;
BA_ "SigType" SG_ 2565668606 TotalNumberOfPacketsEoMA 1;
BA_ "SPN" SG_ 2565668606 TotalNumberOfPacketsEoMA 2558;
BA_ "SigType" SG_ 2565668606 TotalMessageSizeEoMA 1;
BA_ "SPN" SG_ 2565668606 TotalMessageSizeEoMA 2557;
BA_ "SigType" SG_ 2565668606 TotalMessageSizeBAM 1;
BA_ "SPN" SG_ 2565668606 TotalMessageSizeBAM 2557;
BA_ "SigType" SG_ 2565668606 TotalNumberOfPacketsBAM 1;
BA_ "SPN" SG_ 2565668606 TotalNumberOfPacketsBAM 2558;
BA_ "SigType" SG_ 2565668606 ConnectionAbortReason 1;
BA_ "SPN" SG_ 2565668606 ConnectionAbortReason 2570;
BA_ "SigType" SG_ 2565668606 NextPacketNumberToBeSent 1;
BA_ "SPN" SG_ 2565668606 NextPacketNumberToBeSent 2562;
BA_ "SigType" SG_ 2565668606 NumberOfPacketsThatCanBeSent 1;
BA_ "SPN" SG_ 2565668606 NumberOfPacketsThatCanBeSent 2561;
BA_ "SigType" SG_ 2565668606 PGNumber 6;
BA_ "SPN" SG_ 2565668606 PGNumber 2560;
BA_ "SigType" SG_ 2565668606 MaximumNumberOfPackets 1;
BA_ "SPN" SG_ 2565668606 MaximumNumberOfPackets 2559;
BA_ "SigType" SG_ 2565668606 TotalNumberOfPackets 1;
BA_ "SPN" SG_ 2565668606 TotalNumberOfPackets 2558;
BA_ "SigType" SG_ 2565668606 TotalMessageSize 1;
BA_ "SPN" SG_ 2565668606 TotalMessageSize 2557;
BA_ "SPN" SG_ 2565668606 ControlByte 2556;
BA_ "SigType" SG_ 2563374846 UseTransferMode 4;
BA_ "SPN" SG_ 2563374846 UseTransferMode 2575;
BA_ "SigType" SG_ 2563374846 ParameterGroupNumber 6;
BA_ "SPN" SG_ 2563374846 ParameterGroupNumber 2574;
BA_ "SigType" SG_ 2565537534 ParameterGroupNumber 6;
BA_ "SPN" SG_ 2565537534 ParameterGroupNumber 2574;
BA_ "SPN" SG_ 2565406462 ControlByte 2541;
BA_ "SigType" SG_ 2565406462 ParameterGroupNumber 6;
BA_ "SPN" SG_ 2565406462 ParameterGroupNumber 2574;
BA_ "SigType" SG_ 2565406462 GroupFunctionValue 1;
BA_ "SPN" SG_ 2565406462 GroupFunctionValue 2542;
VAL_ 2566836222 FMI5 24 "Assurance Data Error" 23 "Request DM60 for more info" 22 "Special Instructions #2 " 21 "Data drifted low" 20 "Data drifted high" 31 "Condition exists" 19 "Received network data in error" 18 "Below normal (moderately severe)" 17 "Below normal (least severe)" 16 "Above normal (moderately severe)" 15 "Above normal (least severe)" 14 "Special intstructions" 13 "Out of calibration" 12 "Bad intelligent device" 11 "Root cause not known" 10 "Abnormal rate of change" 9 "Abnormal update rate" 8 "Abnormal frequency" 7 "Mechanical system not responding" 6 "Current above normal" 5 "Current below normal" 4 "Voltage below normal" 3 "Voltage above normal" 2 "Data erratic" 1 "Below normal (most severe)" 0 "Above normal (most severe)" ;
VAL_ 2566836222 FMI4 24 "Assurance Data Error" 23 "Request DM60 for more info" 22 "Special Instructions #2 " 21 "Data drifted low" 20 "Data drifted high" 31 "Condition exists" 19 "Received network data in error" 18 "Below normal (moderately severe)" 17 "Below normal (least severe)" 16 "Above normal (moderately severe)" 15 "Above normal (least severe)" 14 "Special intstructions" 13 "Out of calibration" 12 "Bad intelligent device" 11 "Root cause not known" 10 "Abnormal rate of change" 9 "Abnormal update rate" 8 "Abnormal frequency" 7 "Mechanical system not responding" 6 "Current above normal" 5 "Current below normal" 4 "Voltage below normal" 3 "Voltage above normal" 2 "Data erratic" 1 "Below normal (most severe)" 0 "Above normal (most severe)" ;
VAL_ 2566836222 FMI3 24 "Assurance Data Error" 23 "Request DM60 for more info" 22 "Special Instructions #2 " 21 "Data drifted low" 20 "Data drifted high" 31 "Condition exists" 19 "Received network data in error" 18 "Below normal (moderately severe)" 17 "Below normal (least severe)" 16 "Above normal (moderately severe)" 15 "Above normal (least severe)" 14 "Special intstructions" 13 "Out of calibration" 12 "Bad intelligent device" 11 "Root cause not known" 10 "Abnormal rate of change" 9 "Abnormal update rate" 8 "Abnormal frequency" 7 "Mechanical system not responding" 6 "Current above normal" 5 "Current below normal" 4 "Voltage below normal" 3 "Voltage above normal" 2 "Data erratic" 1 "Below normal (most severe)" 0 "Above normal (most severe)" ;
VAL_ 2566836222 FMI2 24 "Assurance Data Error" 23 "Request DM60 for more info" 22 "Special Instructions #2 " 21 "Data drifted low" 20 "Data drifted high" 31 "Condition exists" 19 "Received network data in error" 18 "Below normal (moderately severe)" 17 "Below normal (least severe)" 16 "Above normal (moderately severe)" 15 "Above normal (least severe)" 14 "Special intstructions" 13 "Out of calibration" 12 "Bad intelligent device" 11 "Root cause not known" 10 "Abnormal rate of change" 9 "Abnormal update rate" 8 "Abnormal frequency" 7 "Mechanical system not responding" 6 "Current above normal" 5 "Current below normal" 4 "Voltage below normal" 3 "Voltage above normal" 2 "Data erratic" 1 "Below normal (most severe)" 0 "Above normal (most severe)" ;
VAL_ 2566836222 FMI1 24 "Assurance Data Error" 23 "Request DM60 for more info" 22 "Special Instructions #2 " 21 "Data drifted low" 20 "Data drifted high" 31 "Condition exists" 19 "Received network data in error" 18 "Below normal (moderately severe)" 17 "Below normal (least severe)" 16 "Above normal (moderately severe)" 15 "Above normal (least severe)" 14 "Special intstructions" 13 "Out of calibration" 12 "Bad intelligent device" 11 "Root cause not known" 10 "Abnormal rate of change" 9 "Abnormal update rate" 8 "Abnormal frequency" 7 "Mechanical system not responding" 6 "Current above normal" 5 "Current below normal" 4 "Voltage below normal" 3 "Voltage above normal" 2 "Data erratic" 1 "Below normal (most severe)" 0 "Above normal (most severe)" ;
VAL_ 2566836222 FlashRedStopLamp 3 "Unavailable / Do Not Flash" 2 "Reserved" 1 "Fast Flash" 0 "Slow Flash" ;
VAL_ 2566836222 FlashProtectLamp 3 "Unavailable / Do Not Flash" 2 "Reserved" 1 "Fast Flash" 0 "Slow Flash" ;
VAL_ 2566836222 FlashMalfuncIndicatorLamp 3 "Unavailable / Do Not Flash" 2 "Class C DTC  " 1 "Fast Flash" 0 "Slow Flash" ;
VAL_ 2566836222 FlashAmberWarningLamp 3 "Unavailable / Do Not Flash" 2 "Reserved" 1 "Fast Flash" 0 "Slow Flash" ;
VAL_ 2566836222 MalfunctionIndLampStatus 3 "Not available" 2 "Short MIL for WWH OBD" 1 "Lamp On" 0 "Lamp Off" ;
VAL_ 2566836222 AmberWarningLampStatus 3 "Not available" 2 "Reserved" 1 "Lamp On" 0 "Lamp Off" ;
VAL_ 2566836222 RedStopLampState 3 "Not available" 2 "Reserved" 1 "Lamp On" 0 "Lamp Off" ;
VAL_ 2566836222 ProtectLampStatus 0 "Lamp Off" 3 "Not available" 2 "Reserved" 1 "Lamp On" ;
VAL_ 2566835966 MisfireMonitoringSupport 3 "Not available" 2 "Reserved" 1 "test supported" 0 "test not supported" ;
VAL_ 2566835966 OBDCompliance 10 "JOBD" 11 "JOBD and OBD II" 12 "JOBD and EOBD" 13 "JOBD, EOBD and OBD II" 14 "Heavy Duty Vehicles (EURO IV) B1" 15 "Heavy Duty Vehicles (EURO V) B2" 16 "Heavy Duty Vehicles (EURO EEC) C" 17 "EMD" 18 "EMD+" 19 "HD OBD P" 20 "HD OBD" 21 "WWH OBD" 22 "OBD II (California, ARB 07/08)" 23 "HD EOBD" 25 "OBD-M (SI-SD/I)" 6 "EOBD" 7 "EOBD and OBD II" 8 "EOBD and OBD" 9 "EOBD, OBD and OBD II" 5 "Not intended to meet OBD II req." 4 "OBD I" 3 "OBD and OBD II" 2 "OBD (Federal, EPA)" 1 "OBD II (California, ARB)" 0 "Reserver for assignment by SAE" ;
VAL_ 2566835966 SecondAirSystemMonStatus 1 "TestNotComplete" 0 "TestComplete" ;
VAL_ 2566835966 EvaporativeSystemMonStatus 1 "TestNotComplete" 0 "TestComplete" ;
VAL_ 2566835966 ACSystemRefrigerantMonStatus 1 "TestNotComplete" 0 "TestComplete" ;
VAL_ 2566835966 OxygenSensorHeaterMonStatus 1 "TestNotComplete" 0 "TestComplete" ;
VAL_ 2566835966 OxygenSensorMonStatus 1 "test not complete" 0 "test complete" ;
VAL_ 2566835966 EGRSystemMonitoringStatus 1 "TestNotComplete" 0 "TestComplete" ;
VAL_ 2566835966 CatalystMonStatus 0 "TestComplete" 1 "TestNotComplete" ;
VAL_ 2566835966 ColdStartAidSystemMonStatus 1 "TestNotComplete" 0 "TestComplete" ;
VAL_ 2566835966 HeatedCatalystMonStatus 1 "TestNotComplete" 0 "TestComplete" ;
VAL_ 2566835966 CatalystMonSupp 1 "TestSupported" 0 "TestNotSupported" ;
VAL_ 2566835966 ColdStartAidSystemMonSupp 1 "TestSupported" 0 "TestNotSupported" ;
VAL_ 2566835966 HeatedCatalystMonSupp 1 "TestSupported" 0 "TestNotSupported" ;
VAL_ 2566835966 EvaporativeSystemMonSupp 1 "TestSupported" 0 "TestNotSupported" ;
VAL_ 2566835966 SecondAirSystemMonSupp 1 "TestSupported" 0 "TestNotSupported" ;
VAL_ 2566835966 ACSystemRefrigerantMonSupp 1 "TestSupported" 0 "TestNotSupported" ;
VAL_ 2566835966 OxygenSensorMonSupp 1 "TestSupported" 0 "TestNotSupported" ;
VAL_ 2566835966 OxygenSensorHeaterMonSupp 1 "TestSupported" 0 "TestNotSupported" ;
VAL_ 2566835966 EGRSystemMonitoringSupp 1 "TestSupported" 0 "TestNotSupported" ;
VAL_ 2566835966 MisfireMonitoringStatus 1 "test not complete" 0 "test complete" ;
VAL_ 2566835966 ComprehensiveCompMonStatus 1 "test not complete" 0 "test complete" ;
VAL_ 2566835966 FuelSystemMonitoringStatus 1 "test not complete" 0 "test complete" ;
VAL_ 2566835966 ComprehensiveComponentMonSupp 3 "Not available" 2 "Reserved" 1 "test supported" 0 "test not supported" ;
VAL_ 2566835966 FuelSystemMonitoringSupport 1 "test supported" 0 "test not supported" ;
VAL_ 2566835710 FMI 24 "Assurance Data Error" 23 "Request DM60 for more info" 22 "Special Instructions #2 " 21 "Data drifted low" 20 "Data drifted high" 31 "Condition exists" 19 "Received network data in error" 18 "Below normal (moderately severe)" 17 "Below normal (least severe)" 16 "Above normal (moderately severe)" 15 "Above normal (least severe)" 14 "Special intstructions" 13 "Out of calibration" 12 "Bad intelligent device" 11 "Root cause not known" 10 "Abnormal rate of change" 9 "Abnormal update rate" 8 "Abnormal frequency" 7 "Mechanical system not responding" 6 "Current above normal" 5 "Current below normal" 4 "Voltage below normal" 3 "Voltage above normal" 2 "Data erratic" 1 "Below normal (most severe)" 0 "Above normal (most severe)" ;
VAL_ 2566835198 FMI5 24 "Assurance Data Error" 23 "Request DM60 for more info" 22 "Special Instructions #2 " 21 "Data drifted low" 20 "Data drifted high" 31 "Condition exists" 19 "Received network data in error" 18 "Below normal (moderately severe)" 17 "Below normal (least severe)" 16 "Above normal (moderately severe)" 15 "Above normal (least severe)" 14 "Special intstructions" 13 "Out of calibration" 12 "Bad intelligent device" 11 "Root cause not known" 10 "Abnormal rate of change" 9 "Abnormal update rate" 8 "Abnormal frequency" 7 "Mechanical system not responding" 6 "Current above normal" 5 "Current below normal" 4 "Voltage below normal" 3 "Voltage above normal" 2 "Data erratic" 1 "Below normal (most severe)" 0 "Above normal (most severe)" ;
VAL_ 2566835198 FMI4 24 "Assurance Data Error" 23 "Request DM60 for more info" 22 "Special Instructions #2 " 21 "Data drifted low" 20 "Data drifted high" 31 "Condition exists" 19 "Received network data in error" 18 "Below normal (moderately severe)" 17 "Below normal (least severe)" 16 "Above normal (moderately severe)" 15 "Above normal (least severe)" 14 "Special intstructions" 13 "Out of calibration" 12 "Bad intelligent device" 11 "Root cause not known" 10 "Abnormal rate of change" 9 "Abnormal update rate" 8 "Abnormal frequency" 7 "Mechanical system not responding" 6 "Current above normal" 5 "Current below normal" 4 "Voltage below normal" 3 "Voltage above normal" 2 "Data erratic" 1 "Below normal (most severe)" 0 "Above normal (most severe)" ;
VAL_ 2566835198 FMI3 24 "Assurance Data Error" 23 "Request DM60 for more info" 22 "Special Instructions #2 " 21 "Data drifted low" 20 "Data drifted high" 31 "Condition exists" 19 "Received network data in error" 18 "Below normal (moderately severe)" 17 "Below normal (least severe)" 16 "Above normal (moderately severe)" 15 "Above normal (least severe)" 14 "Special intstructions" 13 "Out of calibration" 12 "Bad intelligent device" 11 "Root cause not known" 10 "Abnormal rate of change" 9 "Abnormal update rate" 8 "Abnormal frequency" 7 "Mechanical system not responding" 6 "Current above normal" 5 "Current below normal" 4 "Voltage below normal" 3 "Voltage above normal" 2 "Data erratic" 1 "Below normal (most severe)" 0 "Above normal (most severe)" ;
VAL_ 2566835198 FMI2 24 "Assurance Data Error" 23 "Request DM60 for more info" 22 "Special Instructions #2 " 21 "Data drifted low" 20 "Data drifted high" 31 "Condition exists" 19 "Received network data in error" 18 "Below normal (moderately severe)" 17 "Below normal (least severe)" 16 "Above normal (moderately severe)" 15 "Above normal (least severe)" 14 "Special intstructions" 13 "Out of calibration" 12 "Bad intelligent device" 11 "Root cause not known" 10 "Abnormal rate of change" 9 "Abnormal update rate" 8 "Abnormal frequency" 7 "Mechanical system not responding" 6 "Current above normal" 5 "Current below normal" 4 "Voltage below normal" 3 "Voltage above normal" 2 "Data erratic" 1 "Below normal (most severe)" 0 "Above normal (most severe)" ;
VAL_ 2566835198 FMI1 24 "Assurance Data Error" 23 "Request DM60 for more info" 22 "Special Instructions #2 " 21 "Data drifted low" 20 "Data drifted high" 31 "Condition exists" 19 "Received network data in error" 18 "Below normal (moderately severe)" 17 "Below normal (least severe)" 16 "Above normal (moderately severe)" 15 "Above normal (least severe)" 14 "Special intstructions" 13 "Out of calibration" 12 "Bad intelligent device" 11 "Root cause not known" 10 "Abnormal rate of change" 9 "Abnormal update rate" 8 "Abnormal frequency" 7 "Mechanical system not responding" 6 "Current above normal" 5 "Current below normal" 4 "Voltage below normal" 3 "Voltage above normal" 2 "Data erratic" 1 "Below normal (most severe)" 0 "Above normal (most severe)" ;
VAL_ 2566835198 FlashRedStopLamp 3 "Unavailable / Do Not Flash" 2 "Reserved" 1 "Fast Flash" 0 "Slow Flash" ;
VAL_ 2566835198 FlashProtectLamp 3 "Unavailable / Do Not Flash" 2 "Reserved" 1 "Fast Flash" 0 "Slow Flash" ;
VAL_ 2566835198 FlashMalfuncIndicatorLamp 3 "Unavailable / Do Not Flash" 2 "Class C DTC  " 1 "Fast Flash" 0 "Slow Flash" ;
VAL_ 2566835198 FlashAmberWarningLamp 3 "Unavailable / Do Not Flash" 2 "Reserved" 1 "Fast Flash" 0 "Slow Flash" ;
VAL_ 2566835198 MalfunctionIndLampStatus 3 "Not available" 2 "Short MIL for WWH OBD" 1 "Lamp On" 0 "Lamp Off" ;
VAL_ 2566835198 AmberWarningLampStatus 3 "Not available" 2 "Reserved" 1 "Lamp On" 0 "Lamp Off" ;
VAL_ 2566835198 RedStopLampState 3 "Not available" 2 "Reserved" 1 "Lamp On" 0 "Lamp Off" ;
VAL_ 2566835198 ProtectLampStatus 0 "Lamp Off" 3 "Not available" 2 "Reserved" 1 "Lamp On" ;
VAL_ 2566834942 FMI5 24 "Assurance Data Error" 23 "Request DM60 for more info" 22 "Special Instructions #2 " 21 "Data drifted low" 20 "Data drifted high" 31 "Condition exists" 19 "Received network data in error" 18 "Below normal (moderately severe)" 17 "Below normal (least severe)" 16 "Above normal (moderately severe)" 15 "Above normal (least severe)" 14 "Special intstructions" 13 "Out of calibration" 12 "Bad intelligent device" 11 "Root cause not known" 10 "Abnormal rate of change" 9 "Abnormal update rate" 8 "Abnormal frequency" 7 "Mechanical system not responding" 6 "Current above normal" 5 "Current below normal" 4 "Voltage below normal" 3 "Voltage above normal" 2 "Data erratic" 1 "Below normal (most severe)" 0 "Above normal (most severe)" ;
VAL_ 2566834942 FMI4 24 "Assurance Data Error" 23 "Request DM60 for more info" 22 "Special Instructions #2 " 21 "Data drifted low" 20 "Data drifted high" 31 "Condition exists" 19 "Received network data in error" 18 "Below normal (moderately severe)" 17 "Below normal (least severe)" 16 "Above normal (moderately severe)" 15 "Above normal (least severe)" 14 "Special intstructions" 13 "Out of calibration" 12 "Bad intelligent device" 11 "Root cause not known" 10 "Abnormal rate of change" 9 "Abnormal update rate" 8 "Abnormal frequency" 7 "Mechanical system not responding" 6 "Current above normal" 5 "Current below normal" 4 "Voltage below normal" 3 "Voltage above normal" 2 "Data erratic" 1 "Below normal (most severe)" 0 "Above normal (most severe)" ;
VAL_ 2566834942 FMI3 24 "Assurance Data Error" 23 "Request DM60 for more info" 22 "Special Instructions #2 " 21 "Data drifted low" 20 "Data drifted high" 31 "Condition exists" 19 "Received network data in error" 18 "Below normal (moderately severe)" 17 "Below normal (least severe)" 16 "Above normal (moderately severe)" 15 "Above normal (least severe)" 14 "Special intstructions" 13 "Out of calibration" 12 "Bad intelligent device" 11 "Root cause not known" 10 "Abnormal rate of change" 9 "Abnormal update rate" 8 "Abnormal frequency" 7 "Mechanical system not responding" 6 "Current above normal" 5 "Current below normal" 4 "Voltage below normal" 3 "Voltage above normal" 2 "Data erratic" 1 "Below normal (most severe)" 0 "Above normal (most severe)" ;
VAL_ 2566834942 FMI2 24 "Assurance Data Error" 23 "Request DM60 for more info" 22 "Special Instructions #2 " 21 "Data drifted low" 20 "Data drifted high" 31 "Condition exists" 19 "Received network data in error" 18 "Below normal (moderately severe)" 17 "Below normal (least severe)" 16 "Above normal (moderately severe)" 15 "Above normal (least severe)" 14 "Special intstructions" 13 "Out of calibration" 12 "Bad intelligent device" 11 "Root cause not known" 10 "Abnormal rate of change" 9 "Abnormal update rate" 8 "Abnormal frequency" 7 "Mechanical system not responding" 6 "Current above normal" 5 "Current below normal" 4 "Voltage below normal" 3 "Voltage above normal" 2 "Data erratic" 1 "Below normal (most severe)" 0 "Above normal (most severe)" ;
VAL_ 2566834942 FMI1 24 "Assurance Data Error" 23 "Request DM60 for more info" 22 "Special Instructions #2 " 21 "Data drifted low" 20 "Data drifted high" 31 "Condition exists" 19 "Received network data in error" 18 "Below normal (moderately severe)" 17 "Below normal (least severe)" 16 "Above normal (moderately severe)" 15 "Above normal (least severe)" 14 "Special intstructions" 13 "Out of calibration" 12 "Bad intelligent device" 11 "Root cause not known" 10 "Abnormal rate of change" 9 "Abnormal update rate" 8 "Abnormal frequency" 7 "Mechanical system not responding" 6 "Current above normal" 5 "Current below normal" 4 "Voltage below normal" 3 "Voltage above normal" 2 "Data erratic" 1 "Below normal (most severe)" 0 "Above normal (most severe)" ;
VAL_ 2566834942 FlashRedStopLamp 3 "Unavailable / Do Not Flash" 2 "Reserved" 1 "Fast Flash" 0 "Slow Flash" ;
VAL_ 2566834942 FlashProtectLamp 3 "Unavailable / Do Not Flash" 2 "Reserved" 1 "Fast Flash" 0 "Slow Flash" ;
VAL_ 2566834942 FlashMalfuncIndicatorLamp 3 "Unavailable / Do Not Flash" 2 "Class C DTC  " 1 "Fast Flash" 0 "Slow Flash" ;
VAL_ 2566834942 FlashAmberWarningLamp 3 "Unavailable / Do Not Flash" 2 "Reserved" 1 "Fast Flash" 0 "Slow Flash" ;
VAL_ 2566834942 MalfunctionIndLampStatus 3 "Not available" 2 "Short MIL for WWH OBD" 1 "Lamp On" 0 "Lamp Off" ;
VAL_ 2566834942 AmberWarningLampStatus 3 "Not available" 2 "Reserved" 1 "Lamp On" 0 "Lamp Off" ;
VAL_ 2566834942 RedStopLampState 3 "Not available" 2 "Reserved" 1 "Lamp On" 0 "Lamp Off" ;
VAL_ 2566834942 ProtectLampStatus 0 "Lamp Off" 3 "Not available" 2 "Reserved" 1 "Lamp On" ;
VAL_ 2348820747 MessageCounter 14 "Reserved" 13 "Reserved" 12 "Reserved" 11 "Reserved" 10 "Reserved" 9 "Reserved" 8 "Reserved" 15 "Not Available" ;
VAL_ 2348820747 MessageChecksum 15 "Not Available" ;
VAL_ 2348820747 ControlPurpose 5 "TemporaryPowerTrainControl" 4 "EngineProtection" 3 "RoadSpeedGovernor" 2 "PTOGovernor" 1 "CruiseControl" 0 "AcceleratorPedal" ;
VAL_ 2348820747 TransmissionRate 7 "UseStandardRate" 6 "25ms" 5 "50ms" 4 "100ms" 3 "250ms" 2 "500ms" 1 "750ms" 0 "1000ms" ;
VAL_ 2348820747 OverrideCtrlModePriority 3 "LowPriority" 2 "MdmPrrtyUsdFrPwrtrnCtrlOprtnsWh" 1 "HighPriority" 0 "HghstPrrtyUsdFrSttnsThtRqrImmdt" ;
VAL_ 2348820747 EngRqedSpeedCtrlConditions 2 "ThsCtrlCndtnHsBnOptmzdTMnmzRpmO" 3 "StbltyOptmzdFrDrvlnEnggdAnd_OrI" 1 "StbltyOptmzdFrDrvlnDsnggdAndNnl" 0 "ThsSpdGvrnrGnSlctnIsAdjstdTPrvd" ;
VAL_ 2348820747 EngOverrideCtrlMode 3 "Spd_TrqLmtCtrlLmtSpdAnd_OrTrqBs" 2 "TrqCtrlCntrlTrqTInclddDsrdTrqVl" 1 "SpdCtrlGvrnSpdTInclddDsrdSpdVle" 0 "OvrrdDsbldDsblAnyExstngCtrlCmdd" ;
VAL_ 2348820747 EngineRequestedTorqueHiRes 15 "Not Available" 14 "Not Available" 13 "Not Available" 12 "Not Available" 11 "Not Available" 10 "Not Available" 9 "Not Available" 8 "Not Available" ;
VAL_ 2348875275 MessageCounter 14 "Reserved" 13 "Reserved" 12 "Reserved" 11 "Reserved" 10 "Reserved" 9 "Reserved" 8 "Reserved" 15 "Not Available" ;
VAL_ 2348875275 MessageChecksum 15 "Not Available" ;
VAL_ 2348875275 ControlPurpose 5 "TemporaryPowerTrainControl" 4 "EngineProtection" 3 "RoadSpeedGovernor" 2 "PTOGovernor" 1 "CruiseControl" 0 "AcceleratorPedal" ;
VAL_ 2348875275 TransmissionRate 7 "UseStandardRate" 6 "25ms" 5 "50ms" 4 "100ms" 3 "250ms" 2 "500ms" 1 "750ms" 0 "1000ms" ;
VAL_ 2348875275 OverrideCtrlModePriority 3 "LowPriority" 2 "MdmPrrtyUsdFrPwrtrnCtrlOprtnsWh" 1 "HighPriority" 0 "HghstPrrtyUsdFrSttnsThtRqrImmdt" ;
VAL_ 2348875275 EngRqedSpeedCtrlConditions 2 "ThsCtrlCndtnHsBnOptmzdTMnmzRpmO" 3 "StbltyOptmzdFrDrvlnEnggdAnd_OrI" 1 "StbltyOptmzdFrDrvlnDsnggdAndNnl" 0 "ThsSpdGvrnrGnSlctnIsAdjstdTPrvd" ;
VAL_ 2348875275 EngOverrideCtrlMode 3 "Spd_TrqLmtCtrlLmtSpdAnd_OrTrqBs" 2 "TrqCtrlCntrlTrqTInclddDsrdTrqVl" 1 "SpdCtrlGvrnSpdTInclddDsrdSpdVle" 0 "OvrrdDsbldDsblAnyExstngCtrlCmdd" ;
VAL_ 2348875275 EngineRequestedTorqueHiRes 15 "Not Available" 14 "Not Available" 13 "Not Available" 12 "Not Available" 11 "Not Available" 10 "Not Available" 9 "Not Available" 8 "Not Available" ;
VAL_ 2348810251 MessageCounter 14 "Reserved" 13 "Reserved" 12 "Reserved" 11 "Reserved" 10 "Reserved" 9 "Reserved" 8 "Reserved" 15 "Not Available" ;
VAL_ 2348810251 MessageChecksum 15 "Not Available" ;
VAL_ 2348810251 ControlPurpose 5 "TemporaryPowerTrainControl" 4 "EngineProtection" 3 "RoadSpeedGovernor" 2 "PTOGovernor" 1 "CruiseControl" 0 "AcceleratorPedal" ;
VAL_ 2348810251 TransmissionRate 7 "UseStandardRate" 6 "25ms" 5 "50ms" 4 "100ms" 3 "250ms" 2 "500ms" 1 "750ms" 0 "1000ms" ;
VAL_ 2348810251 OverrideCtrlModePriority 3 "LowPriority" 2 "MdmPrrtyUsdFrPwrtrnCtrlOprtnsWh" 1 "HighPriority" 0 "HghstPrrtyUsdFrSttnsThtRqrImmdt" ;
VAL_ 2348810251 EngRqedSpeedCtrlConditions 2 "ThsCtrlCndtnHsBnOptmzdTMnmzRpmO" 3 "StbltyOptmzdFrDrvlnEnggdAnd_OrI" 1 "StbltyOptmzdFrDrvlnDsnggdAndNnl" 0 "ThsSpdGvrnrGnSlctnIsAdjstdTPrvd" ;
VAL_ 2348810251 EngOverrideCtrlMode 3 "Spd_TrqLmtCtrlLmtSpdAnd_OrTrqBs" 2 "TrqCtrlCntrlTrqTInclddDsrdTrqVl" 1 "SpdCtrlGvrnSpdTInclddDsrdSpdVle" 0 "OvrrdDsbldDsblAnyExstngCtrlCmdd" ;
VAL_ 2348810251 EngineRequestedTorqueHiRes 15 "Not Available" 14 "Not Available" 13 "Not Available" 12 "Not Available" 11 "Not Available" 10 "Not Available" 9 "Not Available" 8 "Not Available" ;
VAL_ 2633935104 EngExhstGsOxygnSnsrClsdLpOprton 3 "DontCare_TakeNoAction" 2 "Reserved" 1 "CmdToEnableFunction" 0 "CmdToDisableFunction" ;
VAL_ 2565867787 SteerWheelAngleSensorType 3 "NotAvailable" 2 "Reserved" 1 "AbsMeasuringPrinciple" 0 "RelativeMeasuringPrinciple" ;
VAL_ 2566803211 YCBrakeCtrlActive 3 "DontCare_TakeNoAction" 2 "Reserved" 1 "YCBrakeCtrlActive" 0 "YCBrakeCtrlPassiveButInstalled" ;
VAL_ 2566803211 YCEngCtrlActive 3 "DontCare_TakeNoAction" 2 "Reserved" 1 "YCEngCtrlActive" 0 "YCEngCtrlPassiveButInstalled" ;
VAL_ 2566803211 ROPBrakeCtrlActive 3 "DontCare_TakeNoAction" 2 "Reserved" 1 "ROPBrakeCtrlActive" 0 "ROPBrakeCtrlPassiveButInstalled" ;
VAL_ 2566803211 ROPEngCtrlActive 3 "DontCare_TakeNoAction" 2 "Reserved" 1 "ROPEngCtrlActive" 0 "ROPEngCtrlPassiveButInstalled" ;
VAL_ 2566803211 VDCBrakeLightRq 3 "DontCare_TakeNoAction" 2 "Reserved" 1 "TurnBrakeLightOn" 0 "TurnBrakeLightNotOn" ;
VAL_ 2566803211 VDCFullyOperational 3 "DontCare_TakeNoAction" 2 "Reserved" 1 "FullyOperational" 0 "NotFullyOperational" ;
VAL_ 2566803211 VDCInformationSignal 3 "DontCare_TakeNoAction" 2 "Reserved" 1 "On" 0 "Off" ;
VAL_ 2348875518 MessageCounter 14 "Reserved" 13 "Reserved" 12 "Reserved" 11 "Reserved" 10 "Reserved" 9 "Reserved" 8 "Reserved" 15 "Not Available" ;
VAL_ 2348875518 MessageChecksum 15 "Not Available" ;
VAL_ 2348875518 ControlPurpose 5 "TemporaryPowerTrainControl" 4 "EngineProtection" 3 "RoadSpeedGovernor" 2 "PTOGovernor" 1 "CruiseControl" 0 "AcceleratorPedal" ;
VAL_ 2348875518 TransmissionRate 7 "UseStandardRate" 6 "25ms" 5 "50ms" 4 "100ms" 3 "250ms" 2 "500ms" 1 "750ms" 0 "1000ms" ;
VAL_ 2348875518 OverrideCtrlModePriority 3 "LowPriority" 2 "MdmPrrtyUsdFrPwrtrnCtrlOprtnsWh" 1 "HighPriority" 0 "HghstPrrtyUsdFrSttnsThtRqrImmdt" ;
VAL_ 2348875518 EngRqedSpeedCtrlConditions 2 "ThsCtrlCndtnHsBnOptmzdTMnmzRpmO" 3 "StbltyOptmzdFrDrvlnEnggdAnd_OrI" 1 "StbltyOptmzdFrDrvlnDsnggdAndNnl" 0 "ThsSpdGvrnrGnSlctnIsAdjstdTPrvd" ;
VAL_ 2348875518 EngOverrideCtrlMode 3 "Spd_TrqLmtCtrlLmtSpdAnd_OrTrqBs" 2 "TrqCtrlCntrlTrqTInclddDsrdTrqVl" 1 "SpdCtrlGvrnSpdTInclddDsrdSpdVle" 0 "OvrrdDsbldDsblAnyExstngCtrlCmdd" ;
VAL_ 2348875518 EngineRequestedTorqueHiRes 15 "Not Available" 14 "Not Available" 13 "Not Available" 12 "Not Available" 11 "Not Available" 10 "Not Available" 9 "Not Available" 8 "Not Available" ;
VAL_ 2566841344 EngOverspeedTest 3 "NotAvailable" 2 "Reserved" 1 "EngOverspeedTestActive" 0 "EngOverspeedTestNotActive" ;
VAL_ 2566841344 EngAirShutoffCmdStatus 0 "ArShtffDsbldNtAttmptngTShtffEng" 3 "NotAvailable" 2 "Reserved" 1 "ArShtffEnbldAttmptngTShtffEngAr" ;
VAL_ 2566841344 EngAlarmOutputCmdStatus 3 "NotAvailable" 2 "Reserved" 1 "EngAlarmOutputCmdActive" 0 "EngAlarmOutputCmdNotActive" ;
VAL_ 2566841344 EngAlarmAcknowledge 3 "NotAvailable" 2 "Error" 1 "EngAlarmAcknowledgeActive" 0 "EngAlarmAcknowledgeNotActive" ;
VAL_ 2566841344 EngProtectionSystemConfig 3 "NotAvailable" 2 "Error" 1 "EnabledInCalib" 0 "DisabledInCalib" ;
VAL_ 2566841344 EngProtectionSystemTimerState 3 "NotAvailable" 2 "Error" 1 "Active" 0 "Inactive" ;
VAL_ 2566841344 EngPrtectionSystemTimerOverride 3 "NotAvailable" 2 "Error" 1 "Active" 0 "Inactive" ;
VAL_ 2566841344 EngPrtctnSystmApprchingShutdown 3 "NotAvailable" 2 "Error" 1 "Approaching" 0 "NotApproaching" ;
VAL_ 2566841344 EngPrtctionSystemHasShutdownEng 0 "No" ;
VAL_ 2566841344 EngWaitToStartLamp 3 "NotAvailable" 2 "Error" 1 "On" 0 "Off" ;
VAL_ 2566841344 RefrigerantHighPressSwitch 3 "NotAvailable" 2 "Error" 1 "PrssTHghCmprssrCltchMyBDsngaged" 0 "PressNormal" ;
VAL_ 2566841344 RefrigerantLowPressSwitch 3 "NotAvailable" 2 "Error" 1 "PrssTLwCmprssrCltchMyBDsengaged" 0 "PressNormal" ;
VAL_ 2566841344 A_CHighPressFanSwitch 3 "NotAvailable" 2 "Error" 1 "PressHighFanMayBeEngaged" 0 "PressNormal" ;
VAL_ 2566841344 EngIdleShutdownTimerFunction 3 "NotAvailable" 2 "Error" 1 "EnabledInCalib" 0 "DisabledInCalib" ;
VAL_ 2566841344 EngIdleShutdownTimerState 3 "NotAvailable" 2 "Error" 1 "Active" 0 "Inactive" ;
VAL_ 2566841344 EngIdleShutdownTimerOverride 3 "NotAvailable" 2 "Error" 1 "Active" 0 "Inactive" ;
VAL_ 2566841344 EngIdleShutdownDriverAlertMode 3 "NotAvailable" 2 "Error" 1 "Active" 0 "Inactive" ;
VAL_ 2566841344 EngIdleShutdownHasShutdownEng 1 "Yes" 0 "No" ;
VAL_ 2566844416 OperatorPTOMemorySelectSwitch 3 "notAvailable" 2 "error" 1 "PTOSetSpeedMemory2Selected" 0 "PTOSetSpeedMemory1Selected" ;
VAL_ 2566844416 EngPTOAccelerateSwitch 3 "NotAvailable" 2 "Error" 1 "On" 0 "Off" ;
VAL_ 2566844416 EngPTOResumeSwitch 3 "NotAvailable" 2 "Error" 1 "On" 0 "Off" ;
VAL_ 2566844416 EngPTOCoast_DecelerateSwitch 3 "NotAvailable" 2 "Error" 1 "On" 0 "Off" ;
VAL_ 2566844416 EngPTOSetSwitch 3 "NotAvailable" 2 "Error" 1 "On" 0 "Off" ;
VAL_ 2566844416 EngRmtPTOVriableSpeedCtrlSwitch 3 "NotAvailable" 2 "Error" 1 "On" 0 "Off" ;
VAL_ 2566844416 EngRmtPTOPrprgrmmdSpdCtrlSwitch 3 "NotAvailable" 2 "Error" 1 "On" 0 "Off" ;
VAL_ 2566844416 EngPTOEnableSwitch 3 "NotAvailable" 2 "Error" 1 "On" 0 "Off" ;
VAL_ 2566844416 RmtPTOPrprgrmmdSpeedCtrlSwitch2 3 "NotAvailable" 2 "Error" 1 "On" 0 "Off" ;
VAL_ 2566844416 AuxInputIgnoreSwitch 3 "NotAvailable" 2 "Error" 1 "On" 0 "Off" ;
VAL_ 2566831360 FanDriveState 15 "NotAvailable" 14 "Other" 13 "EngBrake" 12 "Timer" 11 "A_CSystem" 10 "TransRetarder" 9 "ManualCtrl" 8 "NotDefined" 7 "DefaultOperation" 6 "ExcessiveHydOilTemp" 5 "ExcessiveTransOilTemp" 4 "ExcessiveEngCoolantTemp" 3 "ExcessiveEngOilTemp" 2 "ExcessiveEngAirTemp" 1 "EngSystemGeneral" 0 "FanOff" ;
VAL_ 2364539648 VhclAccelerationRateLimitStatus 3 "NotAvailable" 2 "Reserved" 1 "LimitActive" 0 "LimitNotActive" ;
VAL_ 2364539648 AccelPedal2LowIdleSwitch 3 "NotAvailable" 2 "Error" 1 "AccelPedal2InLowIdleCondition" 0 "AcclPedal2NotInLowIdleCondition" ;
VAL_ 2364539648 RoadSpeedLimitStatus 3 "NotAvailable" 2 "Error" 1 "NotActive" 0 "Active" ;
VAL_ 2364539648 AccelPedalKickdownSwitch 3 "NotAvailable" 2 "Error" 1 "KickdownActive" 0 "KickdownPassive" ;
VAL_ 2364539648 AccelPedal1LowIdleSwitch 3 "NotAvailable" 2 "Error" 1 "AccelPedal1InLowIdleCondition" 0 "AcclPedal1NotInLowIdleCondition" ;
VAL_ 2364539904 EngStarterMode 15 "notAvailable" 14 "error" 12 "starterInhibitedReasonUnknown" 9 "1011Reserved" 8 "strtrInhbtdDueToStarterOvertemp" 7 "strtrInhbtdDToActiveImmobilizer" 6 "strtrInhbtdDTDrvlnEnggdOthrTrns" 5 "strtrInhbtdDTEngNtReadyForStart" 4 "strtrInhbtdDToEngAlreadyRunning" 3 "strtFnshdStrtrNtActvAftrHvngBnA" 2 "starterActiveGearEngaged" 1 "starterActiveGearNotEngaged" 0 "startNotRqed" ;
VAL_ 2364539904 EngTorqueMode 15 "Not available" 11 "Remote accelerator" 10 "Braking system" 9 "High speed governor" 8 "Torque limiting" 7 "ABS control" 6 "Transmission control" 5 "ASR control" 4 "Road speed governor" 3 "PTO governor" 2 "Cruise control" 1 "Accelerator pedal/operator selec" 0 "Low idle governor/no request (de" ;
VAL_ 2566841088 SupportTSC1CtrlPurposeGroup4Of4 1 "P25ReservedForAssignmentBySAE" ;
VAL_ 2566841088 SupportVariableRateTSC1Message 1 "MsTransRate" ;
VAL_ 2566841088 SupportTSC1CtrlPurposeGroup3Of4 1 "P17ReservedForAssignmentBySAE" ;
VAL_ 2566841088 SupportTSC1CtrlPurposeGroup2Of4 1 "P9ReservedForAssignmentBySAE" ;
VAL_ 2566841088 SupportTSC1CtrlPurposeGroup1Of4 1 "P1AccelPedal_OperatorSelection" ;
VAL_ 2566767627 BrakeTempWarning 3 "notAvailable" 2 "Reserved" 1 "Active" 0 "NotActive" ;
VAL_ 2566767627 XBRActiveCtrlMode 15 "NotAvailable" 4 "1110ReservedForSAEAssignment" 3 "MxMdOfXBRAcclrtnCtrlBngExecuted" 2 "AddtnMdOfXBRAcclrtnCtrlBngExctd" 1 "DrvrsBrkDmndBngExctdNExtlBrkDmn" 0 "NoBrakeDemandBeingExecuted" ;
VAL_ 2566767627 XBRSystemState 3 "NotAvailable" 2 "NoExtlBrakeDemandWillBeAccepted" 1 "OnlyExtlBrkDmndOfHghstXBRPrrtyW" 0 "AnyExtlBrkeDemandWillBeAccepted" ;
VAL_ 2566767627 FoundationBrakeUse 3 "NotAvailable" 2 "Reserved" 1 "FoundationBrakesInUse" 0 "FoundationBrakesNotInUse" ;
VAL_ 2566767627 HillHolderMode 7 "NotAvailable" 6 "Reserved" 3 "101NotDefined" 2 "ActvBtWllChngTInctvInAShortTime" 1 "Active" 0 "Inactive" ;
VAL_ 2566767627 HaltBrakeMode 7 "NotAvailable" 6 "Reserved" 3 "101NotDefined" 2 "ActiveButNotFunctioningProperly" 1 "Active" 0 "Inactive" ;
VAL_ 2565865739 TrctrMntdTrilerABSWarningSignal 3 "TakeNoAction" 2 "Reserved" 1 "On" 0 "Off" ;
VAL_ 2565865739 TrailerABSStatus 3 "TrlrABSSttsInfrmtnNtAvlblPrmtrN" 2 "Reserved" 1 "TrailerABSActive" 0 "TrlrABSSttsInfrmtnAvlblBtNtActv" ;
VAL_ 2565865739 HaltBrakeSwitch 3 "NotAvailable" 2 "Error" 1 "HaltBrakeSwitchActive" 0 "HaltBrakeSwitchPassive" ;
VAL_ 2565865739 ATC_ASRInformationSignal 3 "TakeNoAction" 2 "Reserved" 1 "On" 0 "Off" ;
VAL_ 2565865739 ABS_EBSAmberWarningSignal 3 "TakeNoAction" 2 "Reserved" 1 "On" 0 "Off" ;
VAL_ 2565865739 EBSRedWarningSignal 3 "TakeNoAction" 2 "Reserved" 1 "On" 0 "Off" ;
VAL_ 2565865739 ABSFullyOperational 3 "NotAvailable" 2 "Reserved" 1 "FullyOperational" 0 "NotFullyOperational" ;
VAL_ 2565865739 RemoteAccelEnableSwitch 3 "NotAvailable" 2 "Error" 1 "On" 0 "Off" ;
VAL_ 2565865739 EngAuxEngShutdownSwitch 3 "NotAvailable" 2 "Error" 1 "On" 0 "Off" ;
VAL_ 2565865739 EngDerateSwitch 3 "NotAvailable" 2 "Error" 1 "On" 0 "Off" ;
VAL_ 2565865739 AccelInterlockSwitch 3 "NotAvailable" 2 "Error" 1 "On" 0 "Off" ;
VAL_ 2565865739 TractionCtrlOverrideSwitch 3 "NotAvailableNotInstalled" 2 "Error" 1 "On" 0 "Off" ;
VAL_ 2565865739 ASRHillHolderSwitch 3 "NotAvailable" 2 "Error" 1 "ASRHillHolderSwitchActive" 0 "ASRHillHolderSwitchPassive" ;
VAL_ 2565865739 ASROffroadSwitch 2 "Error" 1 "ASROffroadSwitchActive" 0 "ASROffroadSwitchPassive" 3 "NotAvailable" ;
VAL_ 2565865739 ABSOffroadSwitch 3 "NotAvailable" 2 "Error" 1 "ABSOffroadSwitchActive" 0 "ABSOffroadSwitchPassive" ;
VAL_ 2565865739 EBSBrakeSwitch 3 "NotAvailable" 2 "Error" 1 "BrakePedalIsBeingPressed" 0 "BrakePedalIsNotBeingPressed" ;
VAL_ 2565865739 AntiLockBrakingActive 3 "NotAvailable" 2 "Reserved" 1 "ABSActive" 0 "ABSPassiveButInstalled" ;
VAL_ 2565865739 ASRBrakeCtrlActive 3 "NotAvailable" 2 "Reserved" 1 "ASRBrakeCtrlActive" 0 "ASRBrakeCtrlPassiveButInstalled" ;
VAL_ 2565865739 ASREngCtrlActive 3 "NotAvailable" 2 "Reserved" 1 "ASREngCtrlActive" 0 "ASREngCtrlPassiveButInstalled" ;
VAL_ 2566844672 ParkBrakeReleaseInhibitRq 3 "Unavailable" 2 "SAEReserved" 1 "ParkBrakeReleaseInhibitRqed" 0 "ParkBrakeReleaseInhibitNotRqed" ;
VAL_ 2566844672 EngShutdownOverrideSwitch 3 "NotAvailable" 2 "Error" 1 "On" 0 "Off" ;
VAL_ 2566844672 EngTestModeSwitch 3 "NotAvailable" 2 "Error" 1 "On" 0 "Off" ;
VAL_ 2566844672 EngIdleDecrementSwitch 3 "NotAvailable" 2 "Error" 1 "On" 0 "Off" ;
VAL_ 2566844672 EngIdleIncrementSwitch 3 "NotAvailable" 2 "Error" 1 "On" 0 "Off" ;
VAL_ 2566844672 PTOState 31 "NotAvailable" 20 "11110NotDefined" 19 "PTOSetSpeedMemory2" 18 "PTOSetSpeedMemory1" 17 "PreprogrammedSetSpeed8" 16 "PreprogrammedSetSpeed7" 15 "PreprogrammedSetSpeed6" 14 "PreprogrammedSetSpeed5" 13 "PreprogrammedSetSpeed4" 12 "PreprogrammedSetSpeed3" 11 "PreprogrammedSetSpeed2" 10 "PreprogrammedSetSpeed1" 9 "AccelOverride" 8 "Accelerate" 7 "Resume" 6 "Decelerate_Coast" 5 "Set" 4 "RemoteStandby" 3 "Standby" 2 "RemoteHold" 1 "Hold" 0 "Off_Disabled" ;
VAL_ 2566844672 CruiseCtrlAccelerateSwitch 3 "NotAvailable" 2 "Error" 1 "CrsCtrlActivatorInPosAccelerate" 0 "CrsCtrlActvtrNotInPosAccelerate" ;
VAL_ 2566844672 CruiseCtrlResumeSwitch 3 "NotAvailable" 2 "Error" 1 "CruiseCtrlActivatorInPosResume" 0 "CrseCtrlActivatorNotInPosResume" ;
VAL_ 2566844672 CruiseCtrlCoastSwitch 3 "NotAvailable" 2 "Error" 1 "CruiseCtrlActivatorInPosCoast" 0 "CriseCtrlActivatorNotInPosCoast" ;
VAL_ 2566844672 CruiseCtrlSetSwitch 3 "NotAvailable" 2 "Error" 1 "CruiseCtrlActivatorInPosSet" 0 "CruiseCtrlActivatorNotInPosSet" ;
VAL_ 2566844672 ClutchSwitch 3 "NotAvailable" 2 "Error" 1 "ClutchPedalDepressed" 0 "ClutchPedalReleased" ;
VAL_ 2566844672 BrakeSwitch 3 "NotAvailable" 2 "Error" 1 "BrakePedalDepressed" 0 "BrakePedalReleased" ;
VAL_ 2566844672 CruiseCtrlEnableSwitch 3 "NotAvailable" 2 "Error" 1 "CruiseCtrlEnabled" 0 "CruiseCtrlDisabled" ;
VAL_ 2566844672 CruiseCtrlActive 3 "NotAvailable" 2 "Error" 1 "CruiseCtrlSwitchedOn" 0 "CruiseCtrlSwitchedOff" ;
VAL_ 2566844672 CruiseCtrlPauseSwitch 3 "TakeNoAction" 2 "ErrorIndicator" 1 "On" 0 "Off" ;
VAL_ 2566844672 ParkingBrakeSwitch 3 "NotAvailable" 2 "Error" 1 "ParkingBrakeSet" 0 "ParkingBrakeNotSet" ;
VAL_ 2566844672 TwoSpeedAxleSwitch 3 "NotAvailable" 2 "Error" 1 "HighSpeedRange" 0 "LowSpeedRange" ;
VAL_ 2565799678 IndustryGroup 6 "Reserved for SAE" 7 "Reserved for SAE" 5 "IndustrialProcessCtrlStationary" 4 "Marine" 3 "Construction" 2 "Agricultural and Forestry" 1 "On-Highway" 0 "Global" ;
VAL_ 2565799678 Function 127 "Reserved" 126 "Reserved" 125 "Reserved" 124 "Reserved" 123 "Reserved" 122 "Reserved" 121 "Reserved" 120 "Reserved" 119 "Reserved" 118 "Reserved" 117 "Reserved" 116 "Reserved" 115 "Reserved" 114 "Reserved" 113 "Reserved" 112 "Reserved" 111 "Reserved" 110 "Reserved" 109 "Reserved" 108 "Reserved" 107 "Reserved" 106 "Reserved" 105 "Reserved" 104 "Reserved" 103 "Reserved" 102 "Reserved" 101 "Reserved" 42 "Water Pump Control" 41 "Lighting - Operator Controls" 40 "Seat Control" 39 "Ignition Control Module" 38 "Tire Pressure Control" 37 "Cab Controller" 36 "Pneumatic - System Controller" 35 "Suspension - System Controller" 34 "Hydraulic Pump Controller" 33 "System Monitor" 32 "Headway Controller" 31 "Propulsion Battery Charger" 30 "Management Computer" 29 "Virtual Terminal (In Cab)" 28 "Off Vehicle Gateway" 27 "Power TakeOff (Secondary or Front)" 26 "Body Controller" 25 "Network Interconnect ECU" 24 "Vehicle Security" 23 "Vehicle Navigation" 22 "Aerodynamic Control" 21 "Cab Climate Control" 20 "Trip Recorder" 19 "Instrument Cluster" 18 "Suspension - Drive Axle" 17 "Suspension - Steer Axle" 16 "Steeting Controller" 15 "Fuel System" 14 "Cruise Control" 13 "Retarder - Driveline" 12 "Retarder - Engine" 11 "Brakes - Drive Axle" 10 "Brakes - Steer Axle" 9 "Brakes - System Controller" 8 "Axle - Drive" 7 "Axle - Steering" 6 "Power TakeOff - (Main or Rear)" 5 "Shift Control/Console" 4 "Battery Pack Monitor" 3 "Transmission" 2 "Electric Propulsion Control" 1 "Auxiliary Power Unit (APU)" 0 "Engine" 100 "Reserved" 99 "Reserved" 98 "Reserved" 97 "Reserved" 96 "Reserved" 95 "Reserved" 94 "Reserved" 93 "Reserved" 92 "Reserved" 91 "Reserved" 90 "Reserved" 89 "Reserved" 88 "Reserved" 87 "Reserved" 86 "Reserved" 85 "Reserved" 84 "Reserved" 83 "Reserved" 82 "Reserved" 81 "Reserved" 80 "Reserved" 79 "Reserved" 78 "Reserved" 77 "Reserved" 76 "Reserved" 75 "Reserved" 74 "Reserved" 73 "Reserved" 72 "Coolant Valve Controller" 71 "Transfer Case Control" 70 "Auxiliary Regeneration Device" 69 "Engine Emission Aftertreatement System" 68 "Aftertreatment system gas measurement" 67 "Electrical System Controller" 66 "I/O Controller" 65 "Gas Flow Measurement" 64 "Endurance Braking" 63 "Engine Valve Controller" 62 "On-Board Diagnostic Unit" 61 "File Server/Printer" 60 "Cab Display" 59 "Starter" 58 "Fan Drive Control" 57 "Steering Column Unit" 56 "Communications Unit, Radio" 55 "Communications Unit, Satellite" 54 "Communications Unit, Cellular" 53 "Alternator/Charging System" 52 "Chassis Controller" 51 "Forward-Looking Collision Warning System" 50 "Auxiliary Heater" 49 "Clutch/Converter Control" 48 "Ramp Control" 47 "Information System Controller" 46 "Oil Sensor Unit" 45 "Vehicle Dynamic Stability Control" 44 "Exhaust Emission Control" 43 "Transmission Display" ;
VAL_ 2565799678 ManufacturerCode 252 "Sensor-Technik Wiedemann GmbH" 251 "German Agricultural Society" 250 "Kuhn Group" 249 "Schaltbau GmbH" 233 "Yacht Monitoring Solutions Inc." 232 "TSD Integrated Controls" 1863 "Thomas G. Faria Co." 1862 "Sanshin" 1861 "Vector CANtech" 1860 "MMP" 1859 "Kvasar AB" 1858 "Litton" 1857 "Simrad" 1856 "Trimble" 1855 "Furuno USA" 1854 "Northstar Technologies" 1853 "Japan Radio Co." 1852 "Navionics" 1851 "Raymarine" 1850 "Teleflex" 222 "Generac Power Systems, Inc." 221 "SiE" 220 "Beede Electrical Instrument Company, Inc." 219 "Cat OEM Solutions" 218 "Gits Manufacturing Company" 217 "RM Michaelides Software & Elektronik GmbH" 216 "Paneltronics Inc." 215 "Aetna Engineering/Fireboy-Xintex" 214 "MC elettronica Srl" 213 "CNH Belgium N.V." 212 "Sure Power Industries, Inc." 211 "DNA Group" 210 "Iteris, Inc." 209 "Bell Equip. Co. SA (PTY) LTD" 208 "Drew Technologies, Inc." 207 "Otto Engineering" 206 "port GmbH" 205 "SmarTire Systems Inc" 204 "The Morey Corporation" 203 "MILtronik GmbH" 202 "Curtis Instruments, Inc." 201 "Disenos y Tecnologia S.A." 200 "MGM Brakes" 199 "Actia Corp." 198 "Mystic Valley Communications" 197 "Mechron Power Systems" 196 "LEMKEN GmbH & Co. KG" 195 "General Engine Products" 194 "TriMark Corporation" 193 "Jeppesen Marine" 192 "Floscan" 191 "XATA Corporation" 190 "Hella KGaA Hueck & Co." 189 "QUALCOMM" 188 "EMP Corp." 187 "Air-Weigh" 186 "Altronic, Inc." 185 "Beede Electrical Instrument Company" 184 "EIA Electronics" 183 "KDS Controls, Inc." 182 "Vehicle Systems Engineering B.V." 181 "Coretronics, Inc." 180 "Smart Power Systems" 179 "Midwest Technologies Illinois, LLC" 178 "Siemens VDO Automotive AG" 177 "Diagnostic System Associates" 176 "Moritz Aerospace" 175 "Veris Technologies, Inc." 174 "AB Volvo Penta" 173 "Ryeso, Inc." 172 "Yanmar Marine USA" 171 "Wachendorff Elektronik GmbH & Co. KG" 170 "Computronics Corporation Ltd." 169 "Marlin Technologies Inc." 168 "Xantrex" 167 "JLG Industries Inc." 166 "Phoenix International" 165 "CPAC Systems AB" 164 "DaimlerChrysler Off-Highway" 163 "BRP Inc." 162 "Axiomatic Technologies" 161 "Offshore Systems (UK) Limited" 160 "Nido" 159 "NTech Industries Inc." 158 "Firestone Industrial Products Company" 157 "ISSPRO Inc." 156 "ITT Industries - Cannon" 155 "Vetronix Corporation" 154 "Westerbeke Corporation" 153 "Woodward, Industrial Controls Division" 152 "Elobau Elektrobauelemente GmbH & Co. KG" 151 "Raven Industries Inc. - Flow Controls Division" 150 "Fleetguard" 149 "Holset" 148 "Blue Water Data, Inc." 147 "Nautibus Electronic GmbH" 146 "Maxima Technologies" 145 "MurCal Controls" 144 "Mercury Marine" 143 "W. Gmeiner GmbH & Co." 142 "TRW Automotive (Commercial Steering Systems)" 141 "Thales Navigation Ltd." 140 "Lowrance Electronics, Inc." 139 "Caterpillar Trimble Control Technologies (CTCT), LLC" 138 "Georg Fritzmeier GmbH & Co. KG" 137 "Maretron" 136 "Komatsu Ltd." 135 "Airmar Technology Corporation" 134 "Iris Technology Ltd." 133 "Bucher Schoerling GmbH" 132 "Mulag-Fahrzeugwerk" 131 "ITT Industries" 130 "Nido - Universal Machines B.V." 129 "OMNEX Control Systems, Inc." 128 "Gerhard Duecker GmbH & Co. KG" 127 "Holland USA" 126 "Driver Tech" 125 "Nevada Automotive Test Center" 124 "Hydac Electronic" 123 "Basler Electric" 122 "FG Wilson (Engineering) Limited" 121 "HED (Hydro Electronic Devices, Inc.)" 120 "RDS Technology Ltd." 119 "IntegriNautics" 118 "Intron GmbH" 117 "HUSCO International" 116 "BEELINE Technologies" 115 "NACCO Materials Handling Group, Inc." 114 "EControls, Inc." 113 "Stress-Tek, Inc." 112 "MECALAC" 111 "Maschinenfabrik Bernhard Krone GmbH" 110 "EPIQ Sensor-Nite" 109 "LH Technologies ApS" 108 "WTK-Elecktronik GmbH" 107 "Grimme Landmaschinen GmbH & Co. KG" 106 "BAE Systems Controls, Inc." 105 "Kiepe Elektrik GmbH & Co. KG" 104 "Claas Selbstfahrende Erntemaschinen GmbH" 103 "Agrocom GmbH & Co. Agrarsystem KG" 102 "AGCO GmbH & Co." 101 "Sensoria" 100 "VDO Technik AG" 99 "International Transmissions Ltd (ITL)" 98 "Mueller-Elektronik GmbH & Co." 97 "Ag Leader Technology, Inc." 96 "Mech@tronic IT GmbH" 95 "Pacific Insight Electronics Corp." 94 "CNH Global N.V." 93 "Perkins Engines Company Ltd." 92 "Ag-Chem Equipment Co., Inc." 91 "BSG Bodensee Steuergeraete GmbH" 90 "Knorr-Bremse SfN GmbH" 89 "Kverneland Group, Electronics Division" 88 "Satloc Precision GPS" 87 "J.C. Bamford Excavators Ltd (JCB)" 86 "C.E. Niehoff & Company" 85 "Kohler Co." 84 "New Holland UK Limited" 83 "Eaton VORAD Technologies" 82 "Bobcat/Ingersoll-Rand" 81 "Fire Research Corp" 80 "Twin Disc, Inc." 79 "Daimler Benz AG - Engine Division (PBM)" 78 "Frank W. Murphy Manufacturing, Inc." 77 "Deere Power Systems Group" 76 "unused" 75 "Deere & Co. Agricultural Division" 74 "Eaton Axle-Brake Division" 73 "LeTourneau, Inc." 72 "Sisu Corporation" 71 "Vansco Electronics Ltd." 70 "Flex-Coil Limited" 69 "Trimble Navigation" 68 "Scania" 67 "Funk Manufacturing Company" 66 "John Deere Construction Equipment Division" 65 "MAN Nutzfahrzeuge AG" 64 "unused" 63 "ZF Industries Inc." 62 "Wabco" 61 "Volvo Truck Corp." 60 "Volvo Trucks North America Inc." 59 "VES Inc." 58 "SPX Corporation, OTC Division" 57 "Sauer-Danfoss Co." 56 "SAIC" 55 "Ryder System Inc." 54 "Meritor Wabco" 53 "Rockwell Land Transportation" 52 "Meritor Automotive, Inc." 51 "Robert Bosch GmbH" 50 "Robert Bosch Corp" 49 "RE America Inc." 48 "Pollak Alphabet" 47 "Phillips Semiconductor" 46 "Parasoft Computing Solutions" 45 "PACCAR" 44 "Nippondenso Co. Ltd." 43 "International Truck and Engine Corp. Vehicle Electronics" 42 "International Truck and Engine Corp. Engine Electronics" 41 "Motorola Inc." 40 "Motorola AIEG Inc." 39 "Microfirm Inc." 38 "Micro Processor Systems Inc." 37 "Mack Trucks Inc." 36 "Lucas Ltd." 35 "Kenworth Truck Co." 34 "Kelsey Hayes Co." 33 "John Deere" 32 "Jacobs Vehicle Systems" 31 "J Pollak Corp." 30 "Isuzu Motors Ltd." 29 "Hino Motors Ltd." 28 "Grote Ind. Inc." 27 "GMC" 26 "General Motors Corp., Service Technology Group" 25 "Freightliner LLC" 24 "Ford Motor Co., Vehicle Controls" 23 "Ford Motor Co., Heavy Truck" 22 "Ford Motor Co., Electronic Concepts $ Systems" 21 "Echilin Inc., Midland Brake Inc." 20 "Eaton Ltd" 19 "Eaton Corp. Trucking Info Services" 18 "Eaton Corp, Transmission Division" 17 "Eaton Corp. Res & Dev" 16 "Eaton Corp." 15 "Dickey-John Corp." 14 "Detroit Diesel Corporation" 13 "Delco Electronics" 12 "Deere & Company, Precision Farming" 11 "Dearborn Group Inc." 10 "Cummins Engine Co." 9 "Chrysler Corp." 8 "Caterpillar Inc." 7 "Case Corp." 6 "Berifors Electronics AB" 5 "AMP Inc." 4 "Ametek-Dixson" 3 "Ametek, US Gauge Division" 2 "Allison Transmission, GMC" 1 "Allied Signal Inc." 0 "Reserved" 231 "Topcon Positioning Systems, Inc." 230 "Saucon Technologies" 229 "Garmin International Inc." 228 "ZF Marine Electronics" 227 "Lykketronic A/S" 226 "Monaco Coach Corporation" 225 "SKF" 224 "EMMI Network, S.L." 223 "Vaueo Retarder Co., Ltd." 263 "IMMI" 262 "HydraForce, Inc" 261 "Red Dot Corporation" 260 "Reichhardt GmbH" 259 "Jetter AG" 258 "ARAG" 257 "Honda Motor Co., Ltd" 256 "Tyco Electronics AMP" 255 "MEAS France" 254 "GE Sensing" 253 "Mobile Control Systems" ;
VAL_ 2565799678 VehicleSystem 0 "Non-specific System" 127 "Not Available" ;
VAL_ 2565799678 VehicleSystem5 127 "Not Available" 0 "Ind. Process Control Stationary" ;
VAL_ 2565799678 VehicleSystem4 100 "Deck/Cargo/Fishing equip. sys" 90 "Environmental (HVAC) Systems" 80 "Instrumentation/General Systems" 70 "Communications Systems" 60 "Navigation Systems" 50 "Propulsion Systems" 40 "Steering Systems" 30 "Power Mgmt and lighting systems" 25 "Gateway" 20 "Safety Systems" 10 "System Tools" 127 "Not Available" 0 "Non-specific System" ;
VAL_ 2565799678 VehicleSystem3 8 "Grader" 7 "Four Wheel Drive Loader" 6 "Forklift" 5 "Excavator" 4 "Crawler" 3 "Backhoe" 2 "Articulated Dump Truck" 1 "Skid Steer Loader" 127 "Not Available" 0 "Non-specific System" ;
VAL_ 2565799678 VehicleSystem2 16 "Skidder" 15 "Earth Work" 14 "Special Crops" 13 "Powered Auxiliary Device" 12 "Farm Yard Operations" 11 "Transport/Trailer" 10 "Irrigation" 9 "Forage" 8 "Root Harvesters" 7 "Harvesters" 6 "Sprayers" 5 "Fertilizers" 4 "Planters/Seeders" 3 "Secondary Tillage" 2 "Tillage" 1 "Tractor" 127 "Not Available" 0 "Non-specific System" ;
VAL_ 2565799678 VehicleSystem1 2 "Trailer" 1 "Tractor" 127 "Not Available" 0 "Non-specific System" ;
VAL_ 2565668606 PGNumber 255 "NotAvailable" ;
VAL_ 2565668606 ControlByte 24 "EAbort" 23 "EEoMACK" 22 "EDPO" 21 "ECTS" 20 "ERTS" 255 "Abort" 32 "BAM" 19 "EoMA" 17 "CTS" 16 "RTS" ;
VAL_ 2563374846 UseTransferMode 3 "NA" 2 "Undefined" 1 "Yes" 0 "No" ;
VAL_ 2565406462 ControlByte 3 "CannotRespond" 2 "AccessDenied" 1 "NACK" 0 "ACK" ;
